VERSION ""

NS_ :

BS_:

BU_: BCM NAB NVO SGW

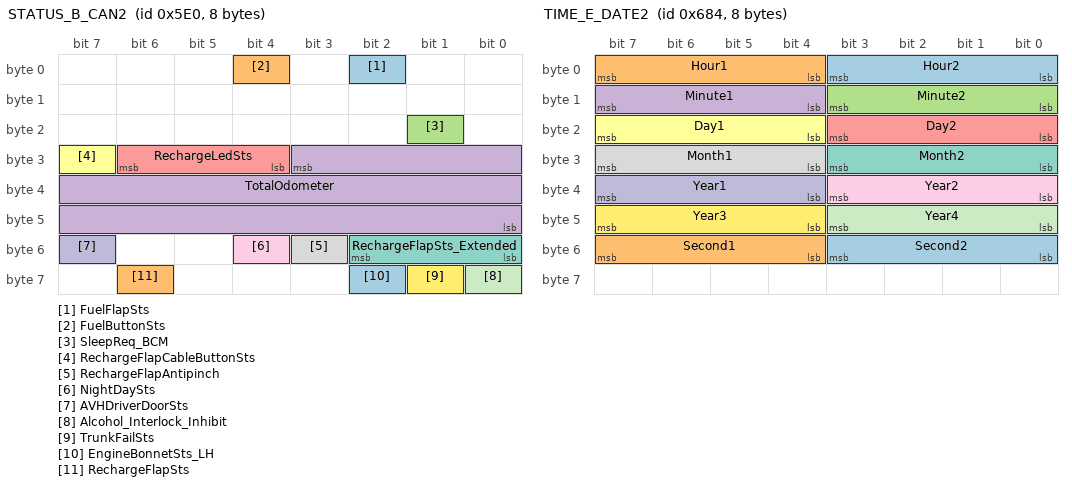
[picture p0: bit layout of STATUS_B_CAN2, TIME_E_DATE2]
BO_ 1504 STATUS_B_CAN2: 8 BCM
  SG_ FuelFlapSts : 2|1@0+ (1,0) [0|1] "" SGW
  SG_ FuelButtonSts : 4|1@0+ (1,0) [0|1] "" SGW
  SG_ SleepReq_BCM : 17|1@0+ (1,0) [0|1] "" SGW
  SG_ TotalOdometer : 27|20@0+ (1,0) [0|999999] "km" SGW
  SG_ RechargeLedSts : 30|3@0+ (1,0) [0|7] "" SGW
  SG_ RechargeFlapCableButtonSts : 31|1@0+ (1,0) [0|1] "" SGW
  SG_ RechargeFlapSts_Extended : 50|3@0+ (1,0) [0|7] "" SGW
  SG_ RechargeFlapAntipinch : 51|1@0+ (1,0) [0|1] "" SGW
  SG_ NightDaySts : 52|1@0+ (1,0) [0|1] "" SGW
  SG_ AVHDriverDoorSts : 55|1@0+ (1,0) [0|1] "" SGW
  SG_ Alcohol_Interlock_Inhibit : 56|1@0+ (1,0) [0|1] "" SGW
  SG_ TrunkFailSts : 57|1@0+ (1,0) [0|1] "" SGW
  SG_ EngineBonnetSts_LH : 58|1@0+ (1,0) [0|1] "" SGW
  SG_ RechargeFlapSts : 62|1@0+ (1,0) [0|1] "" SGW

BO_ 1530 STATUS_C_LCU: 8 SGW
  SG_ GenericFailSts : 0|1@0+ (1,0) [0|1] "" BCM
  SG_ CurrentFailSts : 1|1@0+ (1,0) [0|1] "" BCM
  SG_ EOL : 2|1@0+ (1,0) [0|1] "" BCM
  SG_ D_ES : 4|2@0+ (1,0) [0|3] "" BCM
  SG_ Left_LB_Feedback : 8|1@0+ (1,0) [0|1] "" BCM
  SG_ LCUFailSts : 9|1@0+ (1,0) [0|1] "" BCM
  SG_ Right_PL_FailSts : 10|1@0+ (1,0) [0|1] "" BCM
  SG_ Left_PL_FailSts : 11|1@0+ (1,0) [0|1] "" BCM
  SG_ Right_DRL_Feedback : 12|1@0+ (1,0) [0|1] "" BCM
  SG_ Left_DRL_Feedback : 13|1@0+ (1,0) [0|1] "" BCM
  SG_ Right_PL_Feedback : 14|1@0+ (1,0) [0|1] "" BCM
  SG_ Left_PL_Feedback : 15|1@0+ (1,0) [0|1] "" BCM
  SG_ Left_HB_Feedback : 16|1@0+ (1,0) [0|1] "" BCM
  SG_ LVL_FailSts : 17|1@0+ (1,0) [0|1] "" BCM
  SG_ FBLFailSts : 18|1@0+ (1,0) [0|1] "" BCM
  SG_ Comp_HBFailSts : 19|1@0+ (1,0) [0|1] "" BCM
  SG_ ADB_FailSts : 20|1@0+ (1,0) [0|1] "" BCM
  SG_ Right_LB_FailSts : 21|1@0+ (1,0) [0|1] "" BCM
  SG_ Left_LB_FailSts : 22|1@0+ (1,0) [0|1] "" BCM
  SG_ Right_LB_Feedback : 23|1@0+ (1,0) [0|1] "" BCM
  SG_ Left_DRL_FailSts : 24|1@0+ (1,0) [0|1] "" BCM
  SG_ Right_TI_FailSts : 25|1@0+ (1,0) [0|1] "" BCM
  SG_ Left_TI_FailSts : 26|1@0+ (1,0) [0|1] "" BCM
  SG_ Right_TI_Feedback : 27|1@0+ (1,0) [0|1] "" BCM
  SG_ Left_TI_Feedback : 28|1@0+ (1,0) [0|1] "" BCM
  SG_ Right_HB_FailSts : 29|1@0+ (1,0) [0|1] "" BCM
  SG_ Left_HB_FailSts : 30|1@0+ (1,0) [0|1] "" BCM
  SG_ Right_HB_Feedback : 31|1@0+ (1,0) [0|1] "" BCM
  SG_ TrafficChangeFbk : 37|2@0+ (1,0) [0|3] "" BCM
  SG_ ParkingLight_Feedback : 38|1@0+ (1,0) [0|1] "" BCM
  SG_ Right_DRL_FailSts : 39|1@0+ (1,0) [0|1] "" BCM
  SG_ MsgCounter_LCUSts : 51|4@0+ (1,0) [0|15] "" BCM
  SG_ Checksum_LCUSts : 63|8@0+ (1,0) [0|255] "" BCM

BO_ 1539 TRIP_A_E_B: 8 SGW
  SG_ TotalOdometer : 11|20@0+ (1,0) [0|999999] "km" NAB,NVO

BO_ 1668 TIME_E_DATE2: 8 SGW
  SG_ Hour2 : 3|4@0+ (1,0) [0|9] "" NAB
  SG_ Hour1 : 7|4@0+ (1,0) [0|9] "" NAB
  SG_ Minute2 : 11|4@0+ (1,0) [0|9] "" NAB
  SG_ Minute1 : 15|4@0+ (1,0) [0|9] "" NAB
  SG_ Day2 : 19|4@0+ (1,0) [0|9] "" NAB
  SG_ Day1 : 23|4@0+ (1,0) [0|9] "" NAB
  SG_ Month2 : 27|4@0+ (1,0) [0|9] "" NAB
  SG_ Month1 : 31|4@0+ (1,0) [0|9] "" NAB
  SG_ Year2 : 35|4@0+ (1,0) [0|9] "" NAB
  SG_ Year1 : 39|4@0+ (1,0) [0|9] "" NAB
  SG_ Year4 : 43|4@0+ (1,0) [0|9] "" NAB
  SG_ Year3 : 47|4@0+ (1,0) [0|9] "" NAB
  SG_ Second2 : 51|4@0+ (1,0) [0|9] "" NAB
  SG_ Second1 : 55|4@0+ (1,0) [0|9] "" NAB

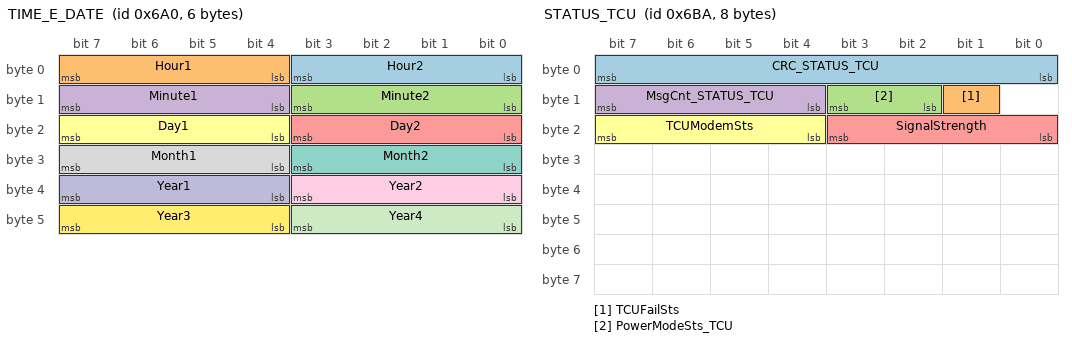
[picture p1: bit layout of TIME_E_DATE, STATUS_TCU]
BO_ 1696 TIME_E_DATE: 6 SGW
  SG_ Hour2 : 3|4@0+ (1,0) [0|9] "" BCM,NVO
  SG_ Hour1 : 7|4@0+ (1,0) [0|9] "" BCM,NVO
  SG_ Minute2 : 11|4@0+ (1,0) [0|9] "" BCM,NVO
  SG_ Minute1 : 15|4@0+ (1,0) [0|9] "" BCM,NVO
  SG_ Day2 : 19|4@0+ (1,0) [0|9] "" BCM,NVO
  SG_ Day1 : 23|4@0+ (1,0) [0|9] "" BCM,NVO
  SG_ Month2 : 27|4@0+ (1,0) [0|9] "" BCM,NVO
  SG_ Month1 : 31|4@0+ (1,0) [0|9] "" BCM,NVO
  SG_ Year2 : 35|4@0+ (1,0) [0|9] "" BCM,NVO
  SG_ Year1 : 39|4@0+ (1,0) [0|9] "" BCM,NVO
  SG_ Year4 : 43|4@0+ (1,0) [0|9] "" BCM,NVO
  SG_ Year3 : 47|4@0+ (1,0) [0|9] "" BCM,NVO

BO_ 1722 STATUS_TCU: 8 SGW
  SG_ CRC_STATUS_TCU : 7|8@0+ (1,0) [0|255] "" BCM
  SG_ TCUFailSts : 9|1@0+ (1,0) [0|1] "" Vector__XXX
  SG_ PowerModeSts_TCU : 11|2@0+ (1,0) [0|3] "" BCM
  SG_ MsgCnt_STATUS_TCU : 15|4@0+ (1,0) [0|14] "" BCM
  SG_ SignalStrength : 19|4@0+ (1,0) [0|15] "" Vector__XXX
  SG_ TCUModemSts : 23|4@0+ (1,0) [0|15] "" Vector__XXX

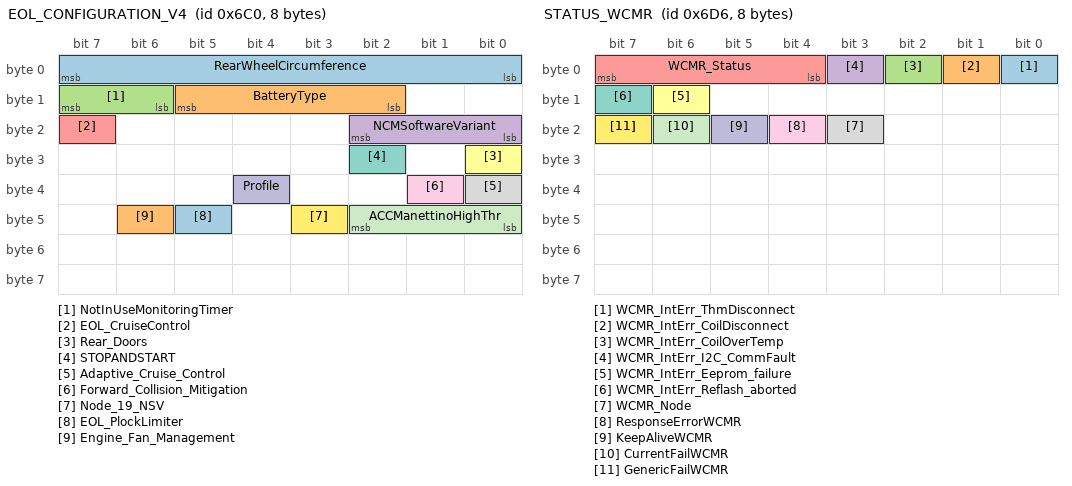
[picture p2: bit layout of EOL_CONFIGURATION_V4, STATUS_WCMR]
BO_ 1728 EOL_CONFIGURATION_V4: 8 BCM
  SG_ RearWheelCircumference : 7|8@0+ (5,1440) [1440|2715] "mm" SGW
  SG_ BatteryType : 13|4@0+ (1,0) [0|15] "" SGW
  SG_ NotInUseMonitoringTimer : 15|2@0+ (10,10) [10|40] "minutes" SGW
  SG_ NCMSoftwareVariant : 18|3@0+ (1,0) [0|7] "" SGW
  SG_ EOL_CruiseControl : 23|1@0+ (1,0) [0|1] "" SGW
  SG_ Rear_Doors : 24|1@0+ (1,0) [0|1] "" SGW
  SG_ STOPANDSTART : 26|1@0+ (1,0) [0|1] "" SGW
  SG_ Adaptive_Cruise_Control : 32|1@0+ (1,0) [0|1] "" SGW
  SG_ Forward_Collision_Mitigation : 33|1@0+ (1,0) [0|1] "" SGW
  SG_ Profile : 36|1@0+ (1,0) [0|1] "" SGW
  SG_ ACCManettinoHighThr : 42|3@0+ (1,0) [0|7] "count" SGW
  SG_ Node_19_NSV : 43|1@0+ (1,0) [0|1] "" SGW
  SG_ EOL_PlockLimiter : 45|1@0+ (1,0) [0|1] "" SGW
  SG_ Engine_Fan_Management : 46|1@0+ (1,0) [0|1] "" SGW

BO_ 1750 STATUS_WCMR: 8 SGW
  SG_ WCMR_IntErr_ThmDisconnect : 0|1@0+ (1,0) [0|1] "" Vector__XXX
  SG_ WCMR_IntErr_CoilDisconnect : 1|1@0+ (1,0) [0|1] "" Vector__XXX
  SG_ WCMR_IntErr_CoilOverTemp : 2|1@0+ (1,0) [0|1] "" Vector__XXX
  SG_ WCMR_IntErr_I2C_CommFault : 3|1@0+ (1,0) [0|1] "" Vector__XXX
  SG_ WCMR_Status : 7|4@0+ (1,0) [0|15] "" BCM
  SG_ WCMR_IntErr_Eeprom_failure : 14|1@0+ (1,0) [0|1] "" Vector__XXX
  SG_ WCMR_IntErr_Reflash_aborted : 15|1@0+ (1,0) [0|1] "" Vector__XXX
  SG_ WCMR_Node : 19|1@0+ (1,0) [0|1] "" Vector__XXX
  SG_ ResponseErrorWCMR : 20|1@0+ (1,0) [0|1] "" Vector__XXX
  SG_ KeepAliveWCMR : 21|1@0+ (1,0) [0|1] "" Vector__XXX
  SG_ CurrentFailWCMR : 22|1@0+ (1,0) [0|1] "" Vector__XXX
  SG_ GenericFailWCMR : 23|1@0+ (1,0) [0|1] "" Vector__XXX

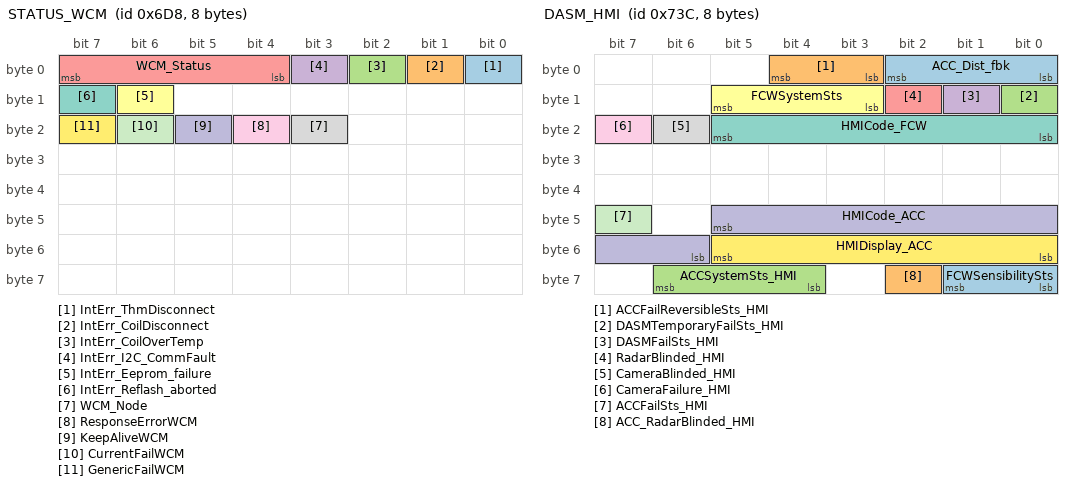
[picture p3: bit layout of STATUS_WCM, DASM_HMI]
BO_ 1752 STATUS_WCM: 8 SGW
  SG_ IntErr_ThmDisconnect : 0|1@0+ (1,0) [0|1] "" Vector__XXX
  SG_ IntErr_CoilDisconnect : 1|1@0+ (1,0) [0|1] "" Vector__XXX
  SG_ IntErr_CoilOverTemp : 2|1@0+ (1,0) [0|1] "" Vector__XXX
  SG_ IntErr_I2C_CommFault : 3|1@0+ (1,0) [0|1] "" Vector__XXX
  SG_ WCM_Status : 7|4@0+ (1,0) [0|15] "" BCM
  SG_ IntErr_Eeprom_failure : 14|1@0+ (1,0) [0|1] "" Vector__XXX
  SG_ IntErr_Reflash_aborted : 15|1@0+ (1,0) [0|1] "" Vector__XXX
  SG_ WCM_Node : 19|1@0+ (1,0) [0|1] "" Vector__XXX
  SG_ ResponseErrorWCM : 20|1@0+ (1,0) [0|1] "" Vector__XXX
  SG_ KeepAliveWCM : 21|1@0+ (1,0) [0|1] "" Vector__XXX
  SG_ CurrentFailWCM : 22|1@0+ (1,0) [0|1] "" Vector__XXX
  SG_ GenericFailWCM : 23|1@0+ (1,0) [0|1] "" Vector__XXX

BO_ 1852 DASM_HMI: 8 SGW
  SG_ ACC_Dist_fbk : 2|3@0+ (1,0) [0|7] "" Vector__XXX
  SG_ ACCFailReversibleSts_HMI : 4|2@0+ (1,0) [0|3] "" Vector__XXX
  SG_ DASMTemporaryFailSts_HMI : 8|1@0+ (1,0) [0|1] "" Vector__XXX
  SG_ DASMFailSts_HMI : 9|1@0+ (1,0) [0|1] "" Vector__XXX
  SG_ RadarBlinded_HMI : 10|1@0+ (1,0) [0|1] "" Vector__XXX
  SG_ FCWSystemSts : 13|3@0+ (1,0) [0|7] "" NAB
  SG_ HMICode_FCW : 21|6@0+ (1,0) [0|63] "" Vector__XXX
  SG_ CameraBlinded_HMI : 22|1@0+ (1,0) [0|1] "" Vector__XXX
  SG_ CameraFailure_HMI : 23|1@0+ (1,0) [0|1] "" Vector__XXX
  SG_ HMICode_ACC : 45|8@0+ (1,0) [0|255] "" Vector__XXX
  SG_ ACCFailSts_HMI : 47|1@0+ (1,0) [0|1] "" Vector__XXX
  SG_ HMIDisplay_ACC : 53|6@0+ (1,0) [0|63] "" Vector__XXX
  SG_ FCWSensibilitySts : 57|2@0+ (1,0) [0|3] "" Vector__XXX
  SG_ ACC_RadarBlinded_HMI : 58|1@0+ (1,0) [0|1] "" Vector__XXX
  SG_ ACCSystemSts_HMI : 62|3@0+ (1,0) [0|7] "" Vector__XXX

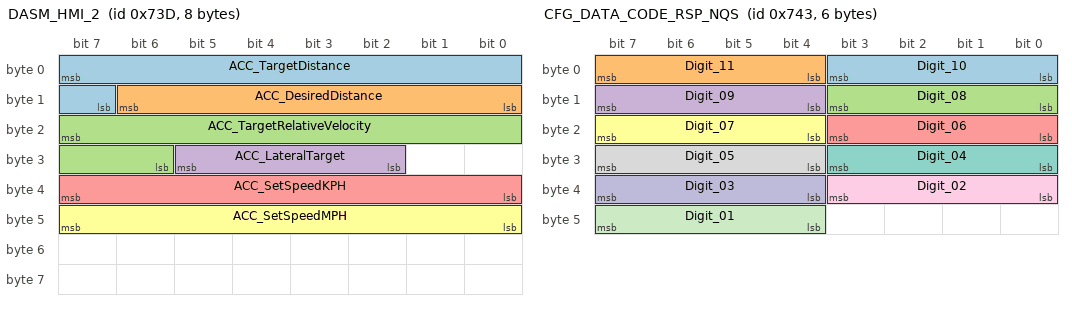
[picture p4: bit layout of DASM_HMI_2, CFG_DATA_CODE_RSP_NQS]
BO_ 1853 DASM_HMI_2: 8 SGW
  SG_ ACC_TargetDistance : 7|9@0+ (1,0) [0|511] "" Vector__XXX
  SG_ ACC_DesiredDistance : 14|7@0+ (1,0) [0|127] "" Vector__XXX
  SG_ ACC_TargetRelativeVelocity : 23|10@0+ (0.25,-128) [-128|127.75] "m/s" Vector__XXX
  SG_ ACC_LateralTarget : 29|4@0+ (1,0) [0|15] "" Vector__XXX
  SG_ ACC_SetSpeedKPH : 39|8@0+ (1,0) [0|255] "Kph" Vector__XXX
  SG_ ACC_SetSpeedMPH : 47|8@0+ (1,0) [0|255] "mph" Vector__XXX

BO_ 1859 CFG_DATA_CODE_RSP_NQS: 6 SGW
  SG_ Digit_10 : 3|4@0+ (1,0) [0|15] "" BCM
  SG_ Digit_11 : 7|4@0+ (1,0) [0|15] "" BCM
  SG_ Digit_08 : 11|4@0+ (1,0) [0|15] "" BCM
  SG_ Digit_09 : 15|4@0+ (1,0) [0|15] "" BCM
  SG_ Digit_06 : 19|4@0+ (1,0) [0|15] "" BCM
  SG_ Digit_07 : 23|4@0+ (1,0) [0|15] "" BCM
  SG_ Digit_04 : 27|4@0+ (1,0) [0|15] "" BCM
  SG_ Digit_05 : 31|4@0+ (1,0) [0|15] "" BCM
  SG_ Digit_02 : 35|4@0+ (1,0) [0|15] "" BCM
  SG_ Digit_03 : 39|4@0+ (1,0) [0|15] "" BCM
  SG_ Digit_01 : 47|4@0+ (1,0) [0|15] "" BCM

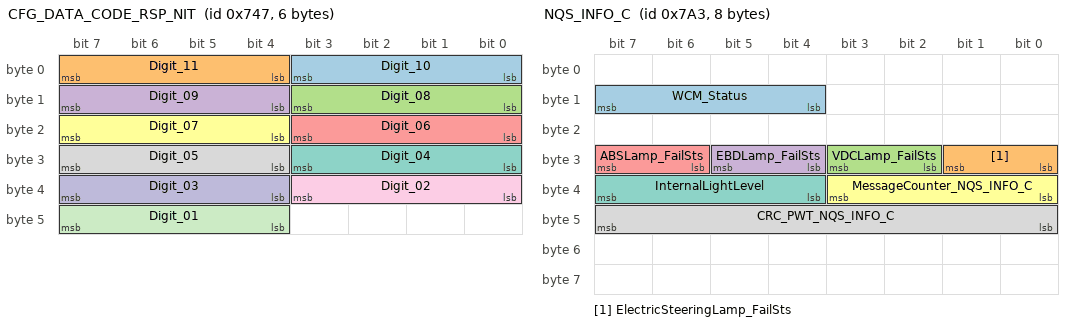
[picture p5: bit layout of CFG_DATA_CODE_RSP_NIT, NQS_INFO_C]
BO_ 1863 CFG_DATA_CODE_RSP_NIT: 6 SGW
  SG_ Digit_10 : 3|4@0+ (1,0) [0|15] "" BCM
  SG_ Digit_11 : 7|4@0+ (1,0) [0|15] "" BCM
  SG_ Digit_08 : 11|4@0+ (1,0) [0|15] "" BCM
  SG_ Digit_09 : 15|4@0+ (1,0) [0|15] "" BCM
  SG_ Digit_06 : 19|4@0+ (1,0) [0|15] "" BCM
  SG_ Digit_07 : 23|4@0+ (1,0) [0|15] "" BCM
  SG_ Digit_04 : 27|4@0+ (1,0) [0|15] "" BCM
  SG_ Digit_05 : 31|4@0+ (1,0) [0|15] "" BCM
  SG_ Digit_02 : 35|4@0+ (1,0) [0|15] "" BCM
  SG_ Digit_03 : 39|4@0+ (1,0) [0|15] "" BCM
  SG_ Digit_01 : 47|4@0+ (1,0) [0|15] "" BCM

BO_ 1955 NQS_INFO_C: 8 SGW
  SG_ WCM_Status : 15|4@0+ (1,0) [0|15] "" BCM
  SG_ ElectricSteeringLamp_FailSts : 25|2@0+ (1,0) [0|3] "" BCM
  SG_ VDCLamp_FailSts : 27|2@0+ (1,0) [0|3] "" BCM
  SG_ EBDLamp_FailSts : 29|2@0+ (1,0) [0|3] "" BCM
  SG_ ABSLamp_FailSts : 31|2@0+ (1,0) [0|3] "" BCM
  SG_ MessageCounter_NQS_INFO_C : 35|4@0+ (1,0) [0|15] "" BCM
  SG_ InternalLightLevel : 39|4@0+ (1,0) [0|15] "" BCM
  SG_ CRC_PWT_NQS_INFO_C : 47|8@0+ (1,0) [0|255] "" BCM

BO_ 2564440305 UDS_SGW_BCM_PhyReq_Data: 8 SGW
  SG_ UDS_SGW_BCM_PhysReq_Data : 7|64@0+ (1,0) [0|1.84467440737096E+19] "" BCM

BO_ 2564452593 UDS_SGW_WLMR_PhyReq_Data: 8 SGW
  SG_ UDS_SGW_WLMR_PhyReq_Data : 7|64@0+ (1,0) [0|1.84467440737096E+19] "" BCM

BO_ 2564452849 UDS_SGW_WLML_PhyReq_Data: 8 SGW
  SG_ UDS_SGW_WLML_PhyReq_Data : 7|64@0+ (1,0) [0|1.84467440737096E+19] "" BCM

BO_ 2564456177 UDS_SGW_WSM_PhyReq_Data: 8 SGW
  SG_ UDS_SGW_WSM_PhyReq_Data : 7|64@0+ (1,0) [0|1.84467440737096E+19] "" BCM

BO_ 2564460785 UDS_SGW_NPE_PhyReq_Data: 8 SGW
  SG_ UDS_SGW_NPE_PhyReq_Data : 7|64@0+ (1,0) [0|1.84467440737096E+19] "" BCM

BO_ 2564461041 UDS_SGW_WLRL_PhyReq_Data: 8 SGW
  SG_ UDS_SGW_WLRL_PhyReq_Data : 7|64@0+ (1,0) [0|1.84467440737096E+19] "" BCM

BO_ 2564461297 UDS_SGW_WLRR_PhyReq_Data: 8 SGW
  SG_ UDS_SGW_WLRR_PhyReq_Data : 7|64@0+ (1,0) [0|1.84467440737096E+19] "" BCM

BO_ 2564465905 UDS_SGW_MCR_PhyReq_Data: 8 SGW
  SG_ UDS_SGW_MCR_PhysReq_Data : 7|64@0+ (1,0) [0|1.84467440737096E+19] "" BCM

BO_ 2564466161 UDS_SGW_MCL_PhyReq_Data: 8 SGW
  SG_ UDS_SGW_MCL_PhysReq_Data : 7|64@0+ (1,0) [0|1.84467440737096E+19] "" BCM

BO_ 2564472561 UDS_SGW_WSMs_PhyReq_Data: 8 SGW
  SG_ UDS_SGW_WSMs_PhyReq_Data : 7|64@0+ (1,0) [0|1.84467440737096E+19] "" BCM

BO_ 2564473073 UDS_SGW_NAB_PhyReq_Data: 8 SGW
  SG_ UDS_SGW_NAB_PhysReq_Data : 7|64@0+ (1,0) [0|1.84467440737096E+19] "" NAB

BO_ 2564477425 UDS_SGW_NVD_PhyReq_Data: 8 SGW
  SG_ UDS_SGW_NVD_PhyReq_Data : 7|64@0+ (1,0) [0|1.84467440737096E+19] "" BCM

BO_ 2564478193 UDS_SGW_ALM_PhyReq_Data: 8 SGW
  SG_ UDS_SGW_ALM_PhysReq_Data : 7|64@0+ (1,0) [0|1.84467440737096E+19] "" BCM

BO_ 2564478449 UDS_SGW_LCC_PhyReq_Data: 8 SGW
  SG_ UDS_SGW_LCC_PhysReq_Data : 7|64@0+ (1,0) [0|1.84467440737096E+19] "" BCM

BO_ 2564478705 UDS_SGW_RLR_PhyReq_Data: 8 SGW
  SG_ UDS_SGW_RLR_PhyReq_Data : 7|64@0+ (1,0) [0|1.84467440737096E+19] "" BCM

BO_ 2564478961 UDS_SGW_RLL_PhyReq_Data: 8 SGW
  SG_ UDS_SGW_RLL_PhyReq_Data : 7|64@0+ (1,0) [0|1.84467440737096E+19] "" BCM

BO_ 2564481265 UDS_SGW_NCF_PhyReq_Data: 8 SGW
  SG_ UDS_SGW_NCF_PhyReq_Data : 7|64@0+ (1,0) [0|1.84467440737096E+19] "" BCM

BO_ 2564481521 UDS_SGW_MJC_PhyReq_Data: 8 SGW
  SG_ UDS_SGW_MJC_PhysReq_Data : 7|64@0+ (1,0) [0|1.84467440737096E+19] "" BCM

BO_ 2564485440 UDS_BCM_SGW_PhyRes_Data: 8 BCM
  SG_ UDS_BCM_SGW_PhyRes_Data : 7|64@0+ (1,0) [0|1.84467440737096E+19] "" SGW

BO_ 2564485488 UDS_WLMR_SGW_PhyRes_Data: 8 BCM
  SG_ UDS_WLMR_SGW_PhyRes_Data : 7|64@0+ (1,0) [0|1.84467440737096E+19] "" SGW

BO_ 2564485489 UDS_WLML_SGW_PhyRes_Data: 8 BCM
  SG_ UDS_WLML_SGW_PhyRes_Data : 7|64@0+ (1,0) [0|1.84467440737096E+19] "" SGW

BO_ 2564485502 UDS_WSM_SGW_PhyRes_Data: 8 BCM
  SG_ UDS_WSM_SGW_PhyRes_Data : 7|64@0+ (1,0) [0|1.84467440737096E+19] "" SGW

BO_ 2564485520 UDS_NPE_SGW_PhyRes_Data: 8 BCM
  SG_ UDS_NPE_SGW_PhyRes_Data : 7|64@0+ (1,0) [0|1.84467440737096E+19] "" SGW

BO_ 2564485521 UDS_WLRL_SGW_PhyRes_Data: 8 BCM
  SG_ UDS_WLRL_SGW_PhyRes_Data : 7|64@0+ (1,0) [0|1.84467440737096E+19] "" SGW

BO_ 2564485522 UDS_WLRR_SGW_PhyRes_Data: 8 BCM
  SG_ UDS_WLRR_SGW_PhyRes_Data : 7|64@0+ (1,0) [0|1.84467440737096E+19] "" SGW

BO_ 2564485540 UDS_MCR_SGW_PhyRes_Data: 8 BCM
  SG_ UDS_MCR_SGW_PhyRes_Data : 7|64@0+ (1,0) [0|1.84467440737096E+19] "" SGW

BO_ 2564485541 UDS_MCL_SGW_PhyRes_Data: 8 BCM
  SG_ UDS_MCL_SGW_PhyRes_Data : 7|64@0+ (1,0) [0|1.84467440737096E+19] "" SGW

BO_ 2564485566 UDS_WSMs_SGW_PhyRes_Data: 8 BCM
  SG_ UDS_WSMs_SGW_PhyRes_Data : 7|64@0+ (1,0) [0|1.84467440737096E+19] "" SGW

BO_ 2564485568 UDS_NAB_SGW_PhyRes_Data: 8 NAB
  SG_ UDS_NAB_SGW_PhyRes_Data : 7|64@0+ (1,0) [0|1.84467440737096E+19] "" SGW

BO_ 2564485585 UDS_NVD_SGW_PhyRes_Data: 8 BCM
  SG_ UDS_NVD_SGW_PhyRes_Data : 7|64@0+ (1,0) [0|1.84467440737096E+19] "" SGW

BO_ 2564485588 UDS_ALM_SGW_PhyRes_Data: 8 BCM
  SG_ UDS_ALM_SGW_PhyRes_Data : 7|64@0+ (1,0) [0|1.84467440737096E+19] "" SGW

BO_ 2564485589 UDS_LCC_SGW_PhyRes_Data: 8 BCM
  SG_ UDS_LCC_SGW_PhyRes_Data : 7|64@0+ (1,0) [0|1.84467440737096E+19] "" SGW

BO_ 2564485590 UDS_RLR_SGW_PhyRes_Data: 8 BCM
  SG_ UDS_RLR_SGW_PhyRes_Data : 7|64@0+ (1,0) [0|1.84467440737096E+19] "" SGW

BO_ 2564485591 UDS_RLL_SGW_PhyRes_Data: 8 BCM
  SG_ UDS_RLL_SGW_PhyRes_Data : 7|64@0+ (1,0) [0|1.84467440737096E+19] "" SGW

BO_ 2564485600 UDS_NCF_SGW_PhyRes_Data: 8 BCM
  SG_ UDS_NCF_SGW_PhyRes_Data : 7|64@0+ (1,0) [0|1.84467440737096E+19] "" SGW

BO_ 2564485601 UDS_MJC_SGW_PhyRes_Data: 8 BCM
  SG_ UDS_MJC_SGW_PhyRes_Data : 7|64@0+ (1,0) [0|1.84467440737096E+19] "" SGW

BO_ 2564554481 UDS_SGW_to_ALL_Func_Data: 8 SGW
  SG_ UDS_OBD_to_ALL_FunctionalRequest : 7|64@0+ (1,0) [0|1.84467440737096E+19] "" BCM,NAB

BO_ 2564554737 EDR_DIAG_DATA_REQ: 8 SGW
  SG_ TPDU_EDRDATAREQ : 7|64@0+ (1,0) [0|1.84467440737096E+19] "" NAB

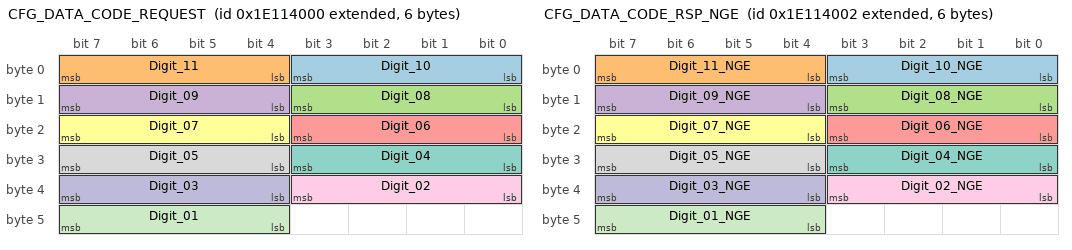
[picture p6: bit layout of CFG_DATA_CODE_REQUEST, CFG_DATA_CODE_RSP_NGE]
BO_ 2651930624 CFG_DATA_CODE_REQUEST: 6 BCM
  SG_ Digit_10 : 3|4@0+ (1,0) [0|15] "" NAB,SGW
  SG_ Digit_11 : 7|4@0+ (1,0) [0|15] "" NAB,SGW
  SG_ Digit_08 : 11|4@0+ (1,0) [0|15] "" NAB,SGW
  SG_ Digit_09 : 15|4@0+ (1,0) [0|15] "" NAB,SGW
  SG_ Digit_06 : 19|4@0+ (1,0) [0|15] "" NAB,SGW
  SG_ Digit_07 : 23|4@0+ (1,0) [0|15] "" NAB,SGW
  SG_ Digit_04 : 27|4@0+ (1,0) [0|15] "" NAB,SGW
  SG_ Digit_05 : 31|4@0+ (1,0) [0|15] "" NAB,SGW
  SG_ Digit_02 : 35|4@0+ (1,0) [0|15] "" NAB,SGW
  SG_ Digit_03 : 39|4@0+ (1,0) [0|15] "" NAB,SGW
  SG_ Digit_01 : 47|4@0+ (1,0) [0|15] "" NAB,SGW

BO_ 2651930626 CFG_DATA_CODE_RSP_NGE: 6 SGW
  SG_ Digit_10_NGE : 3|4@0+ (1,0) [0|15] "" BCM
  SG_ Digit_11_NGE : 7|4@0+ (1,0) [0|15] "" BCM
  SG_ Digit_08_NGE : 11|4@0+ (1,0) [0|15] "" BCM
  SG_ Digit_09_NGE : 15|4@0+ (1,0) [0|15] "" BCM
  SG_ Digit_06_NGE : 19|4@0+ (1,0) [0|15] "" BCM
  SG_ Digit_07_NGE : 23|4@0+ (1,0) [0|15] "" BCM
  SG_ Digit_04_NGE : 27|4@0+ (1,0) [0|15] "" BCM
  SG_ Digit_05_NGE : 31|4@0+ (1,0) [0|15] "" BCM
  SG_ Digit_02_NGE : 35|4@0+ (1,0) [0|15] "" BCM
  SG_ Digit_03_NGE : 39|4@0+ (1,0) [0|15] "" BCM
  SG_ Digit_01_NGE : 47|4@0+ (1,0) [0|15] "" BCM

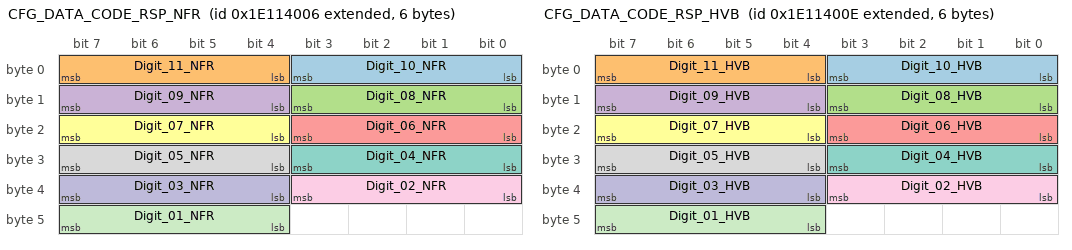
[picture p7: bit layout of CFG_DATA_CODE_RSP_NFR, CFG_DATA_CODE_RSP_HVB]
BO_ 2651930630 CFG_DATA_CODE_RSP_NFR: 6 SGW
  SG_ Digit_10_NFR : 3|4@0+ (1,0) [0|15] "" BCM
  SG_ Digit_11_NFR : 7|4@0+ (1,0) [0|15] "" BCM
  SG_ Digit_08_NFR : 11|4@0+ (1,0) [0|15] "" BCM
  SG_ Digit_09_NFR : 15|4@0+ (1,0) [0|15] "" BCM
  SG_ Digit_06_NFR : 19|4@0+ (1,0) [0|15] "" BCM
  SG_ Digit_07_NFR : 23|4@0+ (1,0) [0|15] "" BCM
  SG_ Digit_04_NFR : 27|4@0+ (1,0) [0|15] "" BCM
  SG_ Digit_05_NFR : 31|4@0+ (1,0) [0|15] "" BCM
  SG_ Digit_02_NFR : 35|4@0+ (1,0) [0|15] "" BCM
  SG_ Digit_03_NFR : 39|4@0+ (1,0) [0|15] "" BCM
  SG_ Digit_01_NFR : 47|4@0+ (1,0) [0|15] "" BCM

BO_ 2651930638 CFG_DATA_CODE_RSP_HVB: 6 SGW
  SG_ Digit_10_HVB : 3|4@0+ (1,0) [0|15] "" BCM
  SG_ Digit_11_HVB : 7|4@0+ (1,0) [0|15] "" BCM
  SG_ Digit_08_HVB : 11|4@0+ (1,0) [0|15] "" BCM
  SG_ Digit_09_HVB : 15|4@0+ (1,0) [0|15] "" BCM
  SG_ Digit_06_HVB : 19|4@0+ (1,0) [0|15] "" BCM
  SG_ Digit_07_HVB : 23|4@0+ (1,0) [0|15] "" BCM
  SG_ Digit_04_HVB : 27|4@0+ (1,0) [0|15] "" BCM
  SG_ Digit_05_HVB : 31|4@0+ (1,0) [0|15] "" BCM
  SG_ Digit_02_HVB : 35|4@0+ (1,0) [0|15] "" BCM
  SG_ Digit_03_HVB : 39|4@0+ (1,0) [0|15] "" BCM
  SG_ Digit_01_HVB : 47|4@0+ (1,0) [0|15] "" BCM

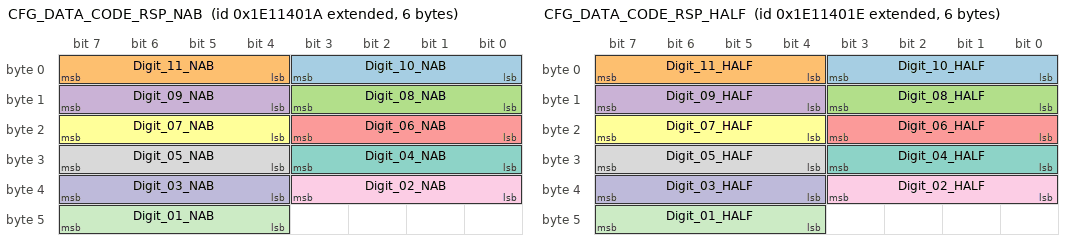
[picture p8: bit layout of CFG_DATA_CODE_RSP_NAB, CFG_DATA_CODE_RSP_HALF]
BO_ 2651930650 CFG_DATA_CODE_RSP_NAB: 6 NAB
  SG_ Digit_10_NAB : 3|4@0+ (1,0) [0|15] "" BCM
  SG_ Digit_11_NAB : 7|4@0+ (1,0) [0|15] "" BCM
  SG_ Digit_08_NAB : 11|4@0+ (1,0) [0|15] "" BCM
  SG_ Digit_09_NAB : 15|4@0+ (1,0) [0|15] "" BCM
  SG_ Digit_06_NAB : 19|4@0+ (1,0) [0|15] "" BCM
  SG_ Digit_07_NAB : 23|4@0+ (1,0) [0|15] "" BCM
  SG_ Digit_04_NAB : 27|4@0+ (1,0) [0|15] "" BCM
  SG_ Digit_05_NAB : 31|4@0+ (1,0) [0|15] "" BCM
  SG_ Digit_02_NAB : 35|4@0+ (1,0) [0|15] "" BCM
  SG_ Digit_03_NAB : 39|4@0+ (1,0) [0|15] "" BCM
  SG_ Digit_01_NAB : 47|4@0+ (1,0) [0|15] "" BCM

BO_ 2651930654 CFG_DATA_CODE_RSP_HALF: 6 SGW
  SG_ Digit_10_HALF : 3|4@0+ (1,0) [0|15] "" BCM
  SG_ Digit_11_HALF : 7|4@0+ (1,0) [0|15] "" BCM
  SG_ Digit_08_HALF : 11|4@0+ (1,0) [0|15] "" BCM
  SG_ Digit_09_HALF : 15|4@0+ (1,0) [0|15] "" BCM
  SG_ Digit_06_HALF : 19|4@0+ (1,0) [0|15] "" BCM
  SG_ Digit_07_HALF : 23|4@0+ (1,0) [0|15] "" BCM
  SG_ Digit_04_HALF : 27|4@0+ (1,0) [0|15] "" BCM
  SG_ Digit_05_HALF : 31|4@0+ (1,0) [0|15] "" BCM
  SG_ Digit_02_HALF : 35|4@0+ (1,0) [0|15] "" BCM
  SG_ Digit_03_HALF : 39|4@0+ (1,0) [0|15] "" BCM
  SG_ Digit_01_HALF : 47|4@0+ (1,0) [0|15] "" BCM

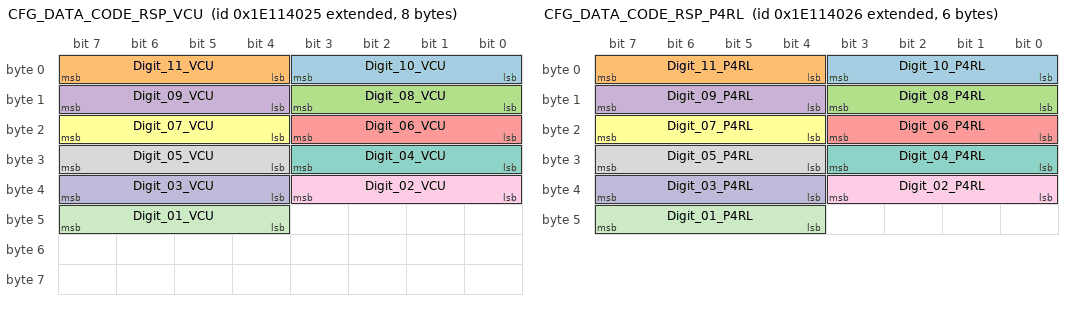
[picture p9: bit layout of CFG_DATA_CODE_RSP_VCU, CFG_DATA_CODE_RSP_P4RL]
BO_ 2651930661 CFG_DATA_CODE_RSP_VCU: 8 SGW
  SG_ Digit_10_VCU : 3|4@0+ (1,0) [0|15] "" BCM
  SG_ Digit_11_VCU : 7|4@0+ (1,0) [0|15] "" BCM
  SG_ Digit_08_VCU : 11|4@0+ (1,0) [0|15] "" BCM
  SG_ Digit_09_VCU : 15|4@0+ (1,0) [0|15] "" BCM
  SG_ Digit_06_VCU : 19|4@0+ (1,0) [0|15] "" BCM
  SG_ Digit_07_VCU : 23|4@0+ (1,0) [0|15] "" BCM
  SG_ Digit_04_VCU : 27|4@0+ (1,0) [0|15] "" BCM
  SG_ Digit_05_VCU : 31|4@0+ (1,0) [0|15] "" BCM
  SG_ Digit_02_VCU : 35|4@0+ (1,0) [0|15] "" BCM
  SG_ Digit_03_VCU : 39|4@0+ (1,0) [0|15] "" BCM
  SG_ Digit_01_VCU : 47|4@0+ (1,0) [0|15] "" BCM

BO_ 2651930662 CFG_DATA_CODE_RSP_P4RL: 6 SGW
  SG_ Digit_10_P4RL : 3|4@0+ (1,0) [0|15] "" BCM
  SG_ Digit_11_P4RL : 7|4@0+ (1,0) [0|15] "" BCM
  SG_ Digit_08_P4RL : 11|4@0+ (1,0) [0|15] "" BCM
  SG_ Digit_09_P4RL : 15|4@0+ (1,0) [0|15] "" BCM
  SG_ Digit_06_P4RL : 19|4@0+ (1,0) [0|15] "" BCM
  SG_ Digit_07_P4RL : 23|4@0+ (1,0) [0|15] "" BCM
  SG_ Digit_04_P4RL : 27|4@0+ (1,0) [0|15] "" BCM
  SG_ Digit_05_P4RL : 31|4@0+ (1,0) [0|15] "" BCM
  SG_ Digit_02_P4RL : 35|4@0+ (1,0) [0|15] "" BCM
  SG_ Digit_03_P4RL : 39|4@0+ (1,0) [0|15] "" BCM
  SG_ Digit_01_P4RL : 47|4@0+ (1,0) [0|15] "" BCM

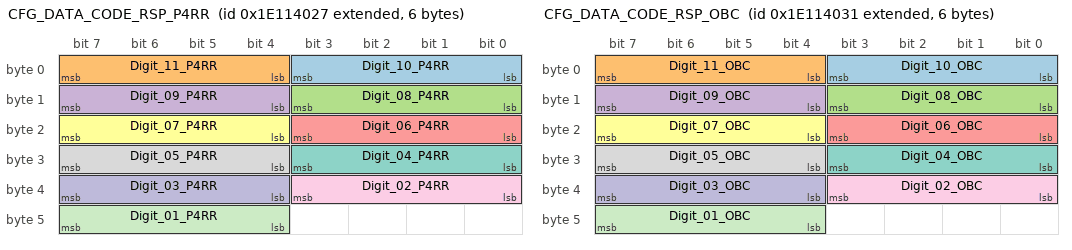
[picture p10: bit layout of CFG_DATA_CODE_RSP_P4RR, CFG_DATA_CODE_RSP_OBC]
BO_ 2651930663 CFG_DATA_CODE_RSP_P4RR: 6 SGW
  SG_ Digit_10_P4RR : 3|4@0+ (1,0) [0|15] "" BCM
  SG_ Digit_11_P4RR : 7|4@0+ (1,0) [0|15] "" BCM
  SG_ Digit_08_P4RR : 11|4@0+ (1,0) [0|15] "" BCM
  SG_ Digit_09_P4RR : 15|4@0+ (1,0) [0|15] "" BCM
  SG_ Digit_06_P4RR : 19|4@0+ (1,0) [0|15] "" BCM
  SG_ Digit_07_P4RR : 23|4@0+ (1,0) [0|15] "" BCM
  SG_ Digit_04_P4RR : 27|4@0+ (1,0) [0|15] "" BCM
  SG_ Digit_05_P4RR : 31|4@0+ (1,0) [0|15] "" BCM
  SG_ Digit_02_P4RR : 35|4@0+ (1,0) [0|15] "" BCM
  SG_ Digit_03_P4RR : 39|4@0+ (1,0) [0|15] "" BCM
  SG_ Digit_01_P4RR : 47|4@0+ (1,0) [0|15] "" BCM

BO_ 2651930673 CFG_DATA_CODE_RSP_OBC: 6 SGW
  SG_ Digit_10_OBC : 3|4@0+ (1,0) [0|15] "" BCM
  SG_ Digit_11_OBC : 7|4@0+ (1,0) [0|15] "" BCM
  SG_ Digit_08_OBC : 11|4@0+ (1,0) [0|15] "" BCM
  SG_ Digit_09_OBC : 15|4@0+ (1,0) [0|15] "" BCM
  SG_ Digit_06_OBC : 19|4@0+ (1,0) [0|15] "" BCM
  SG_ Digit_07_OBC : 23|4@0+ (1,0) [0|15] "" BCM
  SG_ Digit_04_OBC : 27|4@0+ (1,0) [0|15] "" BCM
  SG_ Digit_05_OBC : 31|4@0+ (1,0) [0|15] "" BCM
  SG_ Digit_02_OBC : 35|4@0+ (1,0) [0|15] "" BCM
  SG_ Digit_03_OBC : 39|4@0+ (1,0) [0|15] "" BCM
  SG_ Digit_01_OBC : 47|4@0+ (1,0) [0|15] "" BCM

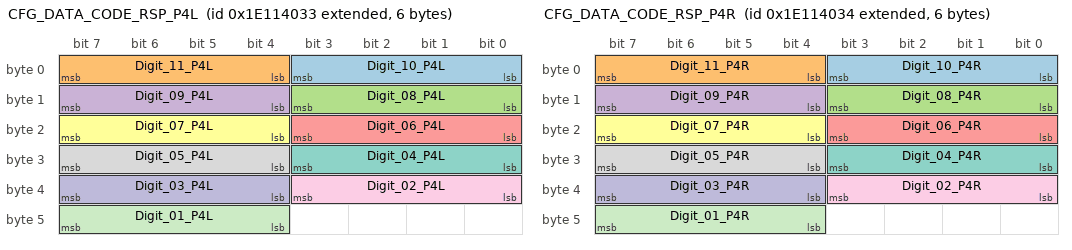
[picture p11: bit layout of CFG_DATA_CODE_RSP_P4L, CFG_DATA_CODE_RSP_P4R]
BO_ 2651930675 CFG_DATA_CODE_RSP_P4L: 6 SGW
  SG_ Digit_10_P4L : 3|4@0+ (1,0) [0|15] "" BCM
  SG_ Digit_11_P4L : 7|4@0+ (1,0) [0|15] "" BCM
  SG_ Digit_08_P4L : 11|4@0+ (1,0) [0|15] "" BCM
  SG_ Digit_09_P4L : 15|4@0+ (1,0) [0|15] "" BCM
  SG_ Digit_06_P4L : 19|4@0+ (1,0) [0|15] "" BCM
  SG_ Digit_07_P4L : 23|4@0+ (1,0) [0|15] "" BCM
  SG_ Digit_04_P4L : 27|4@0+ (1,0) [0|15] "" BCM
  SG_ Digit_05_P4L : 31|4@0+ (1,0) [0|15] "" BCM
  SG_ Digit_02_P4L : 35|4@0+ (1,0) [0|15] "" BCM
  SG_ Digit_03_P4L : 39|4@0+ (1,0) [0|15] "" BCM
  SG_ Digit_01_P4L : 47|4@0+ (1,0) [0|15] "" BCM

BO_ 2651930676 CFG_DATA_CODE_RSP_P4R: 6 SGW
  SG_ Digit_10_P4R : 3|4@0+ (1,0) [0|15] "" BCM
  SG_ Digit_11_P4R : 7|4@0+ (1,0) [0|15] "" BCM
  SG_ Digit_08_P4R : 11|4@0+ (1,0) [0|15] "" BCM
  SG_ Digit_09_P4R : 15|4@0+ (1,0) [0|15] "" BCM
  SG_ Digit_06_P4R : 19|4@0+ (1,0) [0|15] "" BCM
  SG_ Digit_07_P4R : 23|4@0+ (1,0) [0|15] "" BCM
  SG_ Digit_04_P4R : 27|4@0+ (1,0) [0|15] "" BCM
  SG_ Digit_05_P4R : 31|4@0+ (1,0) [0|15] "" BCM
  SG_ Digit_02_P4R : 35|4@0+ (1,0) [0|15] "" BCM
  SG_ Digit_03_P4R : 39|4@0+ (1,0) [0|15] "" BCM
  SG_ Digit_01_P4R : 47|4@0+ (1,0) [0|15] "" BCM

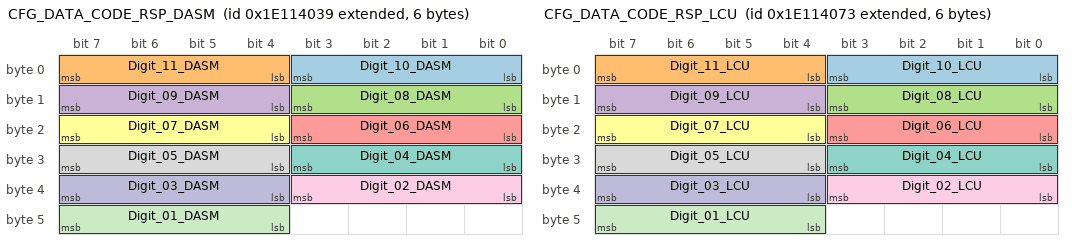
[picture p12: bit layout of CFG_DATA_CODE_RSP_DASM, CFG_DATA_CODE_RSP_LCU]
BO_ 2651930681 CFG_DATA_CODE_RSP_DASM: 6 SGW
  SG_ Digit_10_DASM : 3|4@0+ (1,0) [0|15] "" BCM
  SG_ Digit_11_DASM : 7|4@0+ (1,0) [0|15] "" BCM
  SG_ Digit_08_DASM : 11|4@0+ (1,0) [0|15] "" BCM
  SG_ Digit_09_DASM : 15|4@0+ (1,0) [0|15] "" BCM
  SG_ Digit_06_DASM : 19|4@0+ (1,0) [0|15] "" BCM
  SG_ Digit_07_DASM : 23|4@0+ (1,0) [0|15] "" BCM
  SG_ Digit_04_DASM : 27|4@0+ (1,0) [0|15] "" BCM
  SG_ Digit_05_DASM : 31|4@0+ (1,0) [0|15] "" BCM
  SG_ Digit_02_DASM : 35|4@0+ (1,0) [0|15] "" BCM
  SG_ Digit_03_DASM : 39|4@0+ (1,0) [0|15] "" BCM
  SG_ Digit_01_DASM : 47|4@0+ (1,0) [0|15] "" BCM

BO_ 2651930739 CFG_DATA_CODE_RSP_LCU: 6 SGW
  SG_ Digit_10_LCU : 3|4@0+ (1,0) [0|15] "" BCM
  SG_ Digit_11_LCU : 7|4@0+ (1,0) [0|15] "" BCM
  SG_ Digit_08_LCU : 11|4@0+ (1,0) [0|15] "" BCM
  SG_ Digit_09_LCU : 15|4@0+ (1,0) [0|15] "" BCM
  SG_ Digit_06_LCU : 19|4@0+ (1,0) [0|15] "" BCM
  SG_ Digit_07_LCU : 23|4@0+ (1,0) [0|15] "" BCM
  SG_ Digit_04_LCU : 27|4@0+ (1,0) [0|15] "" BCM
  SG_ Digit_05_LCU : 31|4@0+ (1,0) [0|15] "" BCM
  SG_ Digit_02_LCU : 35|4@0+ (1,0) [0|15] "" BCM
  SG_ Digit_03_LCU : 39|4@0+ (1,0) [0|15] "" BCM
  SG_ Digit_01_LCU : 47|4@0+ (1,0) [0|15] "" BCM

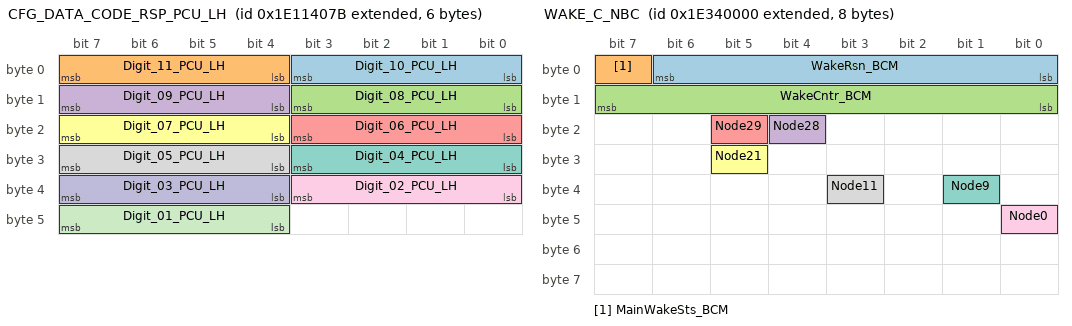
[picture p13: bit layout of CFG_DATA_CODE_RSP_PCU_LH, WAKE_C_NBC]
BO_ 2651930747 CFG_DATA_CODE_RSP_PCU_LH: 6 SGW
  SG_ Digit_10_PCU_LH : 3|4@0+ (1,0) [0|15] "" BCM
  SG_ Digit_11_PCU_LH : 7|4@0+ (1,0) [0|15] "" BCM
  SG_ Digit_08_PCU_LH : 11|4@0+ (1,0) [0|15] "" BCM
  SG_ Digit_09_PCU_LH : 15|4@0+ (1,0) [0|15] "" BCM
  SG_ Digit_06_PCU_LH : 19|4@0+ (1,0) [0|15] "" BCM
  SG_ Digit_07_PCU_LH : 23|4@0+ (1,0) [0|15] "" BCM
  SG_ Digit_04_PCU_LH : 27|4@0+ (1,0) [0|15] "" BCM
  SG_ Digit_05_PCU_LH : 31|4@0+ (1,0) [0|15] "" BCM
  SG_ Digit_02_PCU_LH : 35|4@0+ (1,0) [0|15] "" BCM
  SG_ Digit_03_PCU_LH : 39|4@0+ (1,0) [0|15] "" BCM
  SG_ Digit_01_PCU_LH : 47|4@0+ (1,0) [0|15] "" BCM

BO_ 2654208000 WAKE_C_NBC: 8 BCM
  SG_ WakeRsn_BCM : 6|7@0+ (1,0) [0|127] "" NAB,SGW
  SG_ MainWakeSts_BCM : 7|1@0+ (1,0) [0|1] "" NAB,SGW
  SG_ WakeCntr_BCM : 15|8@0+ (1,0) [0|255] "" NAB,SGW
  SG_ Node28 : 20|1@0+ (1,0) [0|1] "" SGW
  SG_ Node29 : 21|1@0+ (1,0) [0|1] "" SGW
  SG_ Node21 : 29|1@0+ (1,0) [0|1] "" SGW
  SG_ Node9 : 33|1@0+ (1,0) [0|1] "" NAB,SGW
  SG_ Node11 : 35|1@0+ (1,0) [0|1] "" SGW
  SG_ Node0 : 40|1@0+ (1,0) [0|1] "" NAB,SGW

BO_ 2654208003 WAKE_C_NQS: 4 SGW
  SG_ WakeRsn_NQS : 6|7@0+ (1,0) [0|127] "" BCM
  SG_ WakeReq_NQS : 7|1@0+ (1,0) [0|1] "" BCM
  SG_ WakeCntr_NQS : 15|8@0+ (1,0) [0|255] "" BCM
  SG_ WakeUpNodeAddress_NQS : 23|8@0+ (1,0) [0|255] "" BCM

BO_ 2654208005 WAKE_C_TCU: 4 SGW
  SG_ WakeRsn_TCU : 6|7@0+ (1,0) [0|127] "" BCM
  SG_ WakeReq_TCU : 7|1@0+ (1,0) [0|1] "" BCM
  SG_ WakeCntr_TCU : 15|8@0+ (1,0) [0|255] "" BCM
  SG_ WakeUpNodeAddress_TCU : 23|8@0+ (1,0) [0|255] "" BCM

BO_ 2654208007 WAKE_C_IDC: 4 SGW
  SG_ WakeRsn_NIT : 6|7@0+ (1,0) [0|127] "" BCM
  SG_ WakeReq_NIT : 7|1@0+ (1,0) [0|1] "" BCM
  SG_ WakeCntr_NIT : 15|8@0+ (1,0) [0|255] "" BCM
  SG_ WakeUpNodeAddress_NIT : 23|8@0+ (1,0) [0|255] "" BCM

BO_ 2654208026 WAKE_C_NAB: 4 NAB
  SG_ WakeRsn_NAB : 6|7@0+ (1,0) [0|127] "" BCM
  SG_ WakeReq_NAB : 7|1@0+ (1,0) [0|1] "" BCM
  SG_ WakeCntr_NAB : 15|8@0+ (1,0) [0|255] "" BCM
  SG_ WakeUpNodeAddress : 23|8@0+ (1,0) [0|255] "" BCM

BO_ 2654208028 WAKE_C_NTP: 4 SGW
  SG_ WakeRsn_NTP : 6|7@0+ (1,0) [0|127] "" BCM
  SG_ WakeReq_NTP : 7|1@0+ (1,0) [0|1] "" BCM
  SG_ WakeCntr_NTP : 15|8@0+ (1,0) [0|255] "" BCM
  SG_ WakeUpNodeAddress : 23|8@0+ (1,0) [0|255] "" BCM

BO_ 2654208037 WAKE_C_VCU: 4 SGW
  SG_ WakeRsn_VCU : 6|7@0+ (1,0) [0|127] "" BCM
  SG_ WakeReq_VCU : 7|1@0+ (1,0) [0|1] "" BCM
  SG_ WakeCntr_VCU : 15|8@0+ (1,0) [0|255] "" BCM
  SG_ WakeUpNodeAddress_VCU : 23|8@0+ (1,0) [0|255] "" BCM

BO_ 2654208041 WAKE_C_NDR: 4 SGW
  SG_ WakeRsn_NDR : 6|7@0+ (1,0) [0|127] "" BCM
  SG_ WakeReq_NDR : 7|1@0+ (1,0) [0|1] "" BCM
  SG_ WakeCntr_NDR : 15|8@0+ (1,0) [0|255] "" BCM
  SG_ WakeUpNodeAddress_NDR : 23|8@0+ (1,0) [0|255] "" BCM

BO_ 2654208084 WAKE_C_NDRR: 4 SGW
  SG_ WakeRsn_NDRR : 6|7@0+ (1,0) [0|127] "" BCM
  SG_ WakeReq_NDRR : 7|1@0+ (1,0) [0|1] "" BCM
  SG_ WakeCntr_NDRR : 15|8@0+ (1,0) [0|255] "" BCM
  SG_ WakeUpNodeAddress_NDRR : 23|8@0+ (1,0) [0|255] "" BCM

BO_ 2654208089 WAKE_C_SGW: 4 SGW
  SG_ WakeRsn_SGW : 6|7@0+ (1,0) [0|127] "" BCM
  SG_ WakeReq_SGW : 7|1@0+ (1,0) [0|1] "" BCM
  SG_ WakeCntr_SGW : 15|8@0+ (1,0) [0|255] "" BCM
  SG_ WakeUpNodeAddress_SGW : 23|8@0+ (1,0) [0|255] "" BCM

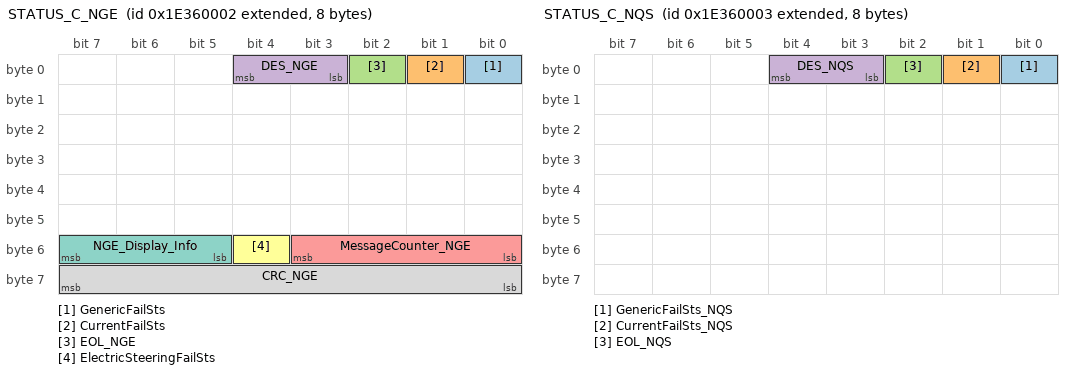
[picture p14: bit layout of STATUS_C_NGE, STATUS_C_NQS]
BO_ 2654339074 STATUS_C_NGE: 8 SGW
  SG_ GenericFailSts : 0|1@0+ (1,0) [0|1] "" BCM
  SG_ CurrentFailSts : 1|1@0+ (1,0) [0|1] "" BCM
  SG_ EOL_NGE : 2|1@0+ (1,0) [0|1] "" BCM
  SG_ DES_NGE : 4|2@0+ (1,0) [0|3] "" BCM
  SG_ MessageCounter_NGE : 51|4@0+ (1,0) [0|15] "" Vector__XXX
  SG_ ElectricSteeringFailSts : 52|1@0+ (1,0) [0|1] "" Vector__XXX
  SG_ NGE_Display_Info : 55|3@0+ (1,0) [0|7] "" Vector__XXX
  SG_ CRC_NGE : 63|8@0+ (1,0) [0|255] "" Vector__XXX

BO_ 2654339075 STATUS_C_NQS: 8 SGW
  SG_ GenericFailSts_NQS : 0|1@0+ (1,0) [0|1] "" BCM
  SG_ CurrentFailSts_NQS : 1|1@0+ (1,0) [0|1] "" BCM
  SG_ EOL_NQS : 2|1@0+ (1,0) [0|1] "" BCM
  SG_ DES_NQS : 4|2@0+ (1,0) [0|3] "" BCM

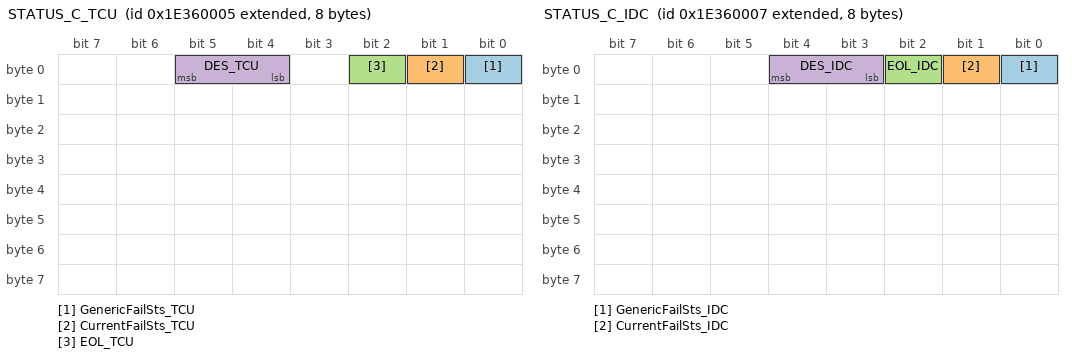
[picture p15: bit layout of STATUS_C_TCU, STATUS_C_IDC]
BO_ 2654339077 STATUS_C_TCU: 8 SGW
  SG_ GenericFailSts_TCU : 0|1@0+ (1,0) [0|1] "" BCM
  SG_ CurrentFailSts_TCU : 1|1@0+ (1,0) [0|1] "" BCM
  SG_ EOL_TCU : 2|1@0+ (1,0) [0|1] "" BCM
  SG_ DES_TCU : 5|2@0+ (1,0) [0|3] "" BCM

BO_ 2654339079 STATUS_C_IDC: 8 SGW
  SG_ GenericFailSts_IDC : 0|1@0+ (1,0) [0|1] "" BCM
  SG_ CurrentFailSts_IDC : 1|1@0+ (1,0) [0|1] "" BCM
  SG_ EOL_IDC : 2|1@0+ (1,0) [0|1] "" BCM
  SG_ DES_IDC : 4|2@0+ (1,0) [0|3] "" BCM

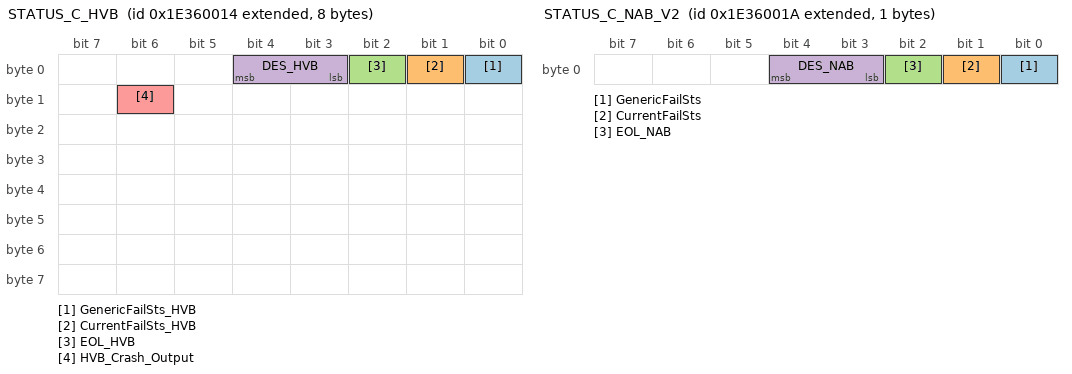
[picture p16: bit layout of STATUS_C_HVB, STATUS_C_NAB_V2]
BO_ 2654339092 STATUS_C_HVB: 8 SGW
  SG_ GenericFailSts_HVB : 0|1@0+ (1,0) [0|1] "" BCM
  SG_ CurrentFailSts_HVB : 1|1@0+ (1,0) [0|1] "" BCM
  SG_ EOL_HVB : 2|1@0+ (1,0) [0|1] "" BCM
  SG_ DES_HVB : 4|2@0+ (1,0) [0|3] "" BCM
  SG_ HVB_Crash_Output : 14|1@0+ (1,0) [0|1] "—" Vector__XXX

BO_ 2654339098 STATUS_C_NAB_V2: 1 NAB
  SG_ GenericFailSts : 0|1@0+ (1,0) [0|1] "" BCM
  SG_ CurrentFailSts : 1|1@0+ (1,0) [0|1] "" BCM
  SG_ EOL_NAB : 2|1@0+ (1,0) [0|1] "" BCM
  SG_ DES_NAB : 4|2@0+ (1,0) [0|3] "" BCM

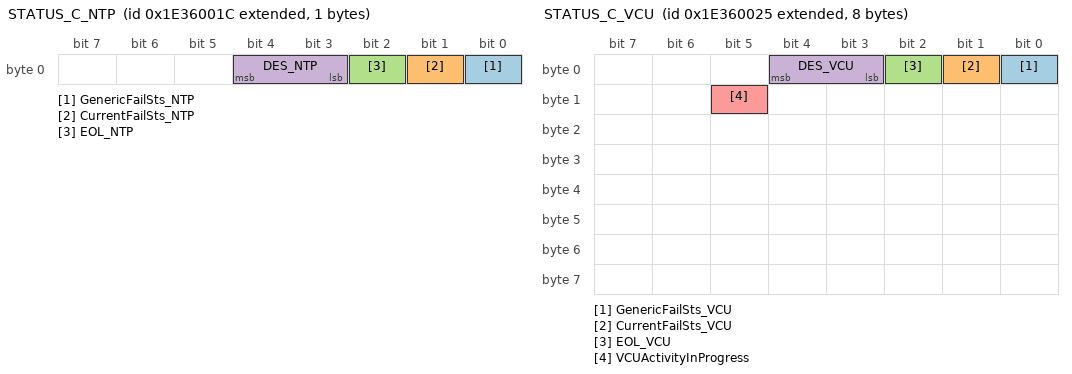
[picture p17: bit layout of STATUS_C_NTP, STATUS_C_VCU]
BO_ 2654339100 STATUS_C_NTP: 1 SGW
  SG_ GenericFailSts_NTP : 0|1@0+ (1,0) [0|1] "" BCM
  SG_ CurrentFailSts_NTP : 1|1@0+ (1,0) [0|1] "" BCM
  SG_ EOL_NTP : 2|1@0+ (1,0) [0|1] "" BCM
  SG_ DES_NTP : 4|2@0+ (1,0) [0|3] "" BCM

BO_ 2654339102 STATUS_C_HALF: 1 SGW
  SG_ GenericFailSts_HALF : 0|1@0+ (1,0) [0|1] "" BCM
  SG_ CurrentFailSts_HALF : 1|1@0+ (1,0) [0|1] "" BCM
  SG_ EOL_HALF : 2|1@0+ (1,0) [0|1] "" BCM
  SG_ DES_HALF : 4|2@0+ (1,0) [0|3] "" BCM

BO_ 2654339109 STATUS_C_VCU: 8 SGW
  SG_ GenericFailSts_VCU : 0|1@0+ (1,0) [0|1] "" BCM
  SG_ CurrentFailSts_VCU : 1|1@0+ (1,0) [0|1] "" BCM
  SG_ EOL_VCU : 2|1@0+ (1,0) [0|1] "" BCM
  SG_ DES_VCU : 4|2@0+ (1,0) [0|3] "" BCM
  SG_ VCUActivityInProgress : 13|1@0+ (1,0) [0|1] "" BCM

BO_ 2654339110 STATUS_C_P4RL: 8 SGW
  SG_ GenericFailSts_P4RL : 0|1@0+ (1,0) [0|1] "" BCM
  SG_ CurrentFailSts_P4RL : 1|1@0+ (1,0) [0|1] "" BCM
  SG_ EOL_P4RL : 2|1@0+ (1,0) [0|1] "" BCM
  SG_ DES_P4RL : 4|2@0+ (1,0) [0|3] "" BCM

BO_ 2654339111 STATUS_C_P4RR: 8 SGW
  SG_ GenericFailSts_P4RR : 0|1@0+ (1,0) [0|1] "" BCM
  SG_ CurrentFailSts_P4RR : 1|1@0+ (1,0) [0|1] "" BCM
  SG_ EOL_P4RR : 2|1@0+ (1,0) [0|1] "" BCM
  SG_ DES_P4RR : 4|2@0+ (1,0) [0|3] "" BCM

BO_ 2654339113 STATUS_C_NDR: 8 SGW
  SG_ GenericFailSts_NDR : 0|1@0+ (1,0) [0|1] "" BCM
  SG_ CurrentFailSts_NDR : 1|1@0+ (1,0) [0|1] "" BCM
  SG_ EOL_NDR : 2|1@0+ (1,0) [0|1] "" BCM
  SG_ DES_NDR : 4|2@0+ (1,0) [0|3] "" BCM

BO_ 2654339121 STATUS_C_OBC: 1 SGW
  SG_ GenericFailSts_OBC : 0|1@0+ (1,0) [0|1] "" BCM
  SG_ CurrentFailSts_OBC : 1|1@0+ (1,0) [0|1] "" BCM
  SG_ EOL_OBC : 2|1@0+ (1,0) [0|1] "" BCM
  SG_ DES_OBC : 4|2@0+ (1,0) [0|3] "" BCM

BO_ 2654339123 STATUS_C_P4L: 8 SGW
  SG_ GenericFailSts_P4L : 0|1@0+ (1,0) [0|1] "" BCM
  SG_ CurrentFailSts_P4L : 1|1@0+ (1,0) [0|1] "" BCM
  SG_ EOL_P4L : 2|1@0+ (1,0) [0|1] "" BCM
  SG_ DES_P4L : 4|2@0+ (1,0) [0|3] "" BCM

BO_ 2654339124 STATUS_C_P4R: 8 SGW
  SG_ GenericFailSts_P4R : 0|1@0+ (1,0) [0|1] "" BCM
  SG_ CurrentFailSts_P4R : 1|1@0+ (1,0) [0|1] "" BCM
  SG_ EOL_P4R : 2|1@0+ (1,0) [0|1] "" BCM
  SG_ DES_P4R : 4|2@0+ (1,0) [0|3] "" BCM

BO_ 2654339129 STATUS_C_DASM: 1 SGW
  SG_ GenericFailSts_DASM : 0|1@0+ (1,0) [0|1] "" BCM
  SG_ CurrentFailSts_DASM : 1|1@0+ (1,0) [0|1] "" BCM
  SG_ EOL_DASM : 2|1@0+ (1,0) [0|1] "" BCM
  SG_ DES_DASM : 4|2@0+ (1,0) [0|3] "" BCM

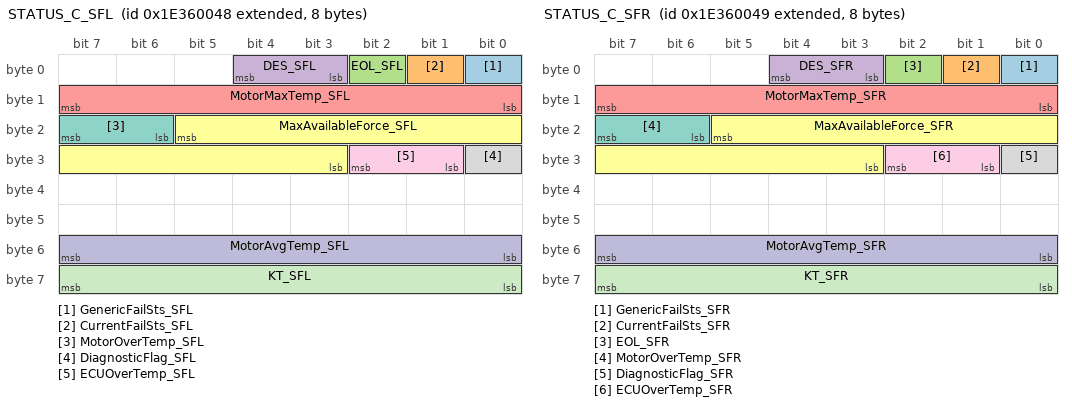
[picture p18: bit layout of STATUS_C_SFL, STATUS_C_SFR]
BO_ 2654339144 STATUS_C_SFL: 8 SGW
  SG_ GenericFailSts_SFL : 0|1@0+ (1,0) [0|1] "" BCM
  SG_ CurrentFailSts_SFL : 1|1@0+ (1,0) [0|1] "" BCM
  SG_ EOL_SFL : 2|1@0+ (1,0) [0|1] "" BCM
  SG_ DES_SFL : 4|2@0+ (1,0) [0|3] "" BCM
  SG_ MotorMaxTemp_SFL : 15|8@0+ (1,-40) [-40|215] "°C" BCM
  SG_ MaxAvailableForce_SFL : 21|11@0+ (5,0) [0|10000] "N" BCM
  SG_ MotorOverTemp_SFL : 23|2@0+ (1,0) [0|3] "" BCM
  SG_ DiagnosticFlag_SFL : 24|1@0+ (1,0) [0|1] "" BCM
  SG_ ECUOverTemp_SFL : 26|2@0+ (1,0) [0|3] "" BCM
  SG_ MotorAvgTemp_SFL : 55|8@0+ (1,-40) [-40|215] "°C" BCM
  SG_ KT_SFL : 63|8@0+ (0.1,80) [80|105.5] "mNm/A" BCM

BO_ 2654339145 STATUS_C_SFR: 8 SGW
  SG_ GenericFailSts_SFR : 0|1@0+ (1,0) [0|1] "" BCM
  SG_ CurrentFailSts_SFR : 1|1@0+ (1,0) [0|1] "" BCM
  SG_ EOL_SFR : 2|1@0+ (1,0) [0|1] "" BCM
  SG_ DES_SFR : 4|2@0+ (1,0) [0|3] "" BCM
  SG_ MotorMaxTemp_SFR : 15|8@0+ (1,-40) [-40|215] "°C" BCM
  SG_ MaxAvailableForce_SFR : 21|11@0+ (5,0) [0|10000] "N" BCM
  SG_ MotorOverTemp_SFR : 23|2@0+ (1,0) [0|3] "" BCM
  SG_ DiagnosticFlag_SFR : 24|1@0+ (1,0) [0|1] "" BCM
  SG_ ECUOverTemp_SFR : 26|2@0+ (1,0) [0|3] "" BCM
  SG_ MotorAvgTemp_SFR : 55|8@0+ (1,-40) [-40|215] "°C" BCM
  SG_ KT_SFR : 63|8@0+ (0.1,80) [80|105.5] "mNm/A" BCM

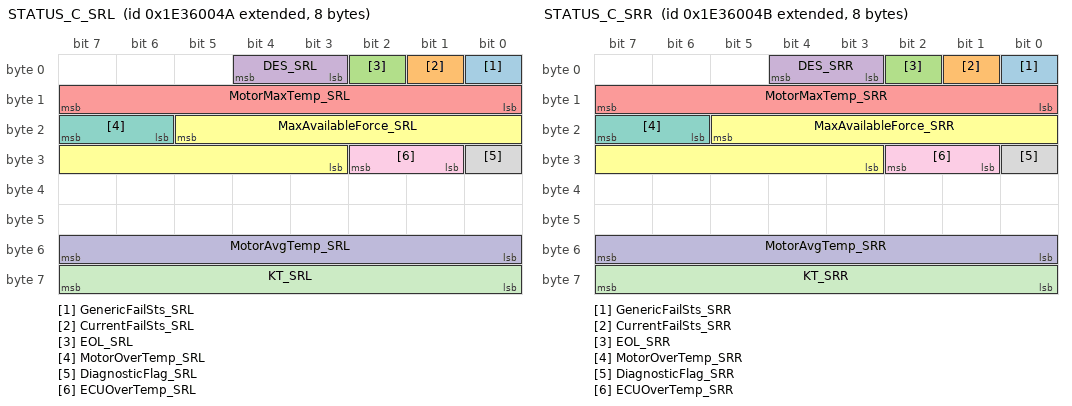
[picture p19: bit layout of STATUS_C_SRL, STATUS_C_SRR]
BO_ 2654339146 STATUS_C_SRL: 8 SGW
  SG_ GenericFailSts_SRL : 0|1@0+ (1,0) [0|1] "" BCM
  SG_ CurrentFailSts_SRL : 1|1@0+ (1,0) [0|1] "" BCM
  SG_ EOL_SRL : 2|1@0+ (1,0) [0|1] "" BCM
  SG_ DES_SRL : 4|2@0+ (1,0) [0|3] "" BCM
  SG_ MotorMaxTemp_SRL : 15|8@0+ (1,-40) [-40|215] "°C" BCM
  SG_ MaxAvailableForce_SRL : 21|11@0+ (5,0) [0|10000] "N" BCM
  SG_ MotorOverTemp_SRL : 23|2@0+ (1,0) [0|3] "" BCM
  SG_ DiagnosticFlag_SRL : 24|1@0+ (1,0) [0|1] "" BCM
  SG_ ECUOverTemp_SRL : 26|2@0+ (1,0) [0|3] "" BCM
  SG_ MotorAvgTemp_SRL : 55|8@0+ (1,-40) [-40|215] "°C" BCM
  SG_ KT_SRL : 63|8@0+ (0.1,80) [80|105.5] "mNm/A" BCM

BO_ 2654339147 STATUS_C_SRR: 8 SGW
  SG_ GenericFailSts_SRR : 0|1@0+ (1,0) [0|1] "" BCM
  SG_ CurrentFailSts_SRR : 1|1@0+ (1,0) [0|1] "" BCM
  SG_ EOL_SRR : 2|1@0+ (1,0) [0|1] "" BCM
  SG_ DES_SRR : 4|2@0+ (1,0) [0|3] "" BCM
  SG_ MotorMaxTemp_SRR : 15|8@0+ (1,-40) [-40|215] "°C" BCM
  SG_ MaxAvailableForce_SRR : 21|11@0+ (5,0) [0|10000] "N" BCM
  SG_ MotorOverTemp_SRR : 23|2@0+ (1,0) [0|3] "" BCM
  SG_ DiagnosticFlag_SRR : 24|1@0+ (1,0) [0|1] "" BCM
  SG_ ECUOverTemp_SRR : 26|2@0+ (1,0) [0|3] "" BCM
  SG_ MotorAvgTemp_SRR : 55|8@0+ (1,-40) [-40|215] "°C" BCM
  SG_ KT_SRR : 63|8@0+ (0.1,80) [80|105.5] "mNm/A" BCM

BO_ 2654339156 STATUS_C_NDRR: 8 SGW
  SG_ GenericFailSts_NDRR : 0|1@0+ (1,0) [0|1] "" BCM
  SG_ CurrentFailSts_NDRR : 1|1@0+ (1,0) [0|1] "" BCM
  SG_ EOL_NDRR : 2|1@0+ (1,0) [0|1] "" BCM
  SG_ DES_NDRR : 4|2@0+ (1,0) [0|3] "" BCM

BO_ 2654339161 STATUS_C_SGW: 8 SGW
  SG_ GenericFailSts_SGW : 0|1@0+ (1,0) [0|1] "" BCM
  SG_ CurrentFailSts_SGW : 1|1@0+ (1,0) [0|1] "" BCM
  SG_ EOL_SGW : 2|1@0+ (1,0) [0|1] "" BCM
  SG_ DES_SGW : 4|2@0+ (1,0) [0|3] "" BCM

BO_ 2654339182 STATUS_C_FAUF: 8 SGW
  SG_ GenericFailSts_FAUF : 0|1@0+ (1,0) [0|1] "" BCM
  SG_ CurrentFailSts_FAUF : 1|1@0+ (1,0) [0|1] "" BCM
  SG_ EOL_FAUF : 2|1@0+ (1,0) [0|1] "" BCM
  SG_ DES_FAUF : 4|2@0+ (1,0) [0|3] "" BCM

BO_ 2654339183 STATUS_C_FAUR: 8 SGW
  SG_ GenericFailSts_FAUR : 0|1@0+ (1,0) [0|1] "" BCM
  SG_ CurrentFailSts_FAUR : 1|1@0+ (1,0) [0|1] "" BCM
  SG_ EOL_FAUR : 2|1@0+ (1,0) [0|1] "" BCM
  SG_ DES_FAUR : 4|2@0+ (1,0) [0|3] "" BCM

BO_ 2654339195 STATUS_C_PCU2: 1 SGW
  SG_ GenericFailSts_PCU_LH : 0|1@0+ (1,0) [0|1] "" BCM
  SG_ CurrentFailSts_PCU_LH : 1|1@0+ (1,0) [0|1] "" BCM
  SG_ EOL_PCU_LH : 2|1@0+ (1,0) [0|1] "" BCM
  SG_ DES_PCU_LH : 4|2@0+ (1,0) [0|3] "" BCM

BO_ 2654339197 STATUS_C_BES: 1 SGW
  SG_ GenericFailSts_BES : 0|1@0+ (1,0) [0|1] "" BCM
  SG_ CurrentFailSts_BES : 1|1@0+ (1,0) [0|1] "" BCM
  SG_ EOL_BES : 2|1@0+ (1,0) [0|1] "" BCM
  SG_ D_ES_BES : 4|2@0+ (1,0) [0|3] "" BCM

BO_ 2658971643 ECU_APPL_NPE: 8 BCM
  SG_ ECU_APPL_NPE : 7|64@0+ (1,0) [0|1.84467440737096E+19] "" Vector__XXX

CM_ BO_ 2654339144 "used to ASC functionality";
CM_ BO_ 2654339145 "used to ASC functionality";
CM_ BO_ 2654339146 "used to ASC functionality";
CM_ BO_ 2654339147 "used to ASC functionality";
CM_ SG_ 1504 AVHDriverDoorSts "Sent by the body Computer that read directly the door ajar switch";
CM_ SG_ 1530 MsgCounter_LCUSts "SAE J1850";
CM_ SG_ 1530 Checksum_LCUSts "SAE J1850";
CM_ SG_ 1668 Hour2 "BCD CODED";
CM_ SG_ 1668 Hour1 "BCD CODED";
CM_ SG_ 1668 Minute2 "BCD CODED";
CM_ SG_ 1668 Minute1 "BCD CODED";
CM_ SG_ 1668 Day2 "BCD CODED";
CM_ SG_ 1668 Day1 "BCD CODED";
CM_ SG_ 1668 Month2 "BCD CODED";
CM_ SG_ 1668 Month1 "BCD CODED";
CM_ SG_ 1668 Year2 "BCD CODED";
CM_ SG_ 1668 Year1 "BCD CODED";
CM_ SG_ 1668 Year4 "BCD CODED";
CM_ SG_ 1668 Year3 "BCD CODED";
CM_ SG_ 1668 Second2 "BCD CODED";
CM_ SG_ 1668 Second1 "BCD CODED";
CM_ SG_ 1696 Hour2 "BCD CODED 
Hour always in 24 format";
CM_ SG_ 1696 Hour1 "BCD CODED 
Hour always in 24 format";
CM_ SG_ 1696 Minute2 "BCD CODED";
CM_ SG_ 1696 Minute1 "BCD CODED";
CM_ SG_ 1696 Day2 "BCD CODED";
CM_ SG_ 1696 Day1 "BCD CODED";
CM_ SG_ 1696 Month2 "BCD CODED";
CM_ SG_ 1696 Month1 "BCD CODED";
CM_ SG_ 1696 Year2 "BCD CODED";
CM_ SG_ 1696 Year1 "BCD CODED";
CM_ SG_ 1696 Year4 "BCD CODED";
CM_ SG_ 1696 Year3 "BCD CODED";
CM_ SG_ 1728 RearWheelCircumference "NFR USED THIS VALUE TO CALCULATE THE VSO SIGNAL, IN CASE OF WHEEL SPEED SENSOR ERROR , NFR WILL USE THE INTERNAL WHEEL CIRCUMFERENCE . ";
CM_ SG_ 1728 BatteryType "PROXI byte 87, bit 0-3";
CM_ SG_ 1728 NCMSoftwareVariant "Only for F149 and F142 the Variant 0 and Variant 4 are not available because invalid selection on NBC.
For F151 and F152 Variant 0 and 4 are allowed.";
CM_ SG_ 1728 Rear_Doors "{For F175: Sig_name = Rear_Doors}";
CM_ SG_ 1728 STOPANDSTART "The signal indicates the Stop&Start presence";
CM_ SG_ 1752 IntErr_ThmDisconnect "Failure of temp sensors";
CM_ SG_ 1752 IntErr_CoilDisconnect "Charging coil has been disconnected from main board; Error=[1]";
CM_ SG_ 1752 IntErr_CoilOverTemp "WCPM has Overheated;  Error=[1]";
CM_ SG_ 1752 IntErr_I2C_CommFault "Communication failure on internal I2C bus;  Error=[1]";
CM_ SG_ 1752 IntErr_Eeprom_failure "Failed to access the Memory";
CM_ SG_ 1752 IntErr_Reflash_aborted "Failure during reflashing (CRC error)";
CM_ SG_ 1852 HMICode_ACC "Value dec 66 - ACC_LONG_PRESS_TO_ENA_NEEDED is valid only from DASM Gen5";
CM_ SG_ 1859 Digit_10 "BCD CODED";
CM_ SG_ 1859 Digit_11 "(MSB) BCD CODED";
CM_ SG_ 1859 Digit_08 "BCD CODED";
CM_ SG_ 1859 Digit_09 "BCD CODED";
CM_ SG_ 1859 Digit_06 "BCD CODED";
CM_ SG_ 1859 Digit_07 "BCD CODED";
CM_ SG_ 1859 Digit_04 "BCD CODED";
CM_ SG_ 1859 Digit_05 "BCD CODED";
CM_ SG_ 1859 Digit_02 "BCD CODED";
CM_ SG_ 1859 Digit_03 "BCD CODED";
CM_ SG_ 1859 Digit_01 "(LSB) BCD CODED";
CM_ SG_ 1863 Digit_10 "BCD CODED";
CM_ SG_ 1863 Digit_11 "(MSB) BCD CODED";
CM_ SG_ 1863 Digit_08 "BCD CODED";
CM_ SG_ 1863 Digit_09 "BCD CODED";
CM_ SG_ 1863 Digit_06 "BCD CODED";
CM_ SG_ 1863 Digit_07 "BCD CODED";
CM_ SG_ 1863 Digit_04 "BCD CODED";
CM_ SG_ 1863 Digit_05 "BCD CODED";
CM_ SG_ 1863 Digit_02 "BCD CODED";
CM_ SG_ 1863 Digit_03 "BCD CODED";
CM_ SG_ 1863 Digit_01 "(LSB) BCD CODED";

BA_DEF_ SG_  "GenSigSendType" ENUM "NotUsed","OnWrite","OnWriteWithRepetition","OnChange","OnChangeWithRepetition","IfActive","IfActiveWithRepetition","NoSigSendType";
BA_DEF_ SG_  "GenSigInactiveValue" INT 0 2147483647;
BA_DEF_ SG_  "GenSigStartValue" INT 0 2147483647;
BA_DEF_ BO_  "DiagState" ENUM "No","Yes";
BA_DEF_ BO_  "GenMsgDelayTime" INT 0 65535;
BA_DEF_ BO_  "GenMsgCycleTimeFast" INT 0 65535;
BA_DEF_ BO_  "GenMsgStartDelayTime" INT 0 65535;
BA_DEF_ BO_  "GenMsgILSupport" ENUM "No","Yes";
BA_DEF_ BO_  "GenMsgTimeoutTime" INT 0 10000;
BA_DEF_ BO_  "GenMsgSendType" ENUM "Cyclic","NotUsed","NotUsed","NotUsed","NotUsed","NotUsed","NotUsed","NotUsed","NoMsgSendType";
BA_DEF_ BO_  "NmMessage" ENUM "No","Yes";
BA_DEF_ BO_  "Type" ENUM "P","C","PE","COC","PE_Cntrl","E","E_Cntrl","OC","S","BAF","DC","EM","MM","-";
BA_DEF_ BO_  "Period" INT 0 65535;
BA_DEF_ SG_  "EventTrans" ENUM "Yes","No";
BA_DEF_ SG_  "Accuracy" STRING;
BA_DEF_ SG_  "SignalAge" INT 0 100000;
BA_DEF_ SG_  "InitialValue" INT -65536 65535;
BA_DEF_ BO_  "DiagResponse" ENUM "No","Yes";
BA_DEF_ BO_  "DiagRequest" ENUM "No","Yes";
BA_DEF_ BO_  "GenMsgCycleTime" INT 0 10000;
BA_DEF_DEF_  "DiagRequest" "No";
BA_DEF_DEF_  "DiagResponse" "No";
BA_DEF_DEF_  "DiagState" "No";
BA_DEF_DEF_  "EventTrans" "No";
BA_DEF_DEF_  "GenMsgCycleTime" 0;
BA_DEF_DEF_  "GenMsgCycleTimeFast" 0;
BA_DEF_DEF_  "GenMsgDelayTime" 0;
BA_DEF_DEF_  "GenMsgILSupport" "No";
BA_DEF_DEF_  "GenMsgSendType" "NoMsgSendType";
BA_DEF_DEF_  "GenMsgStartDelayTime" 0;
BA_DEF_DEF_  "GenMsgTimeoutTime" 0;
BA_DEF_DEF_  "GenSigInactiveValue" 0;
BA_DEF_DEF_  "GenSigSendType" "NoSigSendType";
BA_DEF_DEF_  "GenSigStartValue" 0;
BA_DEF_DEF_  "InitialValue" 0;
BA_DEF_DEF_  "NmMessage" "No";
BA_DEF_DEF_  "Period" 0;
BA_DEF_DEF_  "SignalAge" 0;
BA_DEF_DEF_  "Type" "-";
BA_ "GenMsgCycleTime" BO_ 1504 100;
BA_ "GenMsgDelayTime" BO_ 1504 10;
BA_ "GenMsgILSupport" BO_ 1504 1;
BA_ "GenMsgSendType" BO_ 1504 0;
BA_ "GenMsgStartDelayTime" BO_ 1504 10;
BA_ "GenMsgTimeoutTime" BO_ 1504 2500;
BA_ "Period" BO_ 1504 100;
BA_ "Type" BO_ 1504 1;
BA_ "GenMsgCycleTime" BO_ 1530 100;
BA_ "GenMsgILSupport" BO_ 1530 1;
BA_ "GenMsgSendType" BO_ 1530 0;
BA_ "GenMsgTimeoutTime" BO_ 1530 2500;
BA_ "Period" BO_ 1530 100;
BA_ "Type" BO_ 1530 3;
BA_ "GenMsgCycleTime" BO_ 1539 1000;
BA_ "GenMsgILSupport" BO_ 1539 1;
BA_ "GenMsgSendType" BO_ 1539 0;
BA_ "GenMsgTimeoutTime" BO_ 1539 2500;
BA_ "Period" BO_ 1539 1000;
BA_ "Type" BO_ 1539 3;
BA_ "GenMsgCycleTime" BO_ 1668 250;
BA_ "GenMsgILSupport" BO_ 1668 1;
BA_ "GenMsgSendType" BO_ 1668 0;
BA_ "GenMsgTimeoutTime" BO_ 1668 2500;
BA_ "Period" BO_ 1668 250;
BA_ "Type" BO_ 1668 1;
BA_ "GenMsgCycleTime" BO_ 1696 1000;
BA_ "GenMsgDelayTime" BO_ 1696 10;
BA_ "GenMsgILSupport" BO_ 1696 1;
BA_ "GenMsgSendType" BO_ 1696 0;
BA_ "GenMsgTimeoutTime" BO_ 1696 2500;
BA_ "Period" BO_ 1696 1000;
BA_ "Type" BO_ 1696 3;
BA_ "GenMsgCycleTime" BO_ 1722 250;
BA_ "GenMsgILSupport" BO_ 1722 1;
BA_ "GenMsgSendType" BO_ 1722 0;
BA_ "GenMsgTimeoutTime" BO_ 1722 2500;
BA_ "Period" BO_ 1722 250;
BA_ "Type" BO_ 1722 1;
BA_ "GenMsgCycleTime" BO_ 1728 1000;
BA_ "GenMsgILSupport" BO_ 1728 1;
BA_ "GenMsgSendType" BO_ 1728 0;
BA_ "GenMsgTimeoutTime" BO_ 1728 2500;
BA_ "Period" BO_ 1728 1000;
BA_ "Type" BO_ 1728 1;
BA_ "GenMsgCycleTime" BO_ 1750 500;
BA_ "GenMsgILSupport" BO_ 1750 1;
BA_ "GenMsgSendType" BO_ 1750 0;
BA_ "GenMsgTimeoutTime" BO_ 1750 2500;
BA_ "Period" BO_ 1750 500;
BA_ "Type" BO_ 1750 1;
BA_ "GenMsgCycleTime" BO_ 1752 500;
BA_ "GenMsgILSupport" BO_ 1752 1;
BA_ "GenMsgSendType" BO_ 1752 0;
BA_ "GenMsgTimeoutTime" BO_ 1752 2500;
BA_ "Period" BO_ 1752 500;
BA_ "Type" BO_ 1752 1;
BA_ "GenMsgCycleTime" BO_ 1852 1000;
BA_ "GenMsgCycleTime" BO_ 1852 1000;
BA_ "GenMsgDelayTime" BO_ 1852 10;
BA_ "GenMsgDelayTime" BO_ 1852 10;
BA_ "GenMsgILSupport" BO_ 1852 1;
BA_ "GenMsgTimeoutTime" BO_ 1852 2500;
BA_ "Period" BO_ 1852 1000;
BA_ "Period" BO_ 1852 1000;
BA_ "Type" BO_ 1852 3;
BA_ "GenMsgCycleTime" BO_ 1853 100;
BA_ "GenMsgCycleTime" BO_ 1853 100;
BA_ "GenMsgDelayTime" BO_ 1853 10;
BA_ "GenMsgDelayTime" BO_ 1853 10;
BA_ "GenMsgILSupport" BO_ 1853 1;
BA_ "GenMsgTimeoutTime" BO_ 1853 2500;
BA_ "Period" BO_ 1853 100;
BA_ "Period" BO_ 1853 100;
BA_ "Type" BO_ 1853 1;
BA_ "GenMsgILSupport" BO_ 1859 1;
BA_ "GenMsgTimeoutTime" BO_ 1859 2500;
BA_ "Type" BO_ 1859 8;
BA_ "GenMsgILSupport" BO_ 1863 1;
BA_ "GenMsgTimeoutTime" BO_ 1863 2500;
BA_ "Type" BO_ 1863 8;
BA_ "GenMsgCycleTime" BO_ 1955 250;
BA_ "GenMsgILSupport" BO_ 1955 1;
BA_ "GenMsgSendType" BO_ 1955 0;
BA_ "GenMsgTimeoutTime" BO_ 1955 2500;
BA_ "Period" BO_ 1955 250;
BA_ "Type" BO_ 1955 3;
BA_ "DiagRequest" BO_ 2564440305 1;
BA_ "Type" BO_ 2564440305 8;
BA_ "DiagRequest" BO_ 2564452593 1;
BA_ "Type" BO_ 2564452593 8;
BA_ "DiagRequest" BO_ 2564452849 1;
BA_ "Type" BO_ 2564452849 8;
BA_ "DiagRequest" BO_ 2564456177 1;
BA_ "DiagRequest" BO_ 2564460785 1;
BA_ "Type" BO_ 2564460785 8;
BA_ "DiagRequest" BO_ 2564461041 1;
BA_ "DiagRequest" BO_ 2564461297 1;
BA_ "Type" BO_ 2564461297 8;
BA_ "DiagRequest" BO_ 2564465905 1;
BA_ "Type" BO_ 2564465905 8;
BA_ "DiagRequest" BO_ 2564466161 1;
BA_ "Type" BO_ 2564466161 8;
BA_ "DiagRequest" BO_ 2564472561 1;
BA_ "Type" BO_ 2564472561 8;
BA_ "DiagRequest" BO_ 2564473073 1;
BA_ "Type" BO_ 2564473073 8;
BA_ "DiagRequest" BO_ 2564477425 1;
BA_ "Type" BO_ 2564477425 8;
BA_ "DiagRequest" BO_ 2564478193 1;
BA_ "Type" BO_ 2564478193 8;
BA_ "DiagRequest" BO_ 2564478449 1;
BA_ "DiagRequest" BO_ 2564478705 1;
BA_ "Type" BO_ 2564478705 8;
BA_ "DiagRequest" BO_ 2564478961 1;
BA_ "Type" BO_ 2564478961 8;
BA_ "DiagRequest" BO_ 2564481265 1;
BA_ "DiagRequest" BO_ 2564481521 1;
BA_ "Type" BO_ 2564481521 8;
BA_ "DiagResponse" BO_ 2564485440 1;
BA_ "Type" BO_ 2564485440 8;
BA_ "DiagResponse" BO_ 2564485488 1;
BA_ "Type" BO_ 2564485488 8;
BA_ "DiagResponse" BO_ 2564485489 1;
BA_ "Type" BO_ 2564485489 8;
BA_ "DiagResponse" BO_ 2564485502 1;
BA_ "DiagResponse" BO_ 2564485520 1;
BA_ "Type" BO_ 2564485520 8;
BA_ "DiagResponse" BO_ 2564485521 1;
BA_ "DiagResponse" BO_ 2564485522 1;
BA_ "Type" BO_ 2564485522 8;
BA_ "DiagResponse" BO_ 2564485540 1;
BA_ "Type" BO_ 2564485540 8;
BA_ "DiagResponse" BO_ 2564485541 1;
BA_ "Type" BO_ 2564485541 8;
BA_ "DiagResponse" BO_ 2564485566 1;
BA_ "Type" BO_ 2564485566 8;
BA_ "DiagResponse" BO_ 2564485568 1;
BA_ "Type" BO_ 2564485568 8;
BA_ "DiagResponse" BO_ 2564485585 1;
BA_ "Type" BO_ 2564485585 8;
BA_ "DiagResponse" BO_ 2564485588 1;
BA_ "Type" BO_ 2564485588 8;
BA_ "DiagResponse" BO_ 2564485589 1;
BA_ "DiagResponse" BO_ 2564485590 1;
BA_ "Type" BO_ 2564485590 8;
BA_ "DiagResponse" BO_ 2564485591 1;
BA_ "Type" BO_ 2564485591 8;
BA_ "DiagResponse" BO_ 2564485600 1;
BA_ "DiagResponse" BO_ 2564485601 1;
BA_ "Type" BO_ 2564485601 8;
BA_ "DiagRequest" BO_ 2564554481 1;
BA_ "Type" BO_ 2564554481 8;
BA_ "DiagRequest" BO_ 2564554737 1;
BA_ "Type" BO_ 2564554737 8;
BA_ "GenMsgILSupport" BO_ 2651930624 1;
BA_ "GenMsgTimeoutTime" BO_ 2651930624 2500;
BA_ "Type" BO_ 2651930624 8;
BA_ "GenMsgILSupport" BO_ 2651930626 1;
BA_ "GenMsgTimeoutTime" BO_ 2651930626 1000;
BA_ "Type" BO_ 2651930626 8;
BA_ "GenMsgILSupport" BO_ 2651930630 1;
BA_ "GenMsgTimeoutTime" BO_ 2651930630 1000;
BA_ "Type" BO_ 2651930630 8;
BA_ "GenMsgILSupport" BO_ 2651930638 1;
BA_ "GenMsgTimeoutTime" BO_ 2651930638 1000;
BA_ "Type" BO_ 2651930638 8;
BA_ "GenMsgILSupport" BO_ 2651930650 1;
BA_ "GenMsgTimeoutTime" BO_ 2651930650 1000;
BA_ "Type" BO_ 2651930650 8;
BA_ "GenMsgILSupport" BO_ 2651930654 1;
BA_ "GenMsgTimeoutTime" BO_ 2651930654 1000;
BA_ "Type" BO_ 2651930654 8;
BA_ "GenMsgILSupport" BO_ 2651930661 1;
BA_ "GenMsgTimeoutTime" BO_ 2651930661 1000;
BA_ "Type" BO_ 2651930661 8;
BA_ "GenMsgILSupport" BO_ 2651930662 1;
BA_ "GenMsgTimeoutTime" BO_ 2651930662 1000;
BA_ "Type" BO_ 2651930662 8;
BA_ "GenMsgILSupport" BO_ 2651930663 1;
BA_ "GenMsgTimeoutTime" BO_ 2651930663 1000;
BA_ "Type" BO_ 2651930663 8;
BA_ "GenMsgILSupport" BO_ 2651930673 1;
BA_ "GenMsgTimeoutTime" BO_ 2651930673 1000;
BA_ "Type" BO_ 2651930673 8;
BA_ "GenMsgILSupport" BO_ 2651930675 1;
BA_ "GenMsgTimeoutTime" BO_ 2651930675 1000;
BA_ "Type" BO_ 2651930675 8;
BA_ "GenMsgILSupport" BO_ 2651930676 1;
BA_ "GenMsgTimeoutTime" BO_ 2651930676 1000;
BA_ "Type" BO_ 2651930676 8;
BA_ "GenMsgILSupport" BO_ 2651930681 1;
BA_ "GenMsgTimeoutTime" BO_ 2651930681 1000;
BA_ "Type" BO_ 2651930681 8;
BA_ "GenMsgILSupport" BO_ 2651930739 1;
BA_ "GenMsgTimeoutTime" BO_ 2651930739 1000;
BA_ "Type" BO_ 2651930739 8;
BA_ "GenMsgILSupport" BO_ 2651930747 1;
BA_ "GenMsgTimeoutTime" BO_ 2651930747 1000;
BA_ "Type" BO_ 2651930747 8;
BA_ "GenMsgCycleTime" BO_ 2654208000 200;
BA_ "GenMsgILSupport" BO_ 2654208000 1;
BA_ "GenMsgSendType" BO_ 2654208000 0;
BA_ "GenMsgStartDelayTime" BO_ 2654208000 10;
BA_ "GenMsgTimeoutTime" BO_ 2654208000 2500;
BA_ "NmMessage" BO_ 2654208000 1;
BA_ "Period" BO_ 2654208000 200;
BA_ "Type" BO_ 2654208000 3;
BA_ "GenMsgStartDelayTime" BO_ 2654208003 10;
BA_ "NmMessage" BO_ 2654208003 1;
BA_ "Type" BO_ 2654208003 8;
BA_ "GenMsgILSupport" BO_ 2654208005 1;
BA_ "GenMsgStartDelayTime" BO_ 2654208005 10;
BA_ "NmMessage" BO_ 2654208005 1;
BA_ "Type" BO_ 2654208005 8;
BA_ "GenMsgStartDelayTime" BO_ 2654208007 10;
BA_ "NmMessage" BO_ 2654208007 1;
BA_ "Type" BO_ 2654208007 8;
BA_ "GenMsgILSupport" BO_ 2654208026 1;
BA_ "GenMsgStartDelayTime" BO_ 2654208026 10;
BA_ "NmMessage" BO_ 2654208026 1;
BA_ "Type" BO_ 2654208026 8;
BA_ "GenMsgILSupport" BO_ 2654208028 1;
BA_ "GenMsgStartDelayTime" BO_ 2654208028 10;
BA_ "NmMessage" BO_ 2654208028 1;
BA_ "Type" BO_ 2654208028 8;
BA_ "GenMsgILSupport" BO_ 2654208037 1;
BA_ "GenMsgStartDelayTime" BO_ 2654208037 10;
BA_ "NmMessage" BO_ 2654208037 1;
BA_ "Type" BO_ 2654208037 8;
BA_ "GenMsgILSupport" BO_ 2654208041 1;
BA_ "GenMsgStartDelayTime" BO_ 2654208041 10;
BA_ "NmMessage" BO_ 2654208041 1;
BA_ "Type" BO_ 2654208041 8;
BA_ "GenMsgILSupport" BO_ 2654208084 1;
BA_ "GenMsgStartDelayTime" BO_ 2654208084 10;
BA_ "NmMessage" BO_ 2654208084 1;
BA_ "Type" BO_ 2654208084 8;
BA_ "GenMsgILSupport" BO_ 2654208089 1;
BA_ "GenMsgStartDelayTime" BO_ 2654208089 10;
BA_ "NmMessage" BO_ 2654208089 1;
BA_ "Type" BO_ 2654208089 8;
BA_ "GenMsgCycleTime" BO_ 2654339074 100;
BA_ "GenMsgILSupport" BO_ 2654339074 1;
BA_ "GenMsgSendType" BO_ 2654339074 0;
BA_ "GenMsgTimeoutTime" BO_ 2654339074 2500;
BA_ "Period" BO_ 2654339074 100;
BA_ "Type" BO_ 2654339074 3;
BA_ "GenMsgCycleTime" BO_ 2654339075 100;
BA_ "GenMsgILSupport" BO_ 2654339075 1;
BA_ "GenMsgSendType" BO_ 2654339075 0;
BA_ "GenMsgTimeoutTime" BO_ 2654339075 2500;
BA_ "Period" BO_ 2654339075 100;
BA_ "Type" BO_ 2654339075 1;
BA_ "GenMsgCycleTime" BO_ 2654339077 100;
BA_ "GenMsgILSupport" BO_ 2654339077 1;
BA_ "GenMsgSendType" BO_ 2654339077 0;
BA_ "GenMsgTimeoutTime" BO_ 2654339077 2500;
BA_ "Period" BO_ 2654339077 100;
BA_ "Type" BO_ 2654339077 1;
BA_ "GenMsgCycleTime" BO_ 2654339079 100;
BA_ "GenMsgILSupport" BO_ 2654339079 1;
BA_ "GenMsgSendType" BO_ 2654339079 0;
BA_ "GenMsgTimeoutTime" BO_ 2654339079 2500;
BA_ "Period" BO_ 2654339079 100;
BA_ "Type" BO_ 2654339079 1;
BA_ "GenMsgCycleTime" BO_ 2654339092 1000;
BA_ "GenMsgDelayTime" BO_ 2654339092 10;
BA_ "GenMsgILSupport" BO_ 2654339092 1;
BA_ "GenMsgSendType" BO_ 2654339092 0;
BA_ "GenMsgTimeoutTime" BO_ 2654339092 2500;
BA_ "Period" BO_ 2654339092 1000;
BA_ "Type" BO_ 2654339092 1;
BA_ "GenMsgCycleTime" BO_ 2654339098 1000;
BA_ "GenMsgILSupport" BO_ 2654339098 1;
BA_ "GenMsgSendType" BO_ 2654339098 0;
BA_ "GenMsgTimeoutTime" BO_ 2654339098 2500;
BA_ "Period" BO_ 2654339098 1000;
BA_ "Type" BO_ 2654339098 1;
BA_ "GenMsgCycleTime" BO_ 2654339100 1000;
BA_ "GenMsgDelayTime" BO_ 2654339100 10;
BA_ "GenMsgILSupport" BO_ 2654339100 1;
BA_ "GenMsgSendType" BO_ 2654339100 0;
BA_ "GenMsgTimeoutTime" BO_ 2654339100 2500;
BA_ "Period" BO_ 2654339100 1000;
BA_ "Type" BO_ 2654339100 1;
BA_ "GenMsgCycleTime" BO_ 2654339102 1000;
BA_ "GenMsgDelayTime" BO_ 2654339102 10;
BA_ "GenMsgILSupport" BO_ 2654339102 1;
BA_ "GenMsgSendType" BO_ 2654339102 0;
BA_ "GenMsgTimeoutTime" BO_ 2654339102 2500;
BA_ "Period" BO_ 2654339102 1000;
BA_ "Type" BO_ 2654339102 1;
BA_ "GenMsgCycleTime" BO_ 2654339109 100;
BA_ "GenMsgILSupport" BO_ 2654339109 1;
BA_ "GenMsgSendType" BO_ 2654339109 0;
BA_ "GenMsgTimeoutTime" BO_ 2654339109 2500;
BA_ "Period" BO_ 2654339109 100;
BA_ "Type" BO_ 2654339109 1;
BA_ "GenMsgCycleTime" BO_ 2654339110 1000;
BA_ "GenMsgILSupport" BO_ 2654339110 1;
BA_ "GenMsgSendType" BO_ 2654339110 0;
BA_ "GenMsgTimeoutTime" BO_ 2654339110 2500;
BA_ "Period" BO_ 2654339110 1000;
BA_ "Type" BO_ 2654339110 1;
BA_ "GenMsgCycleTime" BO_ 2654339111 1000;
BA_ "GenMsgILSupport" BO_ 2654339111 1;
BA_ "GenMsgSendType" BO_ 2654339111 0;
BA_ "GenMsgTimeoutTime" BO_ 2654339111 2500;
BA_ "Period" BO_ 2654339111 1000;
BA_ "Type" BO_ 2654339111 1;
BA_ "GenMsgCycleTime" BO_ 2654339113 100;
BA_ "GenMsgILSupport" BO_ 2654339113 1;
BA_ "GenMsgSendType" BO_ 2654339113 0;
BA_ "GenMsgTimeoutTime" BO_ 2654339113 2500;
BA_ "Period" BO_ 2654339113 100;
BA_ "Type" BO_ 2654339113 1;
BA_ "GenMsgCycleTime" BO_ 2654339121 1000;
BA_ "GenMsgDelayTime" BO_ 2654339121 10;
BA_ "GenMsgILSupport" BO_ 2654339121 1;
BA_ "GenMsgSendType" BO_ 2654339121 0;
BA_ "GenMsgTimeoutTime" BO_ 2654339121 2500;
BA_ "Period" BO_ 2654339121 1000;
BA_ "Type" BO_ 2654339121 1;
BA_ "GenMsgCycleTime" BO_ 2654339123 1000;
BA_ "GenMsgDelayTime" BO_ 2654339123 10;
BA_ "GenMsgILSupport" BO_ 2654339123 1;
BA_ "GenMsgSendType" BO_ 2654339123 0;
BA_ "GenMsgTimeoutTime" BO_ 2654339123 2500;
BA_ "Period" BO_ 2654339123 1000;
BA_ "Type" BO_ 2654339123 1;
BA_ "GenMsgCycleTime" BO_ 2654339124 1000;
BA_ "GenMsgDelayTime" BO_ 2654339124 10;
BA_ "GenMsgILSupport" BO_ 2654339124 1;
BA_ "GenMsgSendType" BO_ 2654339124 0;
BA_ "GenMsgTimeoutTime" BO_ 2654339124 2500;
BA_ "Period" BO_ 2654339124 1000;
BA_ "Type" BO_ 2654339124 1;
BA_ "GenMsgCycleTime" BO_ 2654339129 1000;
BA_ "GenMsgDelayTime" BO_ 2654339129 10;
BA_ "GenMsgILSupport" BO_ 2654339129 1;
BA_ "GenMsgSendType" BO_ 2654339129 0;
BA_ "GenMsgTimeoutTime" BO_ 2654339129 2500;
BA_ "Period" BO_ 2654339129 1000;
BA_ "Type" BO_ 2654339129 1;
BA_ "GenMsgCycleTime" BO_ 2654339144 100;
BA_ "GenMsgILSupport" BO_ 2654339144 1;
BA_ "GenMsgSendType" BO_ 2654339144 0;
BA_ "GenMsgTimeoutTime" BO_ 2654339144 2500;
BA_ "Period" BO_ 2654339144 100;
BA_ "Type" BO_ 2654339144 1;
BA_ "GenMsgCycleTime" BO_ 2654339145 100;
BA_ "GenMsgILSupport" BO_ 2654339145 1;
BA_ "GenMsgSendType" BO_ 2654339145 0;
BA_ "GenMsgTimeoutTime" BO_ 2654339145 2500;
BA_ "Period" BO_ 2654339145 100;
BA_ "Type" BO_ 2654339145 1;
BA_ "GenMsgCycleTime" BO_ 2654339146 100;
BA_ "GenMsgILSupport" BO_ 2654339146 1;
BA_ "GenMsgSendType" BO_ 2654339146 0;
BA_ "GenMsgTimeoutTime" BO_ 2654339146 2500;
BA_ "Period" BO_ 2654339146 100;
BA_ "Type" BO_ 2654339146 1;
BA_ "GenMsgCycleTime" BO_ 2654339147 100;
BA_ "GenMsgILSupport" BO_ 2654339147 1;
BA_ "GenMsgSendType" BO_ 2654339147 0;
BA_ "GenMsgTimeoutTime" BO_ 2654339147 2500;
BA_ "Period" BO_ 2654339147 100;
BA_ "Type" BO_ 2654339147 1;
BA_ "GenMsgCycleTime" BO_ 2654339156 100;
BA_ "GenMsgILSupport" BO_ 2654339156 1;
BA_ "GenMsgSendType" BO_ 2654339156 0;
BA_ "GenMsgTimeoutTime" BO_ 2654339156 2500;
BA_ "Period" BO_ 2654339156 100;
BA_ "Type" BO_ 2654339156 1;
BA_ "GenMsgCycleTime" BO_ 2654339161 100;
BA_ "GenMsgILSupport" BO_ 2654339161 1;
BA_ "GenMsgSendType" BO_ 2654339161 0;
BA_ "Period" BO_ 2654339161 100;
BA_ "Type" BO_ 2654339161 1;
BA_ "GenMsgCycleTime" BO_ 2654339182 1000;
BA_ "GenMsgILSupport" BO_ 2654339182 1;
BA_ "GenMsgSendType" BO_ 2654339182 0;
BA_ "GenMsgTimeoutTime" BO_ 2654339182 2500;
BA_ "Period" BO_ 2654339182 1000;
BA_ "Type" BO_ 2654339182 1;
BA_ "GenMsgCycleTime" BO_ 2654339183 1000;
BA_ "GenMsgILSupport" BO_ 2654339183 1;
BA_ "GenMsgSendType" BO_ 2654339183 0;
BA_ "GenMsgTimeoutTime" BO_ 2654339183 2500;
BA_ "Period" BO_ 2654339183 1000;
BA_ "Type" BO_ 2654339183 1;
BA_ "GenMsgCycleTime" BO_ 2654339195 1000;
BA_ "GenMsgDelayTime" BO_ 2654339195 10;
BA_ "GenMsgILSupport" BO_ 2654339195 1;
BA_ "GenMsgSendType" BO_ 2654339195 0;
BA_ "GenMsgTimeoutTime" BO_ 2654339195 2500;
BA_ "Period" BO_ 2654339195 1000;
BA_ "Type" BO_ 2654339195 1;
BA_ "GenMsgCycleTime" BO_ 2654339197 1000;
BA_ "GenMsgILSupport" BO_ 2654339197 1;
BA_ "GenMsgSendType" BO_ 2654339197 0;
BA_ "GenMsgTimeoutTime" BO_ 2654339197 2500;
BA_ "Period" BO_ 2654339197 1000;
BA_ "Type" BO_ 2654339197 1;
BA_ "GenMsgILSupport" BO_ 2658971643 1;
BA_ "Type" BO_ 2658971643 5;
BA_ "EventTrans" SG_ 1504 FuelFlapSts 0;
BA_ "GenSigSendType" SG_ 1504 FuelFlapSts 3;
BA_ "Accuracy" SG_ 1504 TotalOdometer "N/A";
BA_ "SignalAge" SG_ 1504 TotalOdometer 1000;
BA_ "GenSigStartValue" SG_ 1504 NightDaySts 1;
BA_ "InitialValue" SG_ 1504 NightDaySts 1;
BA_ "GenSigStartValue" SG_ 1504 AVHDriverDoorSts 1;
BA_ "InitialValue" SG_ 1504 AVHDriverDoorSts 1;
BA_ "GenSigStartValue" SG_ 1504 Alcohol_Interlock_Inhibit 1;
BA_ "InitialValue" SG_ 1504 Alcohol_Interlock_Inhibit 1;
BA_ "EventTrans" SG_ 1530 Left_LB_Feedback 0;
BA_ "GenSigSendType" SG_ 1530 Left_LB_Feedback 3;
BA_ "EventTrans" SG_ 1530 LCUFailSts 0;
BA_ "GenSigSendType" SG_ 1530 LCUFailSts 3;
BA_ "EventTrans" SG_ 1530 Right_PL_FailSts 0;
BA_ "GenSigSendType" SG_ 1530 Right_PL_FailSts 3;
BA_ "EventTrans" SG_ 1530 Left_PL_FailSts 0;
BA_ "GenSigSendType" SG_ 1530 Left_PL_FailSts 3;
BA_ "EventTrans" SG_ 1530 Right_DRL_Feedback 0;
BA_ "GenSigSendType" SG_ 1530 Right_DRL_Feedback 3;
BA_ "EventTrans" SG_ 1530 Left_DRL_Feedback 0;
BA_ "GenSigSendType" SG_ 1530 Left_DRL_Feedback 3;
BA_ "EventTrans" SG_ 1530 Right_PL_Feedback 0;
BA_ "GenSigSendType" SG_ 1530 Right_PL_Feedback 3;
BA_ "EventTrans" SG_ 1530 Left_PL_Feedback 0;
BA_ "GenSigSendType" SG_ 1530 Left_PL_Feedback 3;
BA_ "EventTrans" SG_ 1530 Left_HB_Feedback 0;
BA_ "GenSigSendType" SG_ 1530 Left_HB_Feedback 3;
BA_ "EventTrans" SG_ 1530 LVL_FailSts 0;
BA_ "GenSigSendType" SG_ 1530 LVL_FailSts 3;
BA_ "EventTrans" SG_ 1530 FBLFailSts 0;
BA_ "GenSigSendType" SG_ 1530 FBLFailSts 3;
BA_ "EventTrans" SG_ 1530 Comp_HBFailSts 0;
BA_ "GenSigSendType" SG_ 1530 Comp_HBFailSts 3;
BA_ "EventTrans" SG_ 1530 ADB_FailSts 0;
BA_ "GenSigSendType" SG_ 1530 ADB_FailSts 3;
BA_ "EventTrans" SG_ 1530 Right_LB_FailSts 0;
BA_ "GenSigSendType" SG_ 1530 Right_LB_FailSts 3;
BA_ "EventTrans" SG_ 1530 Left_LB_FailSts 0;
BA_ "GenSigSendType" SG_ 1530 Left_LB_FailSts 3;
BA_ "EventTrans" SG_ 1530 Right_LB_Feedback 0;
BA_ "GenSigSendType" SG_ 1530 Right_LB_Feedback 3;
BA_ "EventTrans" SG_ 1530 Left_DRL_FailSts 0;
BA_ "GenSigSendType" SG_ 1530 Left_DRL_FailSts 3;
BA_ "EventTrans" SG_ 1530 Right_TI_FailSts 0;
BA_ "GenSigSendType" SG_ 1530 Right_TI_FailSts 3;
BA_ "EventTrans" SG_ 1530 Left_TI_FailSts 0;
BA_ "GenSigSendType" SG_ 1530 Left_TI_FailSts 3;
BA_ "EventTrans" SG_ 1530 Right_TI_Feedback 0;
BA_ "GenSigSendType" SG_ 1530 Right_TI_Feedback 3;
BA_ "EventTrans" SG_ 1530 Left_TI_Feedback 0;
BA_ "GenSigSendType" SG_ 1530 Left_TI_Feedback 3;
BA_ "EventTrans" SG_ 1530 Right_HB_FailSts 0;
BA_ "GenSigSendType" SG_ 1530 Right_HB_FailSts 3;
BA_ "EventTrans" SG_ 1530 Left_HB_FailSts 0;
BA_ "GenSigSendType" SG_ 1530 Left_HB_FailSts 3;
BA_ "EventTrans" SG_ 1530 Right_HB_Feedback 0;
BA_ "GenSigSendType" SG_ 1530 Right_HB_Feedback 3;
BA_ "EventTrans" SG_ 1530 TrafficChangeFbk 0;
BA_ "GenSigSendType" SG_ 1530 TrafficChangeFbk 3;
BA_ "EventTrans" SG_ 1530 ParkingLight_Feedback 0;
BA_ "GenSigSendType" SG_ 1530 ParkingLight_Feedback 3;
BA_ "EventTrans" SG_ 1530 Right_DRL_FailSts 0;
BA_ "GenSigSendType" SG_ 1530 Right_DRL_FailSts 3;
BA_ "Accuracy" SG_ 1539 TotalOdometer "N/A";
BA_ "SignalAge" SG_ 1539 TotalOdometer 1000;
BA_ "EventTrans" SG_ 1696 Hour2 0;
BA_ "GenSigSendType" SG_ 1696 Hour2 3;
BA_ "EventTrans" SG_ 1696 Hour1 0;
BA_ "GenSigSendType" SG_ 1696 Hour1 3;
BA_ "EventTrans" SG_ 1696 Minute2 0;
BA_ "GenSigSendType" SG_ 1696 Minute2 3;
BA_ "EventTrans" SG_ 1696 Minute1 0;
BA_ "GenSigSendType" SG_ 1696 Minute1 3;
BA_ "EventTrans" SG_ 1696 Day2 0;
BA_ "GenSigSendType" SG_ 1696 Day2 3;
BA_ "EventTrans" SG_ 1696 Day1 0;
BA_ "GenSigSendType" SG_ 1696 Day1 3;
BA_ "EventTrans" SG_ 1696 Month2 0;
BA_ "GenSigSendType" SG_ 1696 Month2 3;
BA_ "EventTrans" SG_ 1696 Month1 0;
BA_ "GenSigSendType" SG_ 1696 Month1 3;
BA_ "EventTrans" SG_ 1696 Year2 0;
BA_ "GenSigSendType" SG_ 1696 Year2 3;
BA_ "EventTrans" SG_ 1696 Year1 0;
BA_ "GenSigSendType" SG_ 1696 Year1 3;
BA_ "EventTrans" SG_ 1696 Year4 0;
BA_ "GenSigSendType" SG_ 1696 Year4 3;
BA_ "EventTrans" SG_ 1696 Year3 0;
BA_ "GenSigSendType" SG_ 1696 Year3 3;
BA_ "Accuracy" SG_ 1728 RearWheelCircumference "N/A";
BA_ "InitialValue" SG_ 1728 RearWheelCircumference 1440;
BA_ "InitialValue" SG_ 1728 NotInUseMonitoringTimer 10;
BA_ "EventTrans" SG_ 1752 WCM_Status 0;
BA_ "GenSigSendType" SG_ 1752 WCM_Status 3;
BA_ "EventTrans" SG_ 1852 ACC_Dist_fbk 0;
BA_ "GenSigSendType" SG_ 1852 ACC_Dist_fbk 3;
BA_ "GenSigStartValue" SG_ 1852 ACC_Dist_fbk 5;
BA_ "InitialValue" SG_ 1852 ACC_Dist_fbk 5;
BA_ "EventTrans" SG_ 1852 HMICode_FCW 0;
BA_ "GenSigSendType" SG_ 1852 HMICode_FCW 3;
BA_ "EventTrans" SG_ 1852 HMICode_ACC 0;
BA_ "GenSigSendType" SG_ 1852 HMICode_ACC 3;
BA_ "EventTrans" SG_ 1852 HMIDisplay_ACC 0;
BA_ "GenSigSendType" SG_ 1852 HMIDisplay_ACC 3;
BA_ "GenSigStartValue" SG_ 1852 FCWSensibilitySts 3;
BA_ "InitialValue" SG_ 1852 FCWSensibilitySts 3;
BA_ "GenSigStartValue" SG_ 1853 ACC_TargetDistance 511;
BA_ "InitialValue" SG_ 1853 ACC_TargetDistance 511;
BA_ "GenSigStartValue" SG_ 1853 ACC_DesiredDistance 127;
BA_ "InitialValue" SG_ 1853 ACC_DesiredDistance 127;
BA_ "GenSigStartValue" SG_ 1853 ACC_TargetRelativeVelocity 512;
BA_ "EventTrans" SG_ 1853 ACC_SetSpeedKPH 0;
BA_ "GenSigSendType" SG_ 1853 ACC_SetSpeedKPH 3;
BA_ "EventTrans" SG_ 1853 ACC_SetSpeedMPH 0;
BA_ "GenSigSendType" SG_ 1853 ACC_SetSpeedMPH 3;
BA_ "EventTrans" SG_ 1859 Digit_10 0;
BA_ "GenSigSendType" SG_ 1859 Digit_10 1;
BA_ "EventTrans" SG_ 1859 Digit_11 0;
BA_ "GenSigSendType" SG_ 1859 Digit_11 1;
BA_ "EventTrans" SG_ 1859 Digit_08 0;
BA_ "GenSigSendType" SG_ 1859 Digit_08 1;
BA_ "EventTrans" SG_ 1859 Digit_09 0;
BA_ "GenSigSendType" SG_ 1859 Digit_09 1;
BA_ "EventTrans" SG_ 1859 Digit_06 0;
BA_ "GenSigSendType" SG_ 1859 Digit_06 1;
BA_ "EventTrans" SG_ 1859 Digit_07 0;
BA_ "GenSigSendType" SG_ 1859 Digit_07 1;
BA_ "EventTrans" SG_ 1859 Digit_04 0;
BA_ "GenSigSendType" SG_ 1859 Digit_04 1;
BA_ "EventTrans" SG_ 1859 Digit_05 0;
BA_ "GenSigSendType" SG_ 1859 Digit_05 1;
BA_ "EventTrans" SG_ 1859 Digit_02 0;
BA_ "GenSigSendType" SG_ 1859 Digit_02 1;
BA_ "EventTrans" SG_ 1859 Digit_03 0;
BA_ "GenSigSendType" SG_ 1859 Digit_03 1;
BA_ "EventTrans" SG_ 1859 Digit_01 0;
BA_ "GenSigSendType" SG_ 1859 Digit_01 1;
BA_ "EventTrans" SG_ 1863 Digit_10 0;
BA_ "GenSigSendType" SG_ 1863 Digit_10 1;
BA_ "EventTrans" SG_ 1863 Digit_11 0;
BA_ "GenSigSendType" SG_ 1863 Digit_11 1;
BA_ "EventTrans" SG_ 1863 Digit_08 0;
BA_ "GenSigSendType" SG_ 1863 Digit_08 1;
BA_ "EventTrans" SG_ 1863 Digit_09 0;
BA_ "GenSigSendType" SG_ 1863 Digit_09 1;
BA_ "EventTrans" SG_ 1863 Digit_06 0;
BA_ "GenSigSendType" SG_ 1863 Digit_06 1;
BA_ "EventTrans" SG_ 1863 Digit_07 0;
BA_ "GenSigSendType" SG_ 1863 Digit_07 1;
BA_ "EventTrans" SG_ 1863 Digit_04 0;
BA_ "GenSigSendType" SG_ 1863 Digit_04 1;
BA_ "EventTrans" SG_ 1863 Digit_05 0;
BA_ "GenSigSendType" SG_ 1863 Digit_05 1;
BA_ "EventTrans" SG_ 1863 Digit_02 0;
BA_ "GenSigSendType" SG_ 1863 Digit_02 1;
BA_ "EventTrans" SG_ 1863 Digit_03 0;
BA_ "GenSigSendType" SG_ 1863 Digit_03 1;
BA_ "EventTrans" SG_ 1863 Digit_01 0;
BA_ "GenSigSendType" SG_ 1863 Digit_01 1;
BA_ "EventTrans" SG_ 1955 WCM_Status 0;
BA_ "GenSigSendType" SG_ 1955 WCM_Status 3;
BA_ "EventTrans" SG_ 1955 ElectricSteeringLamp_FailSts 0;
BA_ "GenSigSendType" SG_ 1955 ElectricSteeringLamp_FailSts 3;
BA_ "EventTrans" SG_ 1955 VDCLamp_FailSts 0;
BA_ "GenSigSendType" SG_ 1955 VDCLamp_FailSts 3;
BA_ "EventTrans" SG_ 1955 EBDLamp_FailSts 0;
BA_ "GenSigSendType" SG_ 1955 EBDLamp_FailSts 3;
BA_ "EventTrans" SG_ 1955 ABSLamp_FailSts 0;
BA_ "GenSigSendType" SG_ 1955 ABSLamp_FailSts 3;
BA_ "EventTrans" SG_ 1955 InternalLightLevel 0;
BA_ "GenSigSendType" SG_ 1955 InternalLightLevel 3;
BA_ "GenSigSendType" SG_ 2564440305 UDS_SGW_BCM_PhysReq_Data 1;
BA_ "GenSigSendType" SG_ 2564460785 UDS_SGW_NPE_PhyReq_Data 1;
BA_ "GenSigSendType" SG_ 2564473073 UDS_SGW_NAB_PhysReq_Data 1;
BA_ "GenSigSendType" SG_ 2564485440 UDS_BCM_SGW_PhyRes_Data 1;
BA_ "GenSigSendType" SG_ 2564485520 UDS_NPE_SGW_PhyRes_Data 1;
BA_ "GenSigSendType" SG_ 2564485568 UDS_NAB_SGW_PhyRes_Data 1;
BA_ "GenSigSendType" SG_ 2564554481 UDS_OBD_to_ALL_FunctionalRequest 1;
BA_ "EventTrans" SG_ 2564554737 TPDU_EDRDATAREQ 0;
BA_ "GenSigSendType" SG_ 2564554737 TPDU_EDRDATAREQ 1;
BA_ "EventTrans" SG_ 2651930624 Digit_10 0;
BA_ "GenSigSendType" SG_ 2651930624 Digit_10 1;
BA_ "EventTrans" SG_ 2651930624 Digit_11 0;
BA_ "GenSigSendType" SG_ 2651930624 Digit_11 1;
BA_ "EventTrans" SG_ 2651930624 Digit_08 0;
BA_ "GenSigSendType" SG_ 2651930624 Digit_08 1;
BA_ "EventTrans" SG_ 2651930624 Digit_09 0;
BA_ "GenSigSendType" SG_ 2651930624 Digit_09 1;
BA_ "EventTrans" SG_ 2651930624 Digit_06 0;
BA_ "GenSigSendType" SG_ 2651930624 Digit_06 1;
BA_ "EventTrans" SG_ 2651930624 Digit_07 0;
BA_ "GenSigSendType" SG_ 2651930624 Digit_07 1;
BA_ "EventTrans" SG_ 2651930624 Digit_04 0;
BA_ "GenSigSendType" SG_ 2651930624 Digit_04 1;
BA_ "EventTrans" SG_ 2651930624 Digit_05 0;
BA_ "GenSigSendType" SG_ 2651930624 Digit_05 1;
BA_ "EventTrans" SG_ 2651930624 Digit_02 0;
BA_ "GenSigSendType" SG_ 2651930624 Digit_02 1;
BA_ "EventTrans" SG_ 2651930624 Digit_03 0;
BA_ "GenSigSendType" SG_ 2651930624 Digit_03 1;
BA_ "EventTrans" SG_ 2651930624 Digit_01 0;
BA_ "GenSigSendType" SG_ 2651930624 Digit_01 1;
BA_ "EventTrans" SG_ 2651930626 Digit_10_NGE 0;
BA_ "GenSigSendType" SG_ 2651930626 Digit_10_NGE 1;
BA_ "EventTrans" SG_ 2651930626 Digit_11_NGE 0;
BA_ "GenSigSendType" SG_ 2651930626 Digit_11_NGE 1;
BA_ "EventTrans" SG_ 2651930626 Digit_08_NGE 0;
BA_ "GenSigSendType" SG_ 2651930626 Digit_08_NGE 1;
BA_ "EventTrans" SG_ 2651930626 Digit_09_NGE 0;
BA_ "GenSigSendType" SG_ 2651930626 Digit_09_NGE 1;
BA_ "EventTrans" SG_ 2651930626 Digit_06_NGE 0;
BA_ "GenSigSendType" SG_ 2651930626 Digit_06_NGE 1;
BA_ "EventTrans" SG_ 2651930626 Digit_07_NGE 0;
BA_ "GenSigSendType" SG_ 2651930626 Digit_07_NGE 1;
BA_ "EventTrans" SG_ 2651930626 Digit_04_NGE 0;
BA_ "GenSigSendType" SG_ 2651930626 Digit_04_NGE 1;
BA_ "EventTrans" SG_ 2651930626 Digit_05_NGE 0;
BA_ "GenSigSendType" SG_ 2651930626 Digit_05_NGE 1;
BA_ "EventTrans" SG_ 2651930626 Digit_02_NGE 0;
BA_ "GenSigSendType" SG_ 2651930626 Digit_02_NGE 1;
BA_ "EventTrans" SG_ 2651930626 Digit_03_NGE 0;
BA_ "GenSigSendType" SG_ 2651930626 Digit_03_NGE 1;
BA_ "EventTrans" SG_ 2651930626 Digit_01_NGE 0;
BA_ "GenSigSendType" SG_ 2651930626 Digit_01_NGE 1;
BA_ "EventTrans" SG_ 2651930630 Digit_10_NFR 0;
BA_ "GenSigSendType" SG_ 2651930630 Digit_10_NFR 1;
BA_ "EventTrans" SG_ 2651930630 Digit_11_NFR 0;
BA_ "GenSigSendType" SG_ 2651930630 Digit_11_NFR 1;
BA_ "EventTrans" SG_ 2651930630 Digit_08_NFR 0;
BA_ "GenSigSendType" SG_ 2651930630 Digit_08_NFR 1;
BA_ "EventTrans" SG_ 2651930630 Digit_09_NFR 0;
BA_ "GenSigSendType" SG_ 2651930630 Digit_09_NFR 1;
BA_ "EventTrans" SG_ 2651930630 Digit_06_NFR 0;
BA_ "GenSigSendType" SG_ 2651930630 Digit_06_NFR 1;
BA_ "EventTrans" SG_ 2651930630 Digit_07_NFR 0;
BA_ "GenSigSendType" SG_ 2651930630 Digit_07_NFR 1;
BA_ "EventTrans" SG_ 2651930630 Digit_04_NFR 0;
BA_ "GenSigSendType" SG_ 2651930630 Digit_04_NFR 1;
BA_ "EventTrans" SG_ 2651930630 Digit_05_NFR 0;
BA_ "GenSigSendType" SG_ 2651930630 Digit_05_NFR 1;
BA_ "EventTrans" SG_ 2651930630 Digit_02_NFR 0;
BA_ "GenSigSendType" SG_ 2651930630 Digit_02_NFR 1;
BA_ "EventTrans" SG_ 2651930630 Digit_03_NFR 0;
BA_ "GenSigSendType" SG_ 2651930630 Digit_03_NFR 1;
BA_ "EventTrans" SG_ 2651930630 Digit_01_NFR 0;
BA_ "GenSigSendType" SG_ 2651930630 Digit_01_NFR 1;
BA_ "EventTrans" SG_ 2651930638 Digit_10_HVB 0;
BA_ "GenSigSendType" SG_ 2651930638 Digit_10_HVB 1;
BA_ "EventTrans" SG_ 2651930638 Digit_11_HVB 0;
BA_ "GenSigSendType" SG_ 2651930638 Digit_11_HVB 1;
BA_ "EventTrans" SG_ 2651930638 Digit_08_HVB 0;
BA_ "GenSigSendType" SG_ 2651930638 Digit_08_HVB 1;
BA_ "EventTrans" SG_ 2651930638 Digit_09_HVB 0;
BA_ "GenSigSendType" SG_ 2651930638 Digit_09_HVB 1;
BA_ "EventTrans" SG_ 2651930638 Digit_06_HVB 0;
BA_ "GenSigSendType" SG_ 2651930638 Digit_06_HVB 1;
BA_ "EventTrans" SG_ 2651930638 Digit_07_HVB 0;
BA_ "GenSigSendType" SG_ 2651930638 Digit_07_HVB 1;
BA_ "EventTrans" SG_ 2651930638 Digit_04_HVB 0;
BA_ "GenSigSendType" SG_ 2651930638 Digit_04_HVB 1;
BA_ "EventTrans" SG_ 2651930638 Digit_05_HVB 0;
BA_ "GenSigSendType" SG_ 2651930638 Digit_05_HVB 1;
BA_ "EventTrans" SG_ 2651930638 Digit_02_HVB 0;
BA_ "GenSigSendType" SG_ 2651930638 Digit_02_HVB 1;
BA_ "EventTrans" SG_ 2651930638 Digit_03_HVB 0;
BA_ "GenSigSendType" SG_ 2651930638 Digit_03_HVB 1;
BA_ "EventTrans" SG_ 2651930638 Digit_01_HVB 0;
BA_ "GenSigSendType" SG_ 2651930638 Digit_01_HVB 1;
BA_ "EventTrans" SG_ 2651930650 Digit_10_NAB 0;
BA_ "GenSigSendType" SG_ 2651930650 Digit_10_NAB 1;
BA_ "EventTrans" SG_ 2651930650 Digit_11_NAB 0;
BA_ "GenSigSendType" SG_ 2651930650 Digit_11_NAB 1;
BA_ "EventTrans" SG_ 2651930650 Digit_08_NAB 0;
BA_ "GenSigSendType" SG_ 2651930650 Digit_08_NAB 1;
BA_ "EventTrans" SG_ 2651930650 Digit_09_NAB 0;
BA_ "GenSigSendType" SG_ 2651930650 Digit_09_NAB 1;
BA_ "EventTrans" SG_ 2651930650 Digit_06_NAB 0;
BA_ "GenSigSendType" SG_ 2651930650 Digit_06_NAB 1;
BA_ "EventTrans" SG_ 2651930650 Digit_07_NAB 0;
BA_ "GenSigSendType" SG_ 2651930650 Digit_07_NAB 1;
BA_ "EventTrans" SG_ 2651930650 Digit_04_NAB 0;
BA_ "GenSigSendType" SG_ 2651930650 Digit_04_NAB 1;
BA_ "EventTrans" SG_ 2651930650 Digit_05_NAB 0;
BA_ "GenSigSendType" SG_ 2651930650 Digit_05_NAB 1;
BA_ "EventTrans" SG_ 2651930650 Digit_02_NAB 0;
BA_ "GenSigSendType" SG_ 2651930650 Digit_02_NAB 1;
BA_ "EventTrans" SG_ 2651930650 Digit_03_NAB 0;
BA_ "GenSigSendType" SG_ 2651930650 Digit_03_NAB 1;
BA_ "EventTrans" SG_ 2651930650 Digit_01_NAB 0;
BA_ "GenSigSendType" SG_ 2651930650 Digit_01_NAB 1;
BA_ "EventTrans" SG_ 2651930654 Digit_10_HALF 0;
BA_ "GenSigSendType" SG_ 2651930654 Digit_10_HALF 1;
BA_ "EventTrans" SG_ 2651930654 Digit_11_HALF 0;
BA_ "GenSigSendType" SG_ 2651930654 Digit_11_HALF 1;
BA_ "EventTrans" SG_ 2651930654 Digit_08_HALF 0;
BA_ "GenSigSendType" SG_ 2651930654 Digit_08_HALF 1;
BA_ "EventTrans" SG_ 2651930654 Digit_09_HALF 0;
BA_ "GenSigSendType" SG_ 2651930654 Digit_09_HALF 1;
BA_ "EventTrans" SG_ 2651930654 Digit_06_HALF 0;
BA_ "GenSigSendType" SG_ 2651930654 Digit_06_HALF 1;
BA_ "EventTrans" SG_ 2651930654 Digit_07_HALF 0;
BA_ "GenSigSendType" SG_ 2651930654 Digit_07_HALF 1;
BA_ "EventTrans" SG_ 2651930654 Digit_04_HALF 0;
BA_ "GenSigSendType" SG_ 2651930654 Digit_04_HALF 1;
BA_ "EventTrans" SG_ 2651930654 Digit_05_HALF 0;
BA_ "GenSigSendType" SG_ 2651930654 Digit_05_HALF 1;
BA_ "EventTrans" SG_ 2651930654 Digit_02_HALF 0;
BA_ "GenSigSendType" SG_ 2651930654 Digit_02_HALF 1;
BA_ "EventTrans" SG_ 2651930654 Digit_03_HALF 0;
BA_ "GenSigSendType" SG_ 2651930654 Digit_03_HALF 1;
BA_ "EventTrans" SG_ 2651930654 Digit_01_HALF 0;
BA_ "GenSigSendType" SG_ 2651930654 Digit_01_HALF 1;
BA_ "EventTrans" SG_ 2651930673 Digit_10_OBC 0;
BA_ "GenSigSendType" SG_ 2651930673 Digit_10_OBC 1;
BA_ "EventTrans" SG_ 2651930673 Digit_11_OBC 0;
BA_ "GenSigSendType" SG_ 2651930673 Digit_11_OBC 1;
BA_ "EventTrans" SG_ 2651930673 Digit_08_OBC 0;
BA_ "GenSigSendType" SG_ 2651930673 Digit_08_OBC 1;
BA_ "EventTrans" SG_ 2651930673 Digit_09_OBC 0;
BA_ "GenSigSendType" SG_ 2651930673 Digit_09_OBC 1;
BA_ "EventTrans" SG_ 2651930673 Digit_06_OBC 0;
BA_ "GenSigSendType" SG_ 2651930673 Digit_06_OBC 1;
BA_ "EventTrans" SG_ 2651930673 Digit_07_OBC 0;
BA_ "GenSigSendType" SG_ 2651930673 Digit_07_OBC 1;
BA_ "EventTrans" SG_ 2651930673 Digit_04_OBC 0;
BA_ "GenSigSendType" SG_ 2651930673 Digit_04_OBC 1;
BA_ "EventTrans" SG_ 2651930673 Digit_05_OBC 0;
BA_ "GenSigSendType" SG_ 2651930673 Digit_05_OBC 1;
BA_ "EventTrans" SG_ 2651930673 Digit_02_OBC 0;
BA_ "GenSigSendType" SG_ 2651930673 Digit_02_OBC 1;
BA_ "EventTrans" SG_ 2651930673 Digit_03_OBC 0;
BA_ "GenSigSendType" SG_ 2651930673 Digit_03_OBC 1;
BA_ "EventTrans" SG_ 2651930673 Digit_01_OBC 0;
BA_ "GenSigSendType" SG_ 2651930673 Digit_01_OBC 1;
BA_ "EventTrans" SG_ 2651930675 Digit_10_P4L 0;
BA_ "GenSigSendType" SG_ 2651930675 Digit_10_P4L 1;
BA_ "EventTrans" SG_ 2651930675 Digit_11_P4L 0;
BA_ "GenSigSendType" SG_ 2651930675 Digit_11_P4L 1;
BA_ "EventTrans" SG_ 2651930675 Digit_08_P4L 0;
BA_ "GenSigSendType" SG_ 2651930675 Digit_08_P4L 1;
BA_ "EventTrans" SG_ 2651930675 Digit_09_P4L 0;
BA_ "GenSigSendType" SG_ 2651930675 Digit_09_P4L 1;
BA_ "EventTrans" SG_ 2651930675 Digit_06_P4L 0;
BA_ "GenSigSendType" SG_ 2651930675 Digit_06_P4L 1;
BA_ "EventTrans" SG_ 2651930675 Digit_07_P4L 0;
BA_ "GenSigSendType" SG_ 2651930675 Digit_07_P4L 1;
BA_ "EventTrans" SG_ 2651930675 Digit_04_P4L 0;
BA_ "GenSigSendType" SG_ 2651930675 Digit_04_P4L 1;
BA_ "EventTrans" SG_ 2651930675 Digit_05_P4L 0;
BA_ "GenSigSendType" SG_ 2651930675 Digit_05_P4L 1;
BA_ "EventTrans" SG_ 2651930675 Digit_02_P4L 0;
BA_ "GenSigSendType" SG_ 2651930675 Digit_02_P4L 1;
BA_ "EventTrans" SG_ 2651930675 Digit_03_P4L 0;
BA_ "GenSigSendType" SG_ 2651930675 Digit_03_P4L 1;
BA_ "EventTrans" SG_ 2651930675 Digit_01_P4L 0;
BA_ "GenSigSendType" SG_ 2651930675 Digit_01_P4L 1;
BA_ "EventTrans" SG_ 2651930676 Digit_10_P4R 0;
BA_ "GenSigSendType" SG_ 2651930676 Digit_10_P4R 1;
BA_ "EventTrans" SG_ 2651930676 Digit_11_P4R 0;
BA_ "GenSigSendType" SG_ 2651930676 Digit_11_P4R 1;
BA_ "EventTrans" SG_ 2651930676 Digit_08_P4R 0;
BA_ "GenSigSendType" SG_ 2651930676 Digit_08_P4R 1;
BA_ "EventTrans" SG_ 2651930676 Digit_09_P4R 0;
BA_ "GenSigSendType" SG_ 2651930676 Digit_09_P4R 1;
BA_ "EventTrans" SG_ 2651930676 Digit_06_P4R 0;
BA_ "GenSigSendType" SG_ 2651930676 Digit_06_P4R 1;
BA_ "EventTrans" SG_ 2651930676 Digit_07_P4R 0;
BA_ "GenSigSendType" SG_ 2651930676 Digit_07_P4R 1;
BA_ "EventTrans" SG_ 2651930676 Digit_04_P4R 0;
BA_ "GenSigSendType" SG_ 2651930676 Digit_04_P4R 1;
BA_ "EventTrans" SG_ 2651930676 Digit_05_P4R 0;
BA_ "GenSigSendType" SG_ 2651930676 Digit_05_P4R 1;
BA_ "EventTrans" SG_ 2651930676 Digit_02_P4R 0;
BA_ "GenSigSendType" SG_ 2651930676 Digit_02_P4R 1;
BA_ "EventTrans" SG_ 2651930676 Digit_03_P4R 0;
BA_ "GenSigSendType" SG_ 2651930676 Digit_03_P4R 1;
BA_ "EventTrans" SG_ 2651930676 Digit_01_P4R 0;
BA_ "GenSigSendType" SG_ 2651930676 Digit_01_P4R 1;
BA_ "EventTrans" SG_ 2651930681 Digit_10_DASM 0;
BA_ "GenSigSendType" SG_ 2651930681 Digit_10_DASM 1;
BA_ "EventTrans" SG_ 2651930681 Digit_11_DASM 0;
BA_ "GenSigSendType" SG_ 2651930681 Digit_11_DASM 1;
BA_ "EventTrans" SG_ 2651930681 Digit_08_DASM 0;
BA_ "GenSigSendType" SG_ 2651930681 Digit_08_DASM 1;
BA_ "EventTrans" SG_ 2651930681 Digit_09_DASM 0;
BA_ "GenSigSendType" SG_ 2651930681 Digit_09_DASM 1;
BA_ "EventTrans" SG_ 2651930681 Digit_06_DASM 0;
BA_ "GenSigSendType" SG_ 2651930681 Digit_06_DASM 1;
BA_ "EventTrans" SG_ 2651930681 Digit_07_DASM 0;
BA_ "GenSigSendType" SG_ 2651930681 Digit_07_DASM 1;
BA_ "EventTrans" SG_ 2651930681 Digit_04_DASM 0;
BA_ "GenSigSendType" SG_ 2651930681 Digit_04_DASM 1;
BA_ "EventTrans" SG_ 2651930681 Digit_05_DASM 0;
BA_ "GenSigSendType" SG_ 2651930681 Digit_05_DASM 1;
BA_ "EventTrans" SG_ 2651930681 Digit_02_DASM 0;
BA_ "GenSigSendType" SG_ 2651930681 Digit_02_DASM 1;
BA_ "EventTrans" SG_ 2651930681 Digit_03_DASM 0;
BA_ "GenSigSendType" SG_ 2651930681 Digit_03_DASM 1;
BA_ "EventTrans" SG_ 2651930681 Digit_01_DASM 0;
BA_ "GenSigSendType" SG_ 2651930681 Digit_01_DASM 1;
BA_ "EventTrans" SG_ 2651930739 Digit_10_LCU 0;
BA_ "GenSigSendType" SG_ 2651930739 Digit_10_LCU 1;
BA_ "EventTrans" SG_ 2651930739 Digit_11_LCU 0;
BA_ "GenSigSendType" SG_ 2651930739 Digit_11_LCU 1;
BA_ "EventTrans" SG_ 2651930739 Digit_08_LCU 0;
BA_ "GenSigSendType" SG_ 2651930739 Digit_08_LCU 1;
BA_ "EventTrans" SG_ 2651930739 Digit_09_LCU 0;
BA_ "GenSigSendType" SG_ 2651930739 Digit_09_LCU 1;
BA_ "EventTrans" SG_ 2651930739 Digit_06_LCU 0;
BA_ "GenSigSendType" SG_ 2651930739 Digit_06_LCU 1;
BA_ "EventTrans" SG_ 2651930739 Digit_07_LCU 0;
BA_ "GenSigSendType" SG_ 2651930739 Digit_07_LCU 1;
BA_ "EventTrans" SG_ 2651930739 Digit_04_LCU 0;
BA_ "GenSigSendType" SG_ 2651930739 Digit_04_LCU 1;
BA_ "EventTrans" SG_ 2651930739 Digit_05_LCU 0;
BA_ "GenSigSendType" SG_ 2651930739 Digit_05_LCU 1;
BA_ "EventTrans" SG_ 2651930739 Digit_02_LCU 0;
BA_ "GenSigSendType" SG_ 2651930739 Digit_02_LCU 1;
BA_ "EventTrans" SG_ 2651930739 Digit_03_LCU 0;
BA_ "GenSigSendType" SG_ 2651930739 Digit_03_LCU 1;
BA_ "EventTrans" SG_ 2651930739 Digit_01_LCU 0;
BA_ "GenSigSendType" SG_ 2651930739 Digit_01_LCU 1;
BA_ "EventTrans" SG_ 2651930747 Digit_10_PCU_LH 0;
BA_ "GenSigSendType" SG_ 2651930747 Digit_10_PCU_LH 1;
BA_ "EventTrans" SG_ 2651930747 Digit_11_PCU_LH 0;
BA_ "GenSigSendType" SG_ 2651930747 Digit_11_PCU_LH 1;
BA_ "EventTrans" SG_ 2651930747 Digit_08_PCU_LH 0;
BA_ "GenSigSendType" SG_ 2651930747 Digit_08_PCU_LH 1;
BA_ "EventTrans" SG_ 2651930747 Digit_09_PCU_LH 0;
BA_ "GenSigSendType" SG_ 2651930747 Digit_09_PCU_LH 1;
BA_ "EventTrans" SG_ 2651930747 Digit_06_PCU_LH 0;
BA_ "GenSigSendType" SG_ 2651930747 Digit_06_PCU_LH 1;
BA_ "EventTrans" SG_ 2651930747 Digit_07_PCU_LH 0;
BA_ "GenSigSendType" SG_ 2651930747 Digit_07_PCU_LH 1;
BA_ "EventTrans" SG_ 2651930747 Digit_04_PCU_LH 0;
BA_ "GenSigSendType" SG_ 2651930747 Digit_04_PCU_LH 1;
BA_ "EventTrans" SG_ 2651930747 Digit_05_PCU_LH 0;
BA_ "GenSigSendType" SG_ 2651930747 Digit_05_PCU_LH 1;
BA_ "EventTrans" SG_ 2651930747 Digit_02_PCU_LH 0;
BA_ "GenSigSendType" SG_ 2651930747 Digit_02_PCU_LH 1;
BA_ "EventTrans" SG_ 2651930747 Digit_03_PCU_LH 0;
BA_ "GenSigSendType" SG_ 2651930747 Digit_03_PCU_LH 1;
BA_ "EventTrans" SG_ 2651930747 Digit_01_PCU_LH 0;
BA_ "GenSigSendType" SG_ 2651930747 Digit_01_PCU_LH 1;
BA_ "EventTrans" SG_ 2654208000 WakeRsn_BCM 0;
BA_ "GenSigSendType" SG_ 2654208000 WakeRsn_BCM 3;
BA_ "EventTrans" SG_ 2654208000 MainWakeSts_BCM 0;
BA_ "GenSigSendType" SG_ 2654208000 MainWakeSts_BCM 3;
BA_ "EventTrans" SG_ 2654208000 WakeCntr_BCM 0;
BA_ "GenSigSendType" SG_ 2654208000 WakeCntr_BCM 3;
BA_ "EventTrans" SG_ 2654208007 WakeRsn_NIT 0;
BA_ "GenSigSendType" SG_ 2654208007 WakeRsn_NIT 1;
BA_ "EventTrans" SG_ 2654208007 WakeReq_NIT 0;
BA_ "GenSigSendType" SG_ 2654208007 WakeReq_NIT 1;
BA_ "EventTrans" SG_ 2654208007 WakeCntr_NIT 0;
BA_ "GenSigSendType" SG_ 2654208007 WakeCntr_NIT 1;
BA_ "EventTrans" SG_ 2654208026 WakeRsn_NAB 0;
BA_ "GenSigSendType" SG_ 2654208026 WakeRsn_NAB 1;
BA_ "EventTrans" SG_ 2654208026 WakeReq_NAB 0;
BA_ "GenSigSendType" SG_ 2654208026 WakeReq_NAB 1;
BA_ "EventTrans" SG_ 2654208026 WakeCntr_NAB 0;
BA_ "GenSigSendType" SG_ 2654208026 WakeCntr_NAB 1;
BA_ "EventTrans" SG_ 2654208026 WakeUpNodeAddress 0;
BA_ "GenSigSendType" SG_ 2654208026 WakeUpNodeAddress 1;
BA_ "EventTrans" SG_ 2654208028 WakeRsn_NTP 0;
BA_ "GenSigSendType" SG_ 2654208028 WakeRsn_NTP 1;
BA_ "EventTrans" SG_ 2654208028 WakeReq_NTP 0;
BA_ "GenSigSendType" SG_ 2654208028 WakeReq_NTP 1;
BA_ "EventTrans" SG_ 2654208028 WakeCntr_NTP 0;
BA_ "GenSigSendType" SG_ 2654208028 WakeCntr_NTP 1;
BA_ "EventTrans" SG_ 2654208028 WakeUpNodeAddress 0;
BA_ "GenSigSendType" SG_ 2654208028 WakeUpNodeAddress 1;
BA_ "Accuracy" SG_ 2654339092 HVB_Crash_Output "—";
BA_ "GenSigStartValue" SG_ 2654339144 MotorMaxTemp_SFL 40;
BA_ "GenSigStartValue" SG_ 2654339144 MotorAvgTemp_SFL 40;
BA_ "InitialValue" SG_ 2654339144 KT_SFL 80;
BA_ "GenSigStartValue" SG_ 2654339145 MotorMaxTemp_SFR 40;
BA_ "GenSigStartValue" SG_ 2654339145 MotorAvgTemp_SFR 40;
BA_ "InitialValue" SG_ 2654339145 KT_SFR 80;
BA_ "GenSigStartValue" SG_ 2654339146 MotorMaxTemp_SRL 40;
BA_ "GenSigStartValue" SG_ 2654339146 MotorAvgTemp_SRL 40;
BA_ "InitialValue" SG_ 2654339146 KT_SRL 80;
BA_ "GenSigStartValue" SG_ 2654339147 MotorMaxTemp_SRR 40;
BA_ "GenSigStartValue" SG_ 2654339147 MotorAvgTemp_SRR 40;
BA_ "InitialValue" SG_ 2654339147 KT_SRR 80;
BA_ "EventTrans" SG_ 2658971643 ECU_APPL_NPE 0;
BA_ "GenSigSendType" SG_ 2658971643 ECU_APPL_NPE 3;
VAL_ 1504 FuelFlapSts 0 "Closed" 1 "Opened";
VAL_ 1504 FuelButtonSts 0 "Not_Pressed" 1 "Pressed";
VAL_ 1504 SleepReq_BCM 0 "Not_Active" 1 "Active";
VAL_ 1504 RechargeLedSts 0 "Off" 1 "White" 2 "Flashes_White" 3 "Green" 4 "Flashes_Green" 5 "Blue" 6 "Flashes_Blue" 7 "Red";
VAL_ 1504 RechargeFlapCableButtonSts 0 "Not_Pressed" 1 "Pressed";
VAL_ 1504 RechargeFlapSts_Extended 0 "Closed" 1 "Open" 2 "Automatic_Closing" 3 "Automatic_Opening" 4 "Middle_Position" 5 "Fail_Present" 6 "Not_Used" 7 "Not_Used";
VAL_ 1504 RechargeFlapAntipinch 0 "Not_Detected" 1 "Detected";
VAL_ 1504 NightDaySts 0 "Night" 1 "Day";
VAL_ 1504 AVHDriverDoorSts 0 "Closed" 1 "Open";
VAL_ 1504 Alcohol_Interlock_Inhibit 0 "Not_active" 1 "Active";
VAL_ 1504 TrunkFailSts 0 "Fail_Not_Present" 1 "Fail_Present";
VAL_ 1504 EngineBonnetSts_LH 0 "Closed" 1 "Open";
VAL_ 1504 RechargeFlapSts 0 "Closed" 1 "Open";
VAL_ 1530 GenericFailSts 0 "No_functional_fail_is_present" 1 "At_least_one_funct_fail_pres";
VAL_ 1530 CurrentFailSts 0 "No_functional_fail_is_present" 1 "DTCStatus_present";
VAL_ 1530 EOL 0 "No_EOL_prog_At_FIAT" 1 "EOL_prog_At_FIAT";
VAL_ 1530 D_ES 0 "Error_Active_State" 1 "Error_Passive_Warning_State" 2 "Bus_Off_State" 3 "Not_used";
VAL_ 1530 Left_LB_Feedback 0 "OFF" 1 "ON";
VAL_ 1530 LCUFailSts 0 "Fail_Not_present" 1 "Fail_present";
VAL_ 1530 Right_PL_FailSts 0 "Fail_Not_present" 1 "Fail_present";
VAL_ 1530 Left_PL_FailSts 0 "Fail_Not_present" 1 "Fail_present";
VAL_ 1530 Right_DRL_Feedback 0 "OFF" 1 "ON";
VAL_ 1530 Left_DRL_Feedback 0 "OFF" 1 "ON";
VAL_ 1530 Right_PL_Feedback 0 "OFF" 1 "ON";
VAL_ 1530 Left_PL_Feedback 0 "OFF" 1 "ON";
VAL_ 1530 Left_HB_Feedback 0 "OFF" 1 "ON";
VAL_ 1530 LVL_FailSts 0 "Fail_Not_present" 1 "Fail_present";
VAL_ 1530 FBLFailSts 0 "Fail_Not_present" 1 "Fail_present";
VAL_ 1530 Comp_HBFailSts 0 "Fail_Not_present" 1 "Fail_present";
VAL_ 1530 ADB_FailSts 0 "Fail_Not_present" 1 "Fail_present";
VAL_ 1530 Right_LB_FailSts 0 "Fail_Not_present" 1 "Fail_present";
VAL_ 1530 Left_LB_FailSts 0 "Fail_Not_present" 1 "Fail_present";
VAL_ 1530 Right_LB_Feedback 0 "OFF" 1 "ON";
VAL_ 1530 Left_DRL_FailSts 0 "Fail_Not_present" 1 "Fail_present";
VAL_ 1530 Right_TI_FailSts 0 "Fail_Not_present" 1 "Fail_present";
VAL_ 1530 Left_TI_FailSts 0 "Fail_Not_present" 1 "Fail_present";
VAL_ 1530 Right_TI_Feedback 0 "OFF" 1 "ON";
VAL_ 1530 Left_TI_Feedback 0 "OFF" 1 "ON";
VAL_ 1530 Right_HB_FailSts 0 "Fail_Not_present" 1 "Fail_present";
VAL_ 1530 Left_HB_FailSts 0 "Fail_Not_present" 1 "Fail_present";
VAL_ 1530 Right_HB_Feedback 0 "OFF" 1 "ON";
VAL_ 1530 TrafficChangeFbk 0 "Active_LeftSTD" 1 "Active_RightSTD" 2 "Active_LeftNoSTD" 3 "Active_RightNoSTD";
VAL_ 1530 ParkingLight_Feedback 0 "Not_Enable" 1 "Enable";
VAL_ 1530 Right_DRL_FailSts 0 "Fail_Not_present" 1 "Fail_present";
VAL_ 1722 TCUFailSts 0 "Fail_Not_Present" 1 "Fail_Present";
VAL_ 1722 PowerModeSts_TCU 0 "Standard_Power" 1 "Logistic_Mode_ON" 2 "Not_used" 3 "Not_used";
VAL_ 1722 SignalStrength 0 "Not_Connected" 1 "Bad" 2 "Average" 3 "Good" 4 "Best";
VAL_ 1722 TCUModemSts 0 "Off" 1 "Searching" 2 "_2G" 3 "_3G" 4 "_4G" 5 "_5G";
VAL_ 1728 RearWheelCircumference 112 "Not_Programmed";
VAL_ 1728 BatteryType 0 "IBS_not_present" 1 "Reserved" 2 "Reserved" 3 "Reserved" 4 "Reserved" 5 "Reserved" 6 "Reserved" 7 "Reserved" 8 "Reserved" 9 "A123_60Ah" 10 "Odissey_70_Ah" 11 "Odissey_95_Ah" 12 "FIAMM_80_Ah" 13 "FIAMM_95_Ah" 14 "FIAMM_70_Ah" 15 "ERROR";
VAL_ 1728 NCMSoftwareVariant 0 "Not_Programmed" 1 "europe" 2 "japan" 3 "taiwan" 4 "russia" 5 "usa" 6 "korea" 7 "China";
VAL_ 1728 EOL_CruiseControl 0 "Absent" 1 "Present";
VAL_ 1728 Rear_Doors 0 "Absent" 1 "Present";
VAL_ 1728 STOPANDSTART 0 "Absent" 1 "Present";
VAL_ 1728 Adaptive_Cruise_Control 0 "Not_present_in_this_config" 1 "Is_present_in_this_configuration";
VAL_ 1728 Forward_Collision_Mitigation 0 "Not_present_in_this_config" 1 "Is_present_in_this_configuration";
VAL_ 1728 Profile 0 "absent" 1 "present";
VAL_ 1728 Node_19_NSV 0 "Not_present_in_this_config" 1 "Is_present_in_this_configuration";
VAL_ 1728 EOL_PlockLimiter 0 "Disable" 1 "Enable";
VAL_ 1728 Engine_Fan_Management 0 "NCM" 1 "NBC";
VAL_ 1750 WCMR_IntErr_ThmDisconnect 0 "No Error" 1 "Error";
VAL_ 1750 WCMR_IntErr_CoilDisconnect 0 "No Error" 1 "Error";
VAL_ 1750 WCMR_IntErr_CoilOverTemp 0 "No_Error" 1 "Error";
VAL_ 1750 WCMR_IntErr_I2C_CommFault 0 "No Error" 1 "Error";
VAL_ 1750 WCMR_Status 0 "READY TO CHARGE" 1 "BASIC POWER PROFILE CHARGE" 2 "EXTENDED POWER PROFILE CHARGE" 3 "SAMSUNG FAST CHARGE" 4 "APPLE FAST CHARGE" 5 "CHARGE COMPLETE" 6 "SCAN FOR RX" 7 "BATTERY STAND BY" 8 "FOB STAND BY" 9 "FOREIGN OBJ DETECT ON CHARGE" 10 "FOREIGN OBJ DETECT Not CHARGING" 11 "Not used" 12 "Not used" 13 "Not used" 14 "Not used" 15 "SYSTEM ERROR";
VAL_ 1750 WCMR_IntErr_Eeprom_failure 0 "No_Error" 1 "Error";
VAL_ 1750 WCMR_IntErr_Reflash_aborted 0 "No Error" 1 "Error";
VAL_ 1750 ResponseErrorWCMR 0 "No Error" 1 "Error";
VAL_ 1750 KeepAliveWCMR 0 "no Request By slave" 1 "Request By slave";
VAL_ 1750 CurrentFailWCMR 0 "No Error" 1 "Error";
VAL_ 1750 GenericFailWCMR 0 "No Error" 1 "Error";
VAL_ 1752 IntErr_ThmDisconnect 0 "No_Error" 1 "Error";
VAL_ 1752 IntErr_CoilDisconnect 0 "No_Error" 1 "Error";
VAL_ 1752 IntErr_CoilOverTemp 0 "No_Error" 1 "Error";
VAL_ 1752 IntErr_I2C_CommFault 0 "NoError" 1 "Error";
VAL_ 1752 WCM_Status 0 "READY TO CHARGE" 1 "BASIC POWER PROFILE CHARGE" 2 "EXTENDED POWER PROFILE CHARGE" 3 "SAMSUNG FAST CHARGE" 4 "APPLE FAST CHARGE" 5 "CHARGE COMPLETE" 6 "SCAN FOR RX" 7 "BATTERY STAND BY" 8 "FOB STAND BY" 9 "FOREIGN OBJ DETECT ON CHARGE" 10 "FOREIGN OBJ DETECT Not CHARGING" 11 "Not used" 12 "Not used" 13 "Not used" 14 "Not used" 15 "SYSTEM ERROR";
VAL_ 1752 IntErr_Eeprom_failure 0 "No_Error" 1 "Error";
VAL_ 1752 IntErr_Reflash_aborted 0 "No_Error" 1 "Error";
VAL_ 1752 WCM_Node 0 "Absent" 1 "Present";
VAL_ 1752 ResponseErrorWCM 0 "No_Error" 1 "Error";
VAL_ 1752 KeepAliveWCM 0 "no_Request_By_slave" 1 "Request_By_slave";
VAL_ 1752 CurrentFailWCM 0 "No_Error" 1 "Error";
VAL_ 1752 GenericFailWCM 0 "No_Error" 1 "Error";
VAL_ 1852 ACC_Dist_fbk 0 "No_Setting" 1 "D1" 2 "D2" 3 "D3" 4 "D4" 5 "INIT" 6 "not_used" 7 "not_used";
VAL_ 1852 ACCFailReversibleSts_HMI 0 "No_ACC_Fail" 1 "ACC_Reversible_Fail" 2 "ACC_Irreversible_Fail" 3 "Not_used";
VAL_ 1852 DASMTemporaryFailSts_HMI 0 "Fail_not_present" 1 "Fail_present";
VAL_ 1852 DASMFailSts_HMI 0 "Fail_not_present" 1 "Fail_present";
VAL_ 1852 RadarBlinded_HMI 0 "Fail_not_present" 1 "Fail_present";
VAL_ 1852 FCWSystemSts 0 "Init" 1 "Off" 2 "On_Only_Warning" 3 "On_Only_Braking" 4 "On_Full" 5 "Not_used" 6 "Not_used" 7 "Not_used";
VAL_ 1852 HMICode_FCW 0 "Idle" 1 "Pre_Intervention_warning" 2 "Intervention_warning" 3 "Not_Available_warning_type1" 4 "Not_Available_warning_4WD_Low" 5 "Post_Intervention_warning" 6 "Not_used" 7 "Not_used" 8 "Not_used" 9 "Not_used" 10 "Not_used" 11 "Not_used" 12 "Not_used" 13 "Not_used" 14 "Not_used" 15 "Not_used" 16 "Not_used" 17 "Not_used" 18 "Not_used" 19 "Not_used" 20 "Not_used" 21 "Not_used" 22 "Not_used" 23 "Not_used" 24 "Not_used" 25 "Not_used" 26 "Not_used" 27 "Not_used" 28 "Not_used" 29 "Not_used" 30 "Not_used" 31 "Not_used" 32 "Not_used" 33 "Not_used" 34 "Not_used" 35 "Not_used" 36 "Not_used" 37 "Not_used" 38 "Not_used" 39 "Not_used" 40 "Not_used" 41 "Not_used" 42 "Not_used" 43 "Not_used" 44 "Not_used" 45 "Not_used" 46 "Not_used" 47 "Not_used" 48 "Not_used" 49 "Not_used" 50 "Not_used" 51 "Not_used" 52 "Not_used" 53 "Not_used" 54 "Not_used" 55 "Not_used" 56 "Not_used" 57 "Not_used" 58 "Not_used" 59 "Not_used" 60 "Not_used" 61 "Not_used" 62 "Not_used" 63 "Not_used";
VAL_ 1852 CameraBlinded_HMI 0 "Fail_not_present" 1 "Fail_Present";
VAL_ 1852 CameraFailure_HMI 0 "Fail_not_present" 1 "Fail_present";
VAL_ 1852 HMICode_ACC 0 "No_CODE" 1 "ACC_USER_DISABLED" 2 "ACC_USER_ENABLED_D1" 3 "ACC_USER_ENABLED_D2" 4 "ACC_USER_ENABLED_D3" 5 "ACC_USER_ENABLED_D4" 6 "ACC_SET_D1_TARGET" 7 "ACC_SET_D2_TARGET" 8 "ACC_SET_D3_TARGET" 9 "ACC_SET_D4_TARGET" 10 "ACC_SET_D1_NO_TARGET" 11 "ACC_SET_D2_NO_TARGET" 12 "ACC_SET_D3_NO_TARGET" 13 "ACC_SET_D4_NO_TARGET" 14 "ACC_CANCEL" 15 "ACC_CANCEL_D1" 16 "ACC_CANCEL_D2" 17 "ACC_CANCEL_D3" 18 "ACC_CANCEL_D4" 19 "ACC_CANCEL_SHIFT_D" 20 "ACC_CANCEL_BACKWARD" 21 "ACC_CANCEL_ESC_EVENT" 22 "ACC_CANCEL_HIGH_RPM" 23 "ACC_CANCEL_CHIME" 24 "ACC_CANCEL_EPB_ACTIVE" 25 "ACC_CANCEL_BELT" 26 "ACC_CANCEL_LIFTER_ON" 27 "ACC_UNAVAILABLE" 28 "ACC_UNAVAILABLE_BRAKE_APPLIED" 29 "ACC_UNAVAILABLE_BELT" 30 "ACC_UNAVAILABLE_OBST_DETECTED" 31 "ACC_UNAVAILABLE_ABOVE_MAX_SPEED" 32 "ACC_UNAVAILABLE_EPB_ACTIVE" 33 "ACC_UNAVAILABLE_ESC_EVENT" 34 "ACC_UNAVAILABLE_DRIVE_MODE" 35 "ACC_UNAVAILABLE_BACKWARD" 36 "ACC_UNAVAILABLE_SHIFT_D" 37 "ACC_UNAVAILABLE_LIFTER_ON" 38 "ACC_STOP_GO_AUTO_DRIVE_OFF" 39 "ACC_STOP_GO_RESUME_NEEDED" 40 "ACC_PROX_WARNING" 41 "ACC_OVERRIDE" 42 "ACC_UNAVAILABLE_BRAKES_COOLING" 43 "ACC_CANC_BRAKE_COOLING" 44 "ACC_OVERTAKE_INIBITHION" 45 "ACC_CANC_ROAD_TOO_STEEP" 46 "ACC_UNAVAILABLE_ROAD_TOO_STEEP" 47 "ACC_UNAVAILABLE_DOOR_OPEN" 48 "ACC_CANC_DOOR_OPEN" 49 "ACC_FRONT_RADAR_SENSOR_PLANTMODE" 50 "ACC_UNAVAILABLE_LOW_RPM" 51 "ACC_UNAVAILABLE_HIGH_RPM" 52 "ACC_CAMERA_FAIL" 53 "ACC_CAMERA_BLINDED" 54 "ACC_MAX_SPEED_EDRIVE_BELOW" 55 "ACC_MAX_SPEED_EDRIVE_ABOVE" 56 "ACC_DRIVEOFF_WNG_OPTICAL" 57 "ACC_DRIVEOFF_WNG_OPTICAL_ACL_1" 58 "ACC_DRIVEOFF_WNG_OPTICAL_ACL_2" 59 "ACC_HDC_Active" 60 "ACC_MAX_SPEED_ECO_BELOW" 61 "ACC_MAX_SPEED_ECO_ABOVE" 62 "ACC_MAX_SPEED_STD_BELOW" 63 "ACC_MAX_SPEED_STD_ABOVE" 64 "ACC_MAX_SPEED_PERF_BELOW" 65 "ACC_MAX_SPEED_PERF_ABOVE" 66 "ACC_LONG_PRESS_TO_ENA_NEEDED" 67 "Not_used" 68 "Not_used" 69 "Not_used" 70 "Not_used" 71 "Not_used" 72 "Not_used" 73 "Not_used" 74 "Not_used" 75 "Not_used" 76 "Not_used" 77 "Not_used" 78 "Not_used" 79 "Not_used" 80 "Not_used" 81 "Not_used" 82 "Not_used" 83 "Not_used" 84 "Not_used" 85 "Not_used" 86 "Not_used" 87 "Not_used" 88 "Not_used" 89 "Not_used" 90 "Not_used" 91 "Not_used" 92 "Not_used" 93 "Not_used" 94 "Not_used" 95 "Not_used" 96 "Not_used" 97 "Not_used" 98 "Not_used" 99 "Not_used" 100 "Not_used" 101 "Not_used" 102 "Not_used" 103 "Not_used" 104 "Not_used" 105 "Not_used" 106 "Not_used" 107 "Not_used" 108 "Not_used" 109 "Not_used" 110 "Not_used" 111 "Not_used" 112 "Not_used" 113 "Not_used" 114 "Not_used" 115 "Not_used" 116 "Not_used" 117 "Not_used" 118 "Not_used" 119 "Not_used" 120 "Not_used" 121 "Not_used" 122 "Not_used" 123 "Not_used" 124 "Not_used" 125 "Not_used" 126 "Not_used" 127 "Not_used" 128 "Not_used" 129 "Not_used" 130 "Not_used" 131 "Not_used" 132 "Not_used" 133 "Not_used" 134 "Not_used" 135 "Not_used" 136 "Not_used" 137 "Not_used" 138 "Not_used" 139 "Not_used" 140 "Not_used" 141 "Not_used" 142 "Not_used" 143 "Not_used" 144 "Not_used" 145 "Not_used" 146 "Not_used" 147 "Not_used" 148 "Not_used" 149 "Not_used" 150 "Not_used" 151 "Not_used" 152 "Not_used" 153 "Not_used" 154 "Not_used" 155 "Not_used" 156 "Not_used" 157 "Not_used" 158 "Not_used" 159 "Not_used" 160 "Not_used" 161 "Not_used" 162 "Not_used" 163 "Not_used" 164 "Not_used" 165 "Not_used" 166 "Not_used" 167 "Not_used" 168 "Not_used" 169 "Not_used" 170 "Not_used" 171 "Not_used" 172 "Not_used" 173 "Not_used" 174 "Not_used" 175 "Not_used" 176 "Not_used" 177 "Not_used" 178 "Not_used" 179 "Not_used" 180 "Not_used" 181 "Not_used" 182 "Not_used" 183 "Not_used" 184 "Not_used" 185 "Not_used" 186 "Not_used" 187 "Not_used" 188 "Not_used" 189 "Not_used" 190 "Not_used" 191 "Not_used" 192 "Not_used" 193 "Not_used" 194 "Not_used" 195 "Not_used" 196 "Not_used" 197 "Not_used" 198 "Not_used" 199 "Not_used" 200 "Not_used" 201 "Not_used" 202 "Not_used" 203 "Not_used" 204 "Not_used" 205 "Not_used" 206 "Not_used" 207 "Not_used" 208 "Not_used" 209 "Not_used" 210 "Not_used" 211 "Not_used" 212 "Not_used" 213 "Not_used" 214 "Not_used" 215 "Not_used" 216 "Not_used" 217 "Not_used" 218 "Not_used" 219 "Not_used" 220 "Not_used" 221 "Not_used" 222 "Not_used" 223 "Not_used" 224 "Not_used" 225 "Not_used" 226 "Not_used" 227 "Not_used" 228 "Not_used" 229 "Not_used" 230 "Not_used" 231 "Not_used" 232 "Not_used" 233 "Not_used" 234 "Not_used" 235 "Not_used" 236 "Not_used" 237 "Not_used" 238 "Not_used" 239 "Not_used" 240 "Not_used" 241 "Not_used" 242 "Not_used" 243 "Not_used" 244 "Not_used" 245 "Not_used" 246 "Not_used" 247 "Not_used" 248 "Not_used" 249 "Not_used" 250 "Not_used" 251 "Not_used" 252 "Not_used" 253 "Not_used" 254 "Not_used" 255 "Not_used";
VAL_ 1852 ACCFailSts_HMI 0 "Fail_not_present" 1 "Fail_Present";
VAL_ 1852 HMIDisplay_ACC 0 "No_Code" 1 "ACC_USER_DISABLED" 2 "ACC_USER_ENABLED_D1" 3 "ACC_USER_ENABLED_D2" 4 "ACC_USER_ENABLED_D3" 5 "ACC_USER_ENABLED_D4" 6 "ACC_SET_D1_TARGET" 7 "ACC_SET_D2_TARGET" 8 "ACC_SET_D3_TARGET" 9 "ACC_SET_D4_TARGET" 10 "ACC_SET_D1_NO_TARGET" 11 "ACC_SET_D2_NO_TARGET" 12 "ACC_SET_D3_NO_TARGET" 13 "ACC_SET_D4_NO_TARGET" 14 "ACC_CANCEL_D1" 15 "ACC_CANCEL_D2" 16 "ACC_CANCEL_D3" 17 "ACC_CANCEL_D4" 18 "ACC_CANCEL" 19 "ACC_ENABLED" 20 "ACC_SET" 21 "ACC_RESUME" 22 "ACC_OVERRIDE" 23 "ACC_OVERRIDE_D1" 24 "ACC_OVERRIDE_D2" 25 "ACC_OVERRIDE_D3" 26 "ACC_OVERRIDE_D4" 27 "NCC_CANCEL" 28 "NCC_USER_ENABLED" 29 "NCC_SET" 30 "NCC_RESUME" 31 "NCC_USER_DISABLED" 32 "NCC_OVERRIDE" 33 "ACC_UNAVAILABLE_HDC" 34 "Not_used" 35 "Not_used" 36 "Not_used" 37 "Not_used" 38 "Not_used" 39 "Not_used" 40 "Not_used" 41 "Not_used" 42 "Not_used" 43 "Not_used" 44 "Not_used" 45 "Not_used" 46 "Not_used" 47 "Not_used" 48 "Not_used" 49 "Not_used" 50 "Not_used" 51 "Not_used" 52 "Not_used" 53 "Not_used" 54 "Not_used" 55 "Not_used" 56 "Not_used" 57 "Not_used" 58 "Not_used" 59 "Not_used" 60 "Not_used" 61 "Not_used" 62 "Not_used" 63 "Not_used";
VAL_ 1852 FCWSensibilitySts 0 "Near" 1 "Med" 2 "Far" 3 "INIT";
VAL_ 1852 ACC_RadarBlinded_HMI 0 "Fail_not_present" 1 "Fail_present";
VAL_ 1852 ACCSystemSts_HMI 0 "OFF" 1 "Enabled" 2 "Engaged" 3 "Engaged_BrakeOnly" 4 "Override" 5 "Cancel" 6 "Not_used" 7 "Not_used";
VAL_ 1853 ACC_TargetDistance 0 "_0" 1 "_1" 2 "_2" 3 "_3" 4 "_4" 5 "_5" 6 "_6" 7 "_7" 8 "_8" 9 "_9" 10 "_10" 11 "_11" 12 "_12" 13 "_13" 14 "_14" 15 "_15" 16 "_16" 17 "_17" 18 "_18" 19 "_19" 20 "_20" 21 "_21" 22 "_22" 23 "_23" 24 "_24" 25 "_25" 26 "_26" 27 "_27" 28 "_28" 29 "_29" 30 "_30" 31 "_31" 32 "_32" 33 "_33" 34 "_34" 35 "_35" 36 "_36" 37 "_37" 38 "_38" 39 "_39" 40 "_40" 41 "_41" 42 "_42" 43 "_43" 44 "_44" 45 "_45" 46 "_46" 47 "_47" 48 "_48" 49 "_49" 50 "_50" 51 "_51" 52 "_52" 53 "_53" 54 "_54" 55 "_55" 56 "_56" 57 "_57" 58 "_58" 59 "_59" 60 "_60" 61 "_61" 62 "_62" 63 "_63" 64 "_64" 65 "_65" 66 "_66" 67 "_67" 68 "_68" 69 "_69" 70 "_70" 71 "_71" 72 "_72" 73 "_73" 74 "_74" 75 "_75" 76 "_76" 77 "_77" 78 "_78" 79 "_79" 80 "_80" 81 "_81" 82 "_82" 83 "_83" 84 "_84" 85 "_85" 86 "_86" 87 "_87" 88 "_88" 89 "_89" 90 "_90" 91 "_91" 92 "_92" 93 "_93" 94 "_94" 95 "_95" 96 "_96" 97 "_97" 98 "_98" 99 "_99" 100 "_100" 101 "_101" 102 "_102" 103 "_103" 104 "_104" 105 "_105" 106 "_106" 107 "_107" 108 "_108" 109 "_109" 110 "_110" 111 "_111" 112 "_112" 113 "_113" 114 "_114" 115 "_115" 116 "_116" 117 "_117" 118 "_118" 119 "_119" 120 "_120" 121 "_121" 122 "_122" 123 "_123" 124 "_124" 125 "_125" 126 "_126" 127 "_127" 128 "_128" 129 "_129" 130 "_130" 131 "_131" 132 "_132" 133 "_133" 134 "_134" 135 "_135" 136 "_136" 137 "_137" 138 "_138" 139 "_139" 140 "_140" 141 "_141" 142 "_142" 143 "_143" 144 "_144" 145 "_145" 146 "_146" 147 "_147" 148 "_148" 149 "_149" 150 "_150" 151 "_151" 152 "_152" 153 "_153" 154 "_154" 155 "_155" 156 "_156" 157 "_157" 158 "_158" 159 "_159" 160 "_160" 161 "_161" 162 "_162" 163 "_163" 164 "_164" 165 "_165" 166 "_166" 167 "_167" 168 "_168" 169 "_169" 170 "_170" 171 "_171" 172 "_172" 173 "_173" 174 "_174" 175 "_175" 176 "_176" 177 "_177" 178 "_178" 179 "_179" 180 "_180" 181 "_181" 182 "_182" 183 "_183" 184 "_184" 185 "_185" 186 "_186" 187 "_187" 188 "_188" 189 "_189" 190 "_190" 191 "_191" 192 "_192" 193 "_193" 194 "_194" 195 "_195" 196 "_196" 197 "_197" 198 "_198" 199 "_199" 200 "_200" 201 "_201" 202 "_202" 203 "_203" 204 "_204" 205 "_205" 206 "_206" 207 "_207" 208 "_208" 209 "_209" 210 "_210" 211 "_211" 212 "_212" 213 "_213" 214 "_214" 215 "_215" 216 "_216" 217 "_217" 218 "_218" 219 "_219" 220 "_220" 221 "_221" 222 "_222" 223 "_223" 224 "_224" 225 "_225" 226 "_226" 227 "_227" 228 "_228" 229 "_229" 230 "_230" 231 "_231" 232 "_232" 233 "_233" 234 "_234" 235 "_235" 236 "_236" 237 "_237" 238 "_238" 239 "_239" 240 "_240" 241 "_241" 242 "_242" 243 "_243" 244 "_244" 245 "_245" 246 "_246" 247 "_247" 248 "_248" 249 "_249" 250 "_250" 251 "_251" 252 "_252" 253 "_253" 254 "_254" 255 "_255" 256 "_256" 257 "_257" 258 "_258" 259 "_259" 260 "_260" 261 "_261" 262 "_262" 263 "_263" 264 "_264" 265 "_265" 266 "_266" 267 "_267" 268 "_268" 269 "_269" 270 "_270" 271 "_271" 272 "_272" 273 "_273" 274 "_274" 275 "_275" 276 "_276" 277 "_277" 278 "_278" 279 "_279" 280 "_280" 281 "_281" 282 "_282" 283 "_283" 284 "_284" 285 "_285" 286 "_286" 287 "_287" 288 "_288" 289 "_289" 290 "_290" 291 "_291" 292 "_292" 293 "_293" 294 "_294" 295 "_295" 296 "_296" 297 "_297" 298 "_298" 299 "_299" 300 "_300" 301 "not_used" 302 "not_used" 303 "not_used" 304 "not_used" 305 "not_used" 306 "not_used" 307 "not_used" 308 "not_used" 309 "not_used" 310 "not_used" 311 "not_used" 312 "not_used" 313 "not_used" 314 "not_used" 315 "not_used" 316 "not_used" 317 "not_used" 318 "not_used" 319 "not_used" 320 "not_used" 321 "not_used" 322 "not_used" 323 "not_used" 324 "not_used" 325 "not_used" 326 "not_used" 327 "not_used" 328 "not_used" 329 "not_used" 330 "not_used" 331 "not_used" 332 "not_used" 333 "not_used" 334 "not_used" 335 "not_used" 336 "not_used" 337 "not_used" 338 "not_used" 339 "not_used" 340 "not_used" 341 "not_used" 342 "not_used" 343 "not_used" 344 "not_used" 345 "not_used" 346 "not_used" 347 "not_used" 348 "not_used" 349 "not_used" 350 "not_used" 351 "not_used" 352 "not_used" 353 "not_used" 354 "not_used" 355 "not_used" 356 "not_used" 357 "not_used" 358 "not_used" 359 "not_used" 360 "not_used" 361 "not_used" 362 "not_used" 363 "not_used" 364 "not_used" 365 "not_used" 366 "not_used" 367 "not_used" 368 "not_used" 369 "not_used" 370 "not_used" 371 "not_used" 372 "not_used" 373 "not_used" 374 "not_used" 375 "not_used" 376 "not_used" 377 "not_used" 378 "not_used" 379 "not_used" 380 "not_used" 381 "not_used" 382 "not_used" 383 "not_used" 384 "not_used" 385 "not_used" 386 "not_used" 387 "not_used" 388 "not_used" 389 "not_used" 390 "not_used" 391 "not_used" 392 "not_used" 393 "not_used" 394 "not_used" 395 "not_used" 396 "not_used" 397 "not_used" 398 "not_used" 399 "not_used" 400 "not_used" 401 "not_used" 402 "not_used" 403 "not_used" 404 "not_used" 405 "not_used" 406 "not_used" 407 "not_used" 408 "not_used" 409 "not_used" 410 "not_used" 411 "not_used" 412 "not_used" 413 "not_used" 414 "not_used" 415 "not_used" 416 "not_used" 417 "not_used" 418 "not_used" 419 "not_used" 420 "not_used" 421 "not_used" 422 "not_used" 423 "not_used" 424 "not_used" 425 "not_used" 426 "not_used" 427 "not_used" 428 "not_used" 429 "not_used" 430 "not_used" 431 "not_used" 432 "not_used" 433 "not_used" 434 "not_used" 435 "not_used" 436 "not_used" 437 "not_used" 438 "not_used" 439 "not_used" 440 "not_used" 441 "not_used" 442 "not_used" 443 "not_used" 444 "not_used" 445 "not_used" 446 "not_used" 447 "not_used" 448 "not_used" 449 "not_used" 450 "not_used" 451 "not_used" 452 "not_used" 453 "not_used" 454 "not_used" 455 "not_used" 456 "not_used" 457 "not_used" 458 "not_used" 459 "not_used" 460 "not_used" 461 "not_used" 462 "not_used" 463 "not_used" 464 "not_used" 465 "not_used" 466 "not_used" 467 "not_used" 468 "not_used" 469 "not_used" 470 "not_used" 471 "not_used" 472 "not_used" 473 "not_used" 474 "not_used" 475 "not_used" 476 "not_used" 477 "not_used" 478 "not_used" 479 "not_used" 480 "not_used" 481 "not_used" 482 "not_used" 483 "not_used" 484 "not_used" 485 "not_used" 486 "not_used" 487 "not_used" 488 "not_used" 489 "not_used" 490 "not_used" 491 "not_used" 492 "not_used" 493 "not_used" 494 "not_used" 495 "not_used" 496 "not_used" 497 "not_used" 498 "not_used" 499 "not_used" 500 "not_used" 501 "not_used" 502 "not_used" 503 "not_used" 504 "not_used" 505 "not_used" 506 "not_used" 507 "not_used" 508 "not_used" 509 "not_used" 510 "Not_Valid" 511 "Target_not_found";
VAL_ 1853 ACC_DesiredDistance 0 "_0" 1 "_1" 2 "_2" 3 "_3" 4 "_4" 5 "_5" 6 "_6" 7 "_7" 8 "_8" 9 "_9" 10 "_10" 11 "_11" 12 "_12" 13 "_13" 14 "_14" 15 "_15" 16 "_16" 17 "_17" 18 "_18" 19 "_19" 20 "_20" 21 "_21" 22 "_22" 23 "_23" 24 "_24" 25 "_25" 26 "_26" 27 "_27" 28 "_28" 29 "_29" 30 "_30" 31 "_31" 32 "_32" 33 "_33" 34 "_34" 35 "_35" 36 "_36" 37 "_37" 38 "_38" 39 "_39" 40 "_40" 41 "_41" 42 "_42" 43 "_43" 44 "_44" 45 "_45" 46 "_46" 47 "_47" 48 "_48" 49 "_49" 50 "_50" 51 "_51" 52 "_52" 53 "_53" 54 "_54" 55 "_55" 56 "_56" 57 "_57" 58 "_58" 59 "_59" 60 "_60" 61 "_61" 62 "_62" 63 "_63" 64 "_64" 65 "_65" 66 "_66" 67 "_67" 68 "_68" 69 "_69" 70 "_70" 71 "_71" 72 "_72" 73 "_73" 74 "_74" 75 "_75" 76 "_76" 77 "_77" 78 "_78" 79 "_79" 80 "_80" 81 "_81" 82 "_82" 83 "_83" 84 "_84" 85 "_85" 86 "_86" 87 "_87" 88 "_88" 89 "_89" 90 "_90" 91 "_91" 92 "_92" 93 "_93" 94 "_94" 95 "_95" 96 "_96" 97 "_97" 98 "_98" 99 "_99" 100 "_100" 101 "_101" 102 "_102" 103 "_103" 104 "_104" 105 "_105" 106 "_106" 107 "_107" 108 "_108" 109 "_109" 110 "_110" 111 "_111" 112 "_112" 113 "_113" 114 "_114" 115 "_115" 116 "_116" 117 "_117" 118 "_118" 119 "_119" 120 "_120" 121 "_121" 122 "_122" 123 "_123" 124 "_124" 125 "Not_used" 126 "Not_used" 127 "No_desired_Distance";
VAL_ 1853 ACC_TargetRelativeVelocity 1022 "Not_Valid" 1023 "Target_not_found";
VAL_ 1853 ACC_LateralTarget 0 "None" 1 "Cut_In_From_Left" 2 "Cut_In_From_Right" 3 "Cut_Out_To_Left" 4 "Cut_Out_To_Right" 5 "Approaching" 6 "Leaving" 7 "Cut_In_From_Left_add" 8 "Cut_In_From_Right_add" 9 "Cut_Out_To_Left_add" 10 "Cut_Out_To_Right_add" 11 "Not_used" 12 "Not_used" 13 "Not_used" 14 "Not_used" 15 "SNA";
VAL_ 1853 ACC_SetSpeedKPH 255 "SNA";
VAL_ 1853 ACC_SetSpeedMPH 255 "SNA";
VAL_ 1955 WCM_Status 0 "READY_TO_CHARGE" 1 "BASIC_POWER_PROFILE_CHARGE" 2 "EXTENDED_POWER_PROFILE_CHARGE" 3 "SAMSUNG_FAST_CHARGE" 4 "APPLE_FAST_CHARGE" 5 "CHARGE_COMPLETE" 6 "SCAN_FOR_RX" 7 "BATTERY_STAND_BY" 8 "FOB_STAND_BY" 9 "FOREIGN_OBJ_DETECT_ON_CHARGE" 10 "FOREIGN_OBJ_DETECT_Not_CHARGING" 11 "Not_used" 12 "Not_used" 13 "Not_used" 14 "Not_used" 15 "SYSTEM_ERROR";
VAL_ 1955 ElectricSteeringLamp_FailSts 0 "OFF_Fail_not_present" 1 "OFF_Fail_present" 2 "ON_Fail_not_present" 3 "Not_used";
VAL_ 1955 VDCLamp_FailSts 0 "OFF_Fail_not_present" 1 "OFF_Fail_present" 2 "ON_Fail_not_present" 3 "Not_used";
VAL_ 1955 EBDLamp_FailSts 0 "OFF_Fail_not_present" 1 "OFF_Fail_present" 2 "ON_Fail_not_present" 3 "Not_used";
VAL_ 1955 ABSLamp_FailSts 0 "OFF_Fail_not_present" 1 "OFF_Fail_present" 2 "ON_Fail_not_present" 3 "Not_used";
VAL_ 1955 InternalLightLevel 0 "Level_1" 1 "Level_2" 2 "Level_3" 3 "Level_4" 4 "Level_5" 5 "Level_6" 6 "Level_7" 7 "Level_8" 8 "Level_9" 9 "Level_10" 10 "Level_11" 11 "Level_12" 12 "Level_13" 13 "Level_14" 14 "Level_15" 15 "Level_16";
VAL_ 2654208000 WakeRsn_BCM 0 "'Diag'" 1 "'Network'" 2 "Trunk_Opening_Closing" 3 "Trunk_Movement_Request" 4 "Front_Bonnet_Closing" 5 "'WakeRsn5'" 6 "'WakeRsn6'" 7 "'WakeRsn7'" 8 "'WakeRsn8'" 9 "'WakeRsn9'" 10 "'WakeRsn10'" 11 "'WakeRsn11'" 12 "'WakeRsn12'" 13 "'WakeRsn13'" 14 "'WakeRsn14'" 15 "'WakeRsn15'" 16 "'WakeRsn16'" 17 "'WakeRsn17'" 18 "'WakeRsn18'" 19 "'WakeRsn19'" 20 "'WakeRsn20'" 21 "'WakeRsn21'" 22 "'WakeRsn22'" 23 "'WakeRsn23'" 24 "'WakeRsn24'" 25 "'WakeRsn25'" 26 "'WakeRsn26'" 27 "'WakeRsn27'" 28 "'WakeRsn28'" 29 "'WakeRsn29'" 30 "'WakeRsn30'" 31 "'WakeRsn31'" 32 "'WakeRsn32'" 33 "'WakeRsn33'" 34 "'WakeRsn34'" 35 "'WakeRsn35'" 36 "'WakeRsn36'" 37 "'WakeRsn37'" 38 "'WakeRsn38'" 39 "'WakeRsn39'" 40 "'WakeRsn40'" 41 "'WakeRsn41'" 42 "'WakeRsn42'" 43 "'WakeRsn43'" 44 "'WakeRsn44'" 45 "'WakeRsn45'" 46 "'WakeRsn46'" 47 "'WakeRsn47'" 48 "'WakeRsn48'" 49 "'WakeRsn49'" 50 "'WakeRsn50'" 51 "'WakeRsn51'" 52 "'WakeRsn52'" 53 "'WakeRsn53'" 54 "'WakeRsn54'" 55 "'WakeRsn55'" 56 "'WakeRsn56'" 57 "'WakeRsn57'" 58 "'WakeRsn58'" 59 "'WakeRsn59'" 60 "'WakeRsn60'" 61 "'WakeRsn61'" 62 "'WakeRsn62'" 63 "'WakeRsn63'" 64 "'WakeRsn64'" 65 "'WakeRsn65'" 66 "'WakeRsn66'" 67 "'WakeRsn67'" 68 "'WakeRsn68'" 69 "'WakeRsn69'" 70 "'WakeRsn70'" 71 "'WakeRsn71'" 72 "'WakeRsn72'" 73 "'WakeRsn73'" 74 "'WakeRsn74'" 75 "'WakeRsn75'" 76 "'WakeRsn76'" 77 "'WakeRsn77'" 78 "'WakeRsn78'" 79 "'WakeRsn79'" 80 "'WakeRsn80'" 81 "'WakeRsn81'" 82 "'WakeRsn82'" 83 "'WakeRsn83'" 84 "'WakeRsn84'" 85 "'WakeRsn85'" 86 "'WakeRsn86'" 87 "'WakeRsn87'" 88 "'WakeRsn88'" 89 "'WakeRsn89'" 90 "'WakeRsn90'" 91 "'WakeRsn91'" 92 "'WakeRsn92'" 93 "'WakeRsn93'" 94 "'WakeRsn94'" 95 "'WakeRsn95'" 96 "'WakeRsn96'" 97 "'WakeRsn97'" 98 "'WakeRsn98'" 99 "'WakeRsn99'" 100 "'WakeRsn100'" 101 "'WakeRsn101'" 102 "'WakeRsn102'" 103 "'WakeRsn103'" 104 "'WakeRsn104'" 105 "'WakeRsn105'" 106 "'WakeRsn106'" 107 "'WakeRsn107'" 108 "'WakeRsn108'" 109 "'WakeRsn109'" 110 "'WakeRsn110'" 111 "'WakeRsn111'" 112 "'WakeRsn112'" 113 "'WakeRsn113'" 114 "'WakeRsn114'" 115 "'WakeRsn115'" 116 "'WakeRsn116'" 117 "'WakeRsn117'" 118 "'WakeRsn118'" 119 "'WakeRsn119'" 120 "'WakeRsn120'" 121 "'WakeRsn121'" 122 "'WakeRsn122'" 123 "'WakeRsn123'" 124 "'WakeRsn124'" 125 "'WakeRsn125'" 126 "'WakeRsn126'" 127 "'WakeRsn127'";
VAL_ 2654208000 MainWakeSts_BCM 0 "'Not_Active'" 1 "'Active'";
VAL_ 2654208000 Node28 0 "'Not_active'" 1 "'Active'";
VAL_ 2654208000 Node29 0 "'Not_active'" 1 "'Active'";
VAL_ 2654208000 Node21 0 "'Not_active'" 1 "'Active'";
VAL_ 2654208000 Node9 0 "'Not_active'" 1 "'Active'";
VAL_ 2654208000 Node11 0 "'Not_active'" 1 "'Active'";
VAL_ 2654208000 Node0 0 "'Not_active'" 1 "'Active'";
VAL_ 2654208003 WakeRsn_NQS 0 "'Diag'" 1 "'Network'" 2 "'WakeRsn2'" 3 "'WakeRsn3'" 4 "'WakeRsn4'" 5 "'WakeRsn5'" 6 "'WakeRsn6'" 7 "'WakeRsn7'" 8 "'WakeRsn8'" 9 "'WakeRsn9'" 10 "'WakeRsn10'" 11 "'WakeRsn11'" 12 "'WakeRsn12'" 13 "'WakeRsn13'" 14 "'WakeRsn14'" 15 "'WakeRsn15'" 16 "'WakeRsn16'" 17 "'WakeRsn17'" 18 "'WakeRsn18'" 19 "'WakeRsn19'" 20 "'WakeRsn20'" 21 "'WakeRsn21'" 22 "'WakeRsn22'" 23 "'WakeRsn23'" 24 "'WakeRsn24'" 25 "'WakeRsn25'" 26 "'WakeRsn26'" 27 "'WakeRsn27'" 28 "'WakeRsn28'" 29 "'WakeRsn29'" 30 "'WakeRsn30'" 31 "'WakeRsn31'" 32 "'WakeRsn32'" 33 "'WakeRsn33'" 34 "'WakeRsn34'" 35 "'WakeRsn35'" 36 "'WakeRsn36'" 37 "'WakeRsn37'" 38 "'WakeRsn38'" 39 "'WakeRsn39'" 40 "'WakeRsn40'" 41 "'WakeRsn41'" 42 "'WakeRsn42'" 43 "'WakeRsn43'" 44 "'WakeRsn44'" 45 "'WakeRsn45'" 46 "'WakeRsn46'" 47 "'WakeRsn47'" 48 "'WakeRsn48'" 49 "'WakeRsn49'" 50 "'WakeRsn50'" 51 "'WakeRsn51'" 52 "'WakeRsn52'" 53 "'WakeRsn53'" 54 "'WakeRsn54'" 55 "'WakeRsn55'" 56 "'WakeRsn56'" 57 "'WakeRsn57'" 58 "'WakeRsn58'" 59 "'WakeRsn59'" 60 "'WakeRsn60'" 61 "'WakeRsn61'" 62 "'WakeRsn62'" 63 "'WakeRsn63'" 64 "'WakeRsn64'" 65 "'WakeRsn65'" 66 "'WakeRsn66'" 67 "'WakeRsn67'" 68 "'WakeRsn68'" 69 "'WakeRsn69'" 70 "'WakeRsn70'" 71 "'WakeRsn71'" 72 "'WakeRsn72'" 73 "'WakeRsn73'" 74 "'WakeRsn74'" 75 "'WakeRsn75'" 76 "'WakeRsn76'" 77 "'WakeRsn77'" 78 "'WakeRsn78'" 79 "'WakeRsn79'" 80 "'WakeRsn80'" 81 "'WakeRsn81'" 82 "'WakeRsn82'" 83 "'WakeRsn83'" 84 "'WakeRsn84'" 85 "'WakeRsn85'" 86 "'WakeRsn86'" 87 "'WakeRsn87'" 88 "'WakeRsn88'" 89 "'WakeRsn89'" 90 "'WakeRsn90'" 91 "'WakeRsn91'" 92 "'WakeRsn92'" 93 "'WakeRsn93'" 94 "'WakeRsn94'" 95 "'WakeRsn95'" 96 "'WakeRsn96'" 97 "'WakeRsn97'" 98 "'WakeRsn98'" 99 "'WakeRsn99'" 100 "'WakeRsn100'" 101 "'WakeRsn101'" 102 "'WakeRsn102'" 103 "'WakeRsn103'" 104 "'WakeRsn104'" 105 "'WakeRsn105'" 106 "'WakeRsn106'" 107 "'WakeRsn107'" 108 "'WakeRsn108'" 109 "'WakeRsn109'" 110 "'WakeRsn110'" 111 "'WakeRsn111'" 112 "'WakeRsn112'" 113 "'WakeRsn113'" 114 "'WakeRsn114'" 115 "'WakeRsn115'" 116 "'WakeRsn116'" 117 "'WakeRsn117'" 118 "'WakeRsn118'" 119 "'WakeRsn119'" 120 "'WakeRsn120'" 121 "'WakeRsn121'" 122 "'WakeRsn122'" 123 "'WakeRsn123'" 124 "'WakeRsn124'" 125 "'WakeRsn125'" 126 "'WakeRsn126'" 127 "'WakeRsn127'";
VAL_ 2654208003 WakeReq_NQS 0 "'NotActive'" 1 "'Active'";
VAL_ 2654208005 WakeRsn_TCU 0 "'Diag'" 1 "'Network'" 2 "Remote_Command" 3 "'WakeRsn3'" 4 "'WakeRsn4'" 5 "'WakeRsn5'" 6 "'WakeRsn6'" 7 "'WakeRsn7'" 8 "'WakeRsn8'" 9 "'WakeRsn9'" 10 "'WakeRsn10'" 11 "'WakeRsn11'" 12 "'WakeRsn12'" 13 "'WakeRsn13'" 14 "'WakeRsn14'" 15 "'WakeRsn15'" 16 "'WakeRsn16'" 17 "'WakeRsn17'" 18 "'WakeRsn18'" 19 "'WakeRsn19'" 20 "'WakeRsn20'" 21 "'WakeRsn21'" 22 "'WakeRsn22'" 23 "'WakeRsn23'" 24 "'WakeRsn24'" 25 "'WakeRsn25'" 26 "'WakeRsn26'" 27 "'WakeRsn27'" 28 "'WakeRsn28'" 29 "'WakeRsn29'" 30 "'WakeRsn30'" 31 "'WakeRsn31'" 32 "'WakeRsn32'" 33 "'WakeRsn33'" 34 "'WakeRsn34'" 35 "'WakeRsn35'" 36 "'WakeRsn36'" 37 "'WakeRsn37'" 38 "'WakeRsn38'" 39 "'WakeRsn39'" 40 "'WakeRsn40'" 41 "'WakeRsn41'" 42 "'WakeRsn42'" 43 "'WakeRsn43'" 44 "'WakeRsn44'" 45 "'WakeRsn45'" 46 "'WakeRsn46'" 47 "'WakeRsn47'" 48 "'WakeRsn48'" 49 "'WakeRsn49'" 50 "'WakeRsn50'" 51 "'WakeRsn51'" 52 "'WakeRsn52'" 53 "'WakeRsn53'" 54 "'WakeRsn54'" 55 "'WakeRsn55'" 56 "'WakeRsn56'" 57 "'WakeRsn57'" 58 "'WakeRsn58'" 59 "'WakeRsn59'" 60 "'WakeRsn60'" 61 "'WakeRsn61'" 62 "'WakeRsn62'" 63 "'WakeRsn63'" 64 "'WakeRsn64'" 65 "'WakeRsn65'" 66 "'WakeRsn66'" 67 "'WakeRsn67'" 68 "'WakeRsn68'" 69 "'WakeRsn69'" 70 "'WakeRsn70'" 71 "'WakeRsn71'" 72 "'WakeRsn72'" 73 "'WakeRsn73'" 74 "'WakeRsn74'" 75 "'WakeRsn75'" 76 "'WakeRsn76'" 77 "'WakeRsn77'" 78 "'WakeRsn78'" 79 "'WakeRsn79'" 80 "'WakeRsn80'" 81 "'WakeRsn81'" 82 "'WakeRsn82'" 83 "'WakeRsn83'" 84 "'WakeRsn84'" 85 "'WakeRsn85'" 86 "'WakeRsn86'" 87 "'WakeRsn87'" 88 "'WakeRsn88'" 89 "'WakeRsn89'" 90 "'WakeRsn90'" 91 "'WakeRsn91'" 92 "'WakeRsn92'" 93 "'WakeRsn93'" 94 "'WakeRsn94'" 95 "'WakeRsn95'" 96 "'WakeRsn96'" 97 "'WakeRsn97'" 98 "'WakeRsn98'" 99 "'WakeRsn99'" 100 "'WakeRsn100'" 101 "'WakeRsn101'" 102 "'WakeRsn102'" 103 "'WakeRsn103'" 104 "'WakeRsn104'" 105 "'WakeRsn105'" 106 "'WakeRsn106'" 107 "'WakeRsn107'" 108 "'WakeRsn108'" 109 "'WakeRsn109'" 110 "'WakeRsn110'" 111 "'WakeRsn111'" 112 "'WakeRsn112'" 113 "'WakeRsn113'" 114 "'WakeRsn114'" 115 "'WakeRsn115'" 116 "'WakeRsn116'" 117 "'WakeRsn117'" 118 "'WakeRsn118'" 119 "'WakeRsn119'" 120 "'WakeRsn120'" 121 "'WakeRsn121'" 122 "'WakeRsn122'" 123 "'WakeRsn123'" 124 "'WakeRsn124'" 125 "'WakeRsn125'" 126 "'WakeRsn126'" 127 "'WakeRsn127'";
VAL_ 2654208005 WakeReq_TCU 0 "NotActive" 1 "Active";
VAL_ 2654208007 WakeRsn_NIT 0 "'Diag'" 1 "'Network'" 2 "'WakeRsn2'" 3 "'WakeRsn3'" 4 "'WakeRsn4'" 5 "'WakeRsn5'" 6 "'WakeRsn6'" 7 "'WakeRsn7'" 8 "'WakeRsn8'" 9 "'WakeRsn9'" 10 "'WakeRsn10'" 11 "'WakeRsn11'" 12 "'WakeRsn12'" 13 "'WakeRsn13'" 14 "'WakeRsn14'" 15 "'WakeRsn15'" 16 "'WakeRsn16'" 17 "'WakeRsn17'" 18 "'WakeRsn18'" 19 "'WakeRsn19'" 20 "'WakeRsn20'" 21 "'WakeRsn21'" 22 "'WakeRsn22'" 23 "'WakeRsn23'" 24 "'WakeRsn24'" 25 "'WakeRsn25'" 26 "'WakeRsn26'" 27 "'WakeRsn27'" 28 "'WakeRsn28'" 29 "'WakeRsn29'" 30 "'WakeRsn30'" 31 "'WakeRsn31'" 32 "'WakeRsn32'" 33 "'WakeRsn33'" 34 "'WakeRsn34'" 35 "'WakeRsn35'" 36 "'WakeRsn36'" 37 "'WakeRsn37'" 38 "'WakeRsn38'" 39 "'WakeRsn39'" 40 "'WakeRsn40'" 41 "'WakeRsn41'" 42 "'WakeRsn42'" 43 "'WakeRsn43'" 44 "'WakeRsn44'" 45 "'WakeRsn45'" 46 "'WakeRsn46'" 47 "'WakeRsn47'" 48 "'WakeRsn48'" 49 "'WakeRsn49'" 50 "'WakeRsn50'" 51 "'WakeRsn51'" 52 "'WakeRsn52'" 53 "'WakeRsn53'" 54 "'WakeRsn54'" 55 "'WakeRsn55'" 56 "'WakeRsn56'" 57 "'WakeRsn57'" 58 "'WakeRsn58'" 59 "'WakeRsn59'" 60 "'WakeRsn60'" 61 "'WakeRsn61'" 62 "'WakeRsn62'" 63 "'WakeRsn63'" 64 "'WakeRsn64'" 65 "'WakeRsn65'" 66 "'WakeRsn66'" 67 "'WakeRsn67'" 68 "'WakeRsn68'" 69 "'WakeRsn69'" 70 "'WakeRsn70'" 71 "'WakeRsn71'" 72 "'WakeRsn72'" 73 "'WakeRsn73'" 74 "'WakeRsn74'" 75 "'WakeRsn75'" 76 "'WakeRsn76'" 77 "'WakeRsn77'" 78 "'WakeRsn78'" 79 "'WakeRsn79'" 80 "'WakeRsn80'" 81 "'WakeRsn81'" 82 "'WakeRsn82'" 83 "'WakeRsn83'" 84 "'WakeRsn84'" 85 "'WakeRsn85'" 86 "'WakeRsn86'" 87 "'WakeRsn87'" 88 "'WakeRsn88'" 89 "'WakeRsn89'" 90 "'WakeRsn90'" 91 "'WakeRsn91'" 92 "'WakeRsn92'" 93 "'WakeRsn93'" 94 "'WakeRsn94'" 95 "'WakeRsn95'" 96 "'WakeRsn96'" 97 "'WakeRsn97'" 98 "'WakeRsn98'" 99 "'WakeRsn99'" 100 "'WakeRsn100'" 101 "'WakeRsn101'" 102 "'WakeRsn102'" 103 "'WakeRsn103'" 104 "'WakeRsn104'" 105 "'WakeRsn105'" 106 "'WakeRsn106'" 107 "'WakeRsn107'" 108 "'WakeRsn108'" 109 "'WakeRsn109'" 110 "'WakeRsn110'" 111 "'WakeRsn111'" 112 "'WakeRsn112'" 113 "'WakeRsn113'" 114 "'WakeRsn114'" 115 "'WakeRsn115'" 116 "'WakeRsn116'" 117 "'WakeRsn117'" 118 "'WakeRsn118'" 119 "'WakeRsn119'" 120 "'WakeRsn120'" 121 "'WakeRsn121'" 122 "'WakeRsn122'" 123 "'WakeRsn123'" 124 "'WakeRsn124'" 125 "'WakeRsn125'" 126 "'WakeRsn126'" 127 "'WakeRsn127'";
VAL_ 2654208007 WakeReq_NIT 0 "'NotActive'" 1 "'Active'";
VAL_ 2654208026 WakeRsn_NAB 0 "'Diag'" 1 "'Network'" 2 "'High_DC_Voltage'" 3 "Crash_Output" 4 "'WakeRsn4'" 5 "'WakeRsn5'" 6 "'WakeRsn6'" 7 "'WakeRsn7'" 8 "'WakeRsn8'" 9 "'WakeRsn9'" 10 "'WakeRsn10'" 11 "'WakeRsn11'" 12 "'WakeRsn12'" 13 "'WakeRsn13'" 14 "'WakeRsn14'" 15 "'WakeRsn15'" 16 "'WakeRsn16'" 17 "'WakeRsn17'" 18 "'WakeRsn18'" 19 "'WakeRsn19'" 20 "'WakeRsn20'" 21 "'WakeRsn21'" 22 "'WakeRsn22'" 23 "'WakeRsn23'" 24 "'WakeRsn24'" 25 "'WakeRsn25'" 26 "'WakeRsn26'" 27 "'WakeRsn27'" 28 "'WakeRsn28'" 29 "'WakeRsn29'" 30 "'WakeRsn30'" 31 "'WakeRsn31'" 32 "'WakeRsn32'" 33 "'WakeRsn33'" 34 "'WakeRsn34'" 35 "'WakeRsn35'" 36 "'WakeRsn36'" 37 "'WakeRsn37'" 38 "'WakeRsn38'" 39 "'WakeRsn39'" 40 "'WakeRsn40'" 41 "'WakeRsn41'" 42 "'WakeRsn42'" 43 "'WakeRsn43'" 44 "'WakeRsn44'" 45 "'WakeRsn45'" 46 "'WakeRsn46'" 47 "'WakeRsn47'" 48 "'WakeRsn48'" 49 "'WakeRsn49'" 50 "'WakeRsn50'" 51 "'WakeRsn51'" 52 "'WakeRsn52'" 53 "'WakeRsn53'" 54 "'WakeRsn54'" 55 "'WakeRsn55'" 56 "'WakeRsn56'" 57 "'WakeRsn57'" 58 "'WakeRsn58'" 59 "'WakeRsn59'" 60 "'WakeRsn60'" 61 "'WakeRsn61'" 62 "'WakeRsn62'" 63 "'WakeRsn63'" 64 "'WakeRsn64'" 65 "'WakeRsn65'" 66 "'WakeRsn66'" 67 "'WakeRsn67'" 68 "'WakeRsn68'" 69 "'WakeRsn69'" 70 "'WakeRsn70'" 71 "'WakeRsn71'" 72 "'WakeRsn72'" 73 "'WakeRsn73'" 74 "'WakeRsn74'" 75 "'WakeRsn75'" 76 "'WakeRsn76'" 77 "'WakeRsn77'" 78 "'WakeRsn78'" 79 "'WakeRsn79'" 80 "'WakeRsn80'" 81 "'WakeRsn81'" 82 "'WakeRsn82'" 83 "'WakeRsn83'" 84 "'WakeRsn84'" 85 "'WakeRsn85'" 86 "'WakeRsn86'" 87 "'WakeRsn87'" 88 "'WakeRsn88'" 89 "'WakeRsn89'" 90 "'WakeRsn90'" 91 "'WakeRsn91'" 92 "'WakeRsn92'" 93 "'WakeRsn93'" 94 "'WakeRsn94'" 95 "'WakeRsn95'" 96 "'WakeRsn96'" 97 "'WakeRsn97'" 98 "'WakeRsn98'" 99 "'WakeRsn99'" 100 "'WakeRsn100'" 101 "'WakeRsn101'" 102 "'WakeRsn102'" 103 "'WakeRsn103'" 104 "'WakeRsn104'" 105 "'WakeRsn105'" 106 "'WakeRsn106'" 107 "'WakeRsn107'" 108 "'WakeRsn108'" 109 "'WakeRsn109'" 110 "'WakeRsn110'" 111 "'WakeRsn111'" 112 "'WakeRsn112'" 113 "'WakeRsn113'" 114 "'WakeRsn114'" 115 "'WakeRsn115'" 116 "'WakeRsn116'" 117 "'WakeRsn117'" 118 "'WakeRsn118'" 119 "'WakeRsn119'" 120 "'WakeRsn120'" 121 "'WakeRsn121'" 122 "'WakeRsn122'" 123 "'WakeRsn123'" 124 "'WakeRsn124'" 125 "'WakeRsn125'" 126 "'WakeRsn126'" 127 "'WakeRsn127'";
VAL_ 2654208026 WakeReq_NAB 0 "'NotActive'" 1 "'Active'";
VAL_ 2654208028 WakeRsn_NTP 0 "'Diag'" 1 "'Network'" 2 "'High_DC_Voltage'" 3 "'WakeRsn3'" 4 "'WakeRsn4'" 5 "'WakeRsn5'" 6 "'WakeRsn6'" 7 "'WakeRsn7'" 8 "'WakeRsn8'" 9 "'WakeRsn9'" 10 "'WakeRsn10'" 11 "'WakeRsn11'" 12 "'WakeRsn12'" 13 "'WakeRsn13'" 14 "'WakeRsn14'" 15 "'WakeRsn15'" 16 "'WakeRsn16'" 17 "'WakeRsn17'" 18 "'WakeRsn18'" 19 "'WakeRsn19'" 20 "'WakeRsn20'" 21 "'WakeRsn21'" 22 "'WakeRsn22'" 23 "'WakeRsn23'" 24 "'WakeRsn24'" 25 "'WakeRsn25'" 26 "'WakeRsn26'" 27 "'WakeRsn27'" 28 "'WakeRsn28'" 29 "'WakeRsn29'" 30 "'WakeRsn30'" 31 "'WakeRsn31'" 32 "'WakeRsn32'" 33 "'WakeRsn33'" 34 "'WakeRsn34'" 35 "'WakeRsn35'" 36 "'WakeRsn36'" 37 "'WakeRsn37'" 38 "'WakeRsn38'" 39 "'WakeRsn39'" 40 "'WakeRsn40'" 41 "'WakeRsn41'" 42 "'WakeRsn42'" 43 "'WakeRsn43'" 44 "'WakeRsn44'" 45 "'WakeRsn45'" 46 "'WakeRsn46'" 47 "'WakeRsn47'" 48 "'WakeRsn48'" 49 "'WakeRsn49'" 50 "'WakeRsn50'" 51 "'WakeRsn51'" 52 "'WakeRsn52'" 53 "'WakeRsn53'" 54 "'WakeRsn54'" 55 "'WakeRsn55'" 56 "'WakeRsn56'" 57 "'WakeRsn57'" 58 "'WakeRsn58'" 59 "'WakeRsn59'" 60 "'WakeRsn60'" 61 "'WakeRsn61'" 62 "'WakeRsn62'" 63 "'WakeRsn63'" 64 "'WakeRsn64'" 65 "'WakeRsn65'" 66 "'WakeRsn66'" 67 "'WakeRsn67'" 68 "'WakeRsn68'" 69 "'WakeRsn69'" 70 "'WakeRsn70'" 71 "'WakeRsn71'" 72 "'WakeRsn72'" 73 "'WakeRsn73'" 74 "'WakeRsn74'" 75 "'WakeRsn75'" 76 "'WakeRsn76'" 77 "'WakeRsn77'" 78 "'WakeRsn78'" 79 "'WakeRsn79'" 80 "'WakeRsn80'" 81 "'WakeRsn81'" 82 "'WakeRsn82'" 83 "'WakeRsn83'" 84 "'WakeRsn84'" 85 "'WakeRsn85'" 86 "'WakeRsn86'" 87 "'WakeRsn87'" 88 "'WakeRsn88'" 89 "'WakeRsn89'" 90 "'WakeRsn90'" 91 "'WakeRsn91'" 92 "'WakeRsn92'" 93 "'WakeRsn93'" 94 "'WakeRsn94'" 95 "'WakeRsn95'" 96 "'WakeRsn96'" 97 "'WakeRsn97'" 98 "'WakeRsn98'" 99 "'WakeRsn99'" 100 "'WakeRsn100'" 101 "'WakeRsn101'" 102 "'WakeRsn102'" 103 "'WakeRsn103'" 104 "'WakeRsn104'" 105 "'WakeRsn105'" 106 "'WakeRsn106'" 107 "'WakeRsn107'" 108 "'WakeRsn108'" 109 "'WakeRsn109'" 110 "'WakeRsn110'" 111 "'WakeRsn111'" 112 "'WakeRsn112'" 113 "'WakeRsn113'" 114 "'WakeRsn114'" 115 "'WakeRsn115'" 116 "'WakeRsn116'" 117 "'WakeRsn117'" 118 "'WakeRsn118'" 119 "'WakeRsn119'" 120 "'WakeRsn120'" 121 "'WakeRsn121'" 122 "'WakeRsn122'" 123 "'WakeRsn123'" 124 "'WakeRsn124'" 125 "'WakeRsn125'" 126 "'WakeRsn126'" 127 "'WakeRsn127'";
VAL_ 2654208028 WakeReq_NTP 0 "'NotActive'" 1 "'Active'";
VAL_ 2654208037 WakeRsn_VCU 0 "'Diag'" 1 "'Network'" 2 "Lifter_Functionality" 3 "Speed" 4 "Timer" 5 "HW_RTC" 6 "LED_Charging_Timeout" 7 "LVB_Charging" 8 "HVB_Recharge " 9 "'WakeRsn9'" 10 "Wake_Up_From_Slave" 11 "Thermal" 12 "HMI_ON" 13 "KL15_ON" 14 "'WakeRsn14'" 15 "'WakeRsn15'" 16 "'WakeRsn16'" 17 "'WakeRsn17'" 18 "'WakeRsn18'" 19 "'WakeRsn19'" 20 "'WakeRsn20'" 21 "'WakeRsn21'" 22 "'WakeRsn22'" 23 "'WakeRsn23'" 24 "'WakeRsn24'" 25 "'WakeRsn25'" 26 "'WakeRsn26'" 27 "'WakeRsn27'" 28 "'WakeRsn28'" 29 "'WakeRsn29'" 30 "'WakeRsn30'" 31 "'WakeRsn31'" 32 "'WakeRsn32'" 33 "'WakeRsn33'" 34 "'WakeRsn34'" 35 "'WakeRsn35'" 36 "'WakeRsn36'" 37 "'WakeRsn37'" 38 "'WakeRsn38'" 39 "'WakeRsn39'" 40 "'WakeRsn40'" 41 "'WakeRsn41'" 42 "'WakeRsn42'" 43 "'WakeRsn43'" 44 "'WakeRsn44'" 45 "'WakeRsn45'" 46 "'WakeRsn46'" 47 "'WakeRsn47'" 48 "'WakeRsn48'" 49 "'WakeRsn49'" 50 "'WakeRsn50'" 51 "'WakeRsn51'" 52 "'WakeRsn52'" 53 "'WakeRsn53'" 54 "'WakeRsn54'" 55 "'WakeRsn55'" 56 "'WakeRsn56'" 57 "'WakeRsn57'" 58 "'WakeRsn58'" 59 "'WakeRsn59'" 60 "'WakeRsn60'" 61 "'WakeRsn61'" 62 "'WakeRsn62'" 63 "'WakeRsn63'" 64 "'WakeRsn64'" 65 "'WakeRsn65'" 66 "'WakeRsn66'" 67 "'WakeRsn67'" 68 "'WakeRsn68'" 69 "'WakeRsn69'" 70 "'WakeRsn70'" 71 "'WakeRsn71'" 72 "'WakeRsn72'" 73 "'WakeRsn73'" 74 "'WakeRsn74'" 75 "'WakeRsn75'" 76 "'WakeRsn76'" 77 "'WakeRsn77'" 78 "'WakeRsn78'" 79 "'WakeRsn79'" 80 "'WakeRsn80'" 81 "'WakeRsn81'" 82 "'WakeRsn82'" 83 "'WakeRsn83'" 84 "'WakeRsn84'" 85 "'WakeRsn85'" 86 "'WakeRsn86'" 87 "'WakeRsn87'" 88 "'WakeRsn88'" 89 "'WakeRsn89'" 90 "'WakeRsn90'" 91 "'WakeRsn91'" 92 "'WakeRsn92'" 93 "'WakeRsn93'" 94 "'WakeRsn94'" 95 "'WakeRsn95'" 96 "'WakeRsn96'" 97 "'WakeRsn97'" 98 "'WakeRsn98'" 99 "'WakeRsn99'" 100 "'WakeRsn100'" 101 "'WakeRsn101'" 102 "'WakeRsn102'" 103 "'WakeRsn103'" 104 "'WakeRsn104'" 105 "'WakeRsn105'" 106 "'WakeRsn106'" 107 "'WakeRsn107'" 108 "'WakeRsn108'" 109 "'WakeRsn109'" 110 "'WakeRsn110'" 111 "'WakeRsn111'" 112 "'WakeRsn112'" 113 "'WakeRsn113'" 114 "'WakeRsn114'" 115 "'WakeRsn115'" 116 "'WakeRsn116'" 117 "'WakeRsn117'" 118 "'WakeRsn118'" 119 "'WakeRsn119'" 120 "'WakeRsn120'" 121 "'WakeRsn121'" 122 "'WakeRsn122'" 123 "'WakeRsn123'" 124 "'WakeRsn124'" 125 "'WakeRsn125'" 126 "'WakeRsn126'" 127 "'WakeRsn127'";
VAL_ 2654208037 WakeReq_VCU 0 "'NotActive'" 1 "'Active'";
VAL_ 2654208041 WakeRsn_NDR 0 "'Diag'" 1 "'Network'" 2 "Display_Touch_Pressure" 3 "Button_Pressure" 4 "'WakeRsn4'" 5 "'WakeRsn5'" 6 "'WakeRsn6'" 7 "'WakeRsn7'" 8 "'WakeRsn8'" 9 "'WakeRsn9'" 10 "'WakeRsn10'" 11 "'WakeRsn11'" 12 "'WakeRsn12'" 13 "'WakeRsn13'" 14 "'WakeRsn14'" 15 "'WakeRsn15'" 16 "'WakeRsn16'" 17 "'WakeRsn17'" 18 "'WakeRsn18'" 19 "'WakeRsn19'" 20 "'WakeRsn20'" 21 "'WakeRsn21'" 22 "'WakeRsn22'" 23 "'WakeRsn23'" 24 "'WakeRsn24'" 25 "'WakeRsn25'" 26 "'WakeRsn26'" 27 "'WakeRsn27'" 28 "'WakeRsn28'" 29 "'WakeRsn29'" 30 "'WakeRsn30'" 31 "'WakeRsn31'" 32 "'WakeRsn32'" 33 "'WakeRsn33'" 34 "'WakeRsn34'" 35 "'WakeRsn35'" 36 "'WakeRsn36'" 37 "'WakeRsn37'" 38 "'WakeRsn38'" 39 "'WakeRsn39'" 40 "'WakeRsn40'" 41 "'WakeRsn41'" 42 "'WakeRsn42'" 43 "'WakeRsn43'" 44 "'WakeRsn44'" 45 "'WakeRsn45'" 46 "'WakeRsn46'" 47 "'WakeRsn47'" 48 "'WakeRsn48'" 49 "'WakeRsn49'" 50 "'WakeRsn50'" 51 "'WakeRsn51'" 52 "'WakeRsn52'" 53 "'WakeRsn53'" 54 "'WakeRsn54'" 55 "'WakeRsn55'" 56 "'WakeRsn56'" 57 "'WakeRsn57'" 58 "'WakeRsn58'" 59 "'WakeRsn59'" 60 "'WakeRsn60'" 61 "'WakeRsn61'" 62 "'WakeRsn62'" 63 "'WakeRsn63'" 64 "'WakeRsn64'" 65 "'WakeRsn65'" 66 "'WakeRsn66'" 67 "'WakeRsn67'" 68 "'WakeRsn68'" 69 "'WakeRsn69'" 70 "'WakeRsn70'" 71 "'WakeRsn71'" 72 "'WakeRsn72'" 73 "'WakeRsn73'" 74 "'WakeRsn74'" 75 "'WakeRsn75'" 76 "'WakeRsn76'" 77 "'WakeRsn77'" 78 "'WakeRsn78'" 79 "'WakeRsn79'" 80 "'WakeRsn80'" 81 "'WakeRsn81'" 82 "'WakeRsn82'" 83 "'WakeRsn83'" 84 "'WakeRsn84'" 85 "'WakeRsn85'" 86 "'WakeRsn86'" 87 "'WakeRsn87'" 88 "'WakeRsn88'" 89 "'WakeRsn89'" 90 "'WakeRsn90'" 91 "'WakeRsn91'" 92 "'WakeRsn92'" 93 "'WakeRsn93'" 94 "'WakeRsn94'" 95 "'WakeRsn95'" 96 "'WakeRsn96'" 97 "'WakeRsn97'" 98 "'WakeRsn98'" 99 "'WakeRsn99'" 100 "'WakeRsn100'" 101 "'WakeRsn101'" 102 "'WakeRsn102'" 103 "'WakeRsn103'" 104 "'WakeRsn104'" 105 "'WakeRsn105'" 106 "'WakeRsn106'" 107 "'WakeRsn107'" 108 "'WakeRsn108'" 109 "'WakeRsn109'" 110 "'WakeRsn110'" 111 "'WakeRsn111'" 112 "'WakeRsn112'" 113 "'WakeRsn113'" 114 "'WakeRsn114'" 115 "'WakeRsn115'" 116 "'WakeRsn116'" 117 "'WakeRsn117'" 118 "'WakeRsn118'" 119 "'WakeRsn119'" 120 "'WakeRsn120'" 121 "'WakeRsn121'" 122 "'WakeRsn122'" 123 "'WakeRsn123'" 124 "'WakeRsn124'" 125 "'WakeRsn125'" 126 "'WakeRsn126'" 127 "'WakeRsn127'";
VAL_ 2654208041 WakeReq_NDR 0 "NotActive" 1 "Active";
VAL_ 2654208084 WakeRsn_NDRR 0 "'Diag'" 1 "'Network'" 2 "Display_Touch_Pressure" 3 "Button_Pressure" 4 "'WakeRsn4'" 5 "'WakeRsn5'" 6 "'WakeRsn6'" 7 "'WakeRsn7'" 8 "'WakeRsn8'" 9 "'WakeRsn9'" 10 "'WakeRsn10'" 11 "'WakeRsn11'" 12 "'WakeRsn12'" 13 "'WakeRsn13'" 14 "'WakeRsn14'" 15 "'WakeRsn15'" 16 "'WakeRsn16'" 17 "'WakeRsn17'" 18 "'WakeRsn18'" 19 "'WakeRsn19'" 20 "'WakeRsn20'" 21 "'WakeRsn21'" 22 "'WakeRsn22'" 23 "'WakeRsn23'" 24 "'WakeRsn24'" 25 "'WakeRsn25'" 26 "'WakeRsn26'" 27 "'WakeRsn27'" 28 "'WakeRsn28'" 29 "'WakeRsn29'" 30 "'WakeRsn30'" 31 "'WakeRsn31'" 32 "'WakeRsn32'" 33 "'WakeRsn33'" 34 "'WakeRsn34'" 35 "'WakeRsn35'" 36 "'WakeRsn36'" 37 "'WakeRsn37'" 38 "'WakeRsn38'" 39 "'WakeRsn39'" 40 "'WakeRsn40'" 41 "'WakeRsn41'" 42 "'WakeRsn42'" 43 "'WakeRsn43'" 44 "'WakeRsn44'" 45 "'WakeRsn45'" 46 "'WakeRsn46'" 47 "'WakeRsn47'" 48 "'WakeRsn48'" 49 "'WakeRsn49'" 50 "'WakeRsn50'" 51 "'WakeRsn51'" 52 "'WakeRsn52'" 53 "'WakeRsn53'" 54 "'WakeRsn54'" 55 "'WakeRsn55'" 56 "'WakeRsn56'" 57 "'WakeRsn57'" 58 "'WakeRsn58'" 59 "'WakeRsn59'" 60 "'WakeRsn60'" 61 "'WakeRsn61'" 62 "'WakeRsn62'" 63 "'WakeRsn63'" 64 "'WakeRsn64'" 65 "'WakeRsn65'" 66 "'WakeRsn66'" 67 "'WakeRsn67'" 68 "'WakeRsn68'" 69 "'WakeRsn69'" 70 "'WakeRsn70'" 71 "'WakeRsn71'" 72 "'WakeRsn72'" 73 "'WakeRsn73'" 74 "'WakeRsn74'" 75 "'WakeRsn75'" 76 "'WakeRsn76'" 77 "'WakeRsn77'" 78 "'WakeRsn78'" 79 "'WakeRsn79'" 80 "'WakeRsn80'" 81 "'WakeRsn81'" 82 "'WakeRsn82'" 83 "'WakeRsn83'" 84 "'WakeRsn84'" 85 "'WakeRsn85'" 86 "'WakeRsn86'" 87 "'WakeRsn87'" 88 "'WakeRsn88'" 89 "'WakeRsn89'" 90 "'WakeRsn90'" 91 "'WakeRsn91'" 92 "'WakeRsn92'" 93 "'WakeRsn93'" 94 "'WakeRsn94'" 95 "'WakeRsn95'" 96 "'WakeRsn96'" 97 "'WakeRsn97'" 98 "'WakeRsn98'" 99 "'WakeRsn99'" 100 "'WakeRsn100'" 101 "'WakeRsn101'" 102 "'WakeRsn102'" 103 "'WakeRsn103'" 104 "'WakeRsn104'" 105 "'WakeRsn105'" 106 "'WakeRsn106'" 107 "'WakeRsn107'" 108 "'WakeRsn108'" 109 "'WakeRsn109'" 110 "'WakeRsn110'" 111 "'WakeRsn111'" 112 "'WakeRsn112'" 113 "'WakeRsn113'" 114 "'WakeRsn114'" 115 "'WakeRsn115'" 116 "'WakeRsn116'" 117 "'WakeRsn117'" 118 "'WakeRsn118'" 119 "'WakeRsn119'" 120 "'WakeRsn120'" 121 "'WakeRsn121'" 122 "'WakeRsn122'" 123 "'WakeRsn123'" 124 "'WakeRsn124'" 125 "'WakeRsn125'" 126 "'WakeRsn126'" 127 "'WakeRsn127'";
VAL_ 2654208084 WakeReq_NDRR 0 "NotActive" 1 "Active";
VAL_ 2654208089 WakeRsn_SGW 0 "'Diag'" 1 "'Network'" 2 "Response_From_ECU" 3 "'WakeRsn3'" 4 "'WakeRsn4'" 5 "'WakeRsn5'" 6 "'WakeRsn6'" 7 "'WakeRsn7'" 8 "'WakeRsn8'" 9 "'WakeRsn9'" 10 "'WakeRsn10'" 11 "'WakeRsn11'" 12 "'WakeRsn12'" 13 "'WakeRsn13'" 14 "'WakeRsn14'" 15 "'WakeRsn15'" 16 "'WakeRsn16'" 17 "'WakeRsn17'" 18 "'WakeRsn18'" 19 "'WakeRsn19'" 20 "'WakeRsn20'" 21 "'WakeRsn21'" 22 "'WakeRsn22'" 23 "'WakeRsn23'" 24 "'WakeRsn24'" 25 "'WakeRsn25'" 26 "'WakeRsn26'" 27 "'WakeRsn27'" 28 "'WakeRsn28'" 29 "'WakeRsn29'" 30 "'WakeRsn30'" 31 "'WakeRsn31'" 32 "'WakeRsn32'" 33 "'WakeRsn33'" 34 "'WakeRsn34'" 35 "'WakeRsn35'" 36 "'WakeRsn36'" 37 "'WakeRsn37'" 38 "'WakeRsn38'" 39 "'WakeRsn39'" 40 "'WakeRsn40'" 41 "'WakeRsn41'" 42 "'WakeRsn42'" 43 "'WakeRsn43'" 44 "'WakeRsn44'" 45 "'WakeRsn45'" 46 "'WakeRsn46'" 47 "'WakeRsn47'" 48 "'WakeRsn48'" 49 "'WakeRsn49'" 50 "'WakeRsn50'" 51 "'WakeRsn51'" 52 "'WakeRsn52'" 53 "'WakeRsn53'" 54 "'WakeRsn54'" 55 "'WakeRsn55'" 56 "'WakeRsn56'" 57 "'WakeRsn57'" 58 "'WakeRsn58'" 59 "'WakeRsn59'" 60 "'WakeRsn60'" 61 "'WakeRsn61'" 62 "'WakeRsn62'" 63 "'WakeRsn63'" 64 "'WakeRsn64'" 65 "'WakeRsn65'" 66 "'WakeRsn66'" 67 "'WakeRsn67'" 68 "'WakeRsn68'" 69 "'WakeRsn69'" 70 "'WakeRsn70'" 71 "'WakeRsn71'" 72 "'WakeRsn72'" 73 "'WakeRsn73'" 74 "'WakeRsn74'" 75 "'WakeRsn75'" 76 "'WakeRsn76'" 77 "'WakeRsn77'" 78 "'WakeRsn78'" 79 "'WakeRsn79'" 80 "'WakeRsn80'" 81 "'WakeRsn81'" 82 "'WakeRsn82'" 83 "'WakeRsn83'" 84 "'WakeRsn84'" 85 "'WakeRsn85'" 86 "'WakeRsn86'" 87 "'WakeRsn87'" 88 "'WakeRsn88'" 89 "'WakeRsn89'" 90 "'WakeRsn90'" 91 "'WakeRsn91'" 92 "'WakeRsn92'" 93 "'WakeRsn93'" 94 "'WakeRsn94'" 95 "'WakeRsn95'" 96 "'WakeRsn96'" 97 "'WakeRsn97'" 98 "'WakeRsn98'" 99 "'WakeRsn99'" 100 "'WakeRsn100'" 101 "'WakeRsn101'" 102 "'WakeRsn102'" 103 "'WakeRsn103'" 104 "'WakeRsn104'" 105 "'WakeRsn105'" 106 "'WakeRsn106'" 107 "'WakeRsn107'" 108 "'WakeRsn108'" 109 "'WakeRsn109'" 110 "'WakeRsn110'" 111 "'WakeRsn111'" 112 "'WakeRsn112'" 113 "'WakeRsn113'" 114 "'WakeRsn114'" 115 "'WakeRsn115'" 116 "'WakeRsn116'" 117 "'WakeRsn117'" 118 "'WakeRsn118'" 119 "'WakeRsn119'" 120 "'WakeRsn120'" 121 "'WakeRsn121'" 122 "'WakeRsn122'" 123 "'WakeRsn123'" 124 "'WakeRsn124'" 125 "'WakeRsn125'" 126 "'WakeRsn126'" 127 "'WakeRsn127'";
VAL_ 2654208089 WakeReq_SGW 0 "'NotActive'" 1 "'Active'";
VAL_ 2654339074 GenericFailSts 0 "No_functional_fail_is_present" 1 "At_least_one_funct_fail_pres";
VAL_ 2654339074 CurrentFailSts 0 "No_functional_fail_is_present" 1 "DTCStatus_present";
VAL_ 2654339074 EOL_NGE 0 "No_EOL_prog_At_FIAT" 1 "EOL_prog_At_FIAT";
VAL_ 2654339074 DES_NGE 0 "Error_active_state" 1 "Error_Passive_warning_state" 2 "Bus_off_state" 3 "Not_used";
VAL_ 2654339074 ElectricSteeringFailSts 0 "Fail_not_Present" 1 "Fail_Present";
VAL_ 2654339074 NGE_Display_Info 0 "Normal" 1 "Derating" 2 "not_used" 3 "not_used" 4 "not_used" 5 "not_used" 6 "not_used" 7 "not_used";
VAL_ 2654339075 GenericFailSts_NQS 0 "No_functional_fail_is_present" 1 "At_least_one_funct_fail_pres";
VAL_ 2654339075 CurrentFailSts_NQS 0 "No_functional_fail_is_present" 1 "DTCStatus_present";
VAL_ 2654339075 EOL_NQS 0 "No_EOL_prog_At_FIAT" 1 "EOL_prog_At_FIAT";
VAL_ 2654339075 DES_NQS 0 "Error_active_state" 1 "Error_Passive_warning_state" 2 "Bus_off_state" 3 "Not_used";
VAL_ 2654339077 GenericFailSts_TCU 0 "No_functional_fail_is_present" 1 "At_least_one_funct_fail_pres";
VAL_ 2654339077 CurrentFailSts_TCU 0 "No_functional_fail_is_present" 1 "DTCStatus_present";
VAL_ 2654339077 EOL_TCU 0 "No_EOL_prog_At_FIAT" 1 "EOL_prog_At_FIAT";
VAL_ 2654339077 DES_TCU 0 "Error_active_state" 1 "Error_Passive_warning_state" 2 "Bus_off_state" 3 "Not_used";
VAL_ 2654339079 GenericFailSts_IDC 0 "No_functional_fail_is_present" 1 "At_least_one_funct_fail_pres";
VAL_ 2654339079 CurrentFailSts_IDC 0 "No_functional_fail_is_present" 1 "DTCStatus_present";
VAL_ 2654339079 EOL_IDC 0 "No_EOL_prog_At_FIAT" 1 "EOL_prog_At_FIAT";
VAL_ 2654339079 DES_IDC 0 "Error_active_state" 1 "Error_Passive_warning_state" 2 "Bus_off_state" 3 "Not_used";
VAL_ 2654339092 GenericFailSts_HVB 0 "No_functional_fail_is_present" 1 "At_least_one_funct_failure";
VAL_ 2654339092 CurrentFailSts_HVB 0 "No_functional_fail_is_present" 1 "DTCStatus_present";
VAL_ 2654339092 EOL_HVB 0 "No_EOL_prog_At_FIAT" 1 "EOL_prog_At_FIAT";
VAL_ 2654339092 DES_HVB 0 "Error_active_state" 1 "Error_Passive_warning_state" 2 "Bus_off_state" 3 "Not_used";
VAL_ 2654339092 HVB_Crash_Output 0 "Not_Active" 1 "Active";
VAL_ 2654339098 GenericFailSts 0 "No_functional_fail_is_present" 1 "At_least_one_funct_fail_pres";
VAL_ 2654339098 CurrentFailSts 0 "No_functional_fail_is_present" 1 "DTCStatus_present";
VAL_ 2654339098 EOL_NAB 0 "No_EOL_prog_At_FIAT" 1 "EOL_prog_At_FIAT";
VAL_ 2654339098 DES_NAB 0 "Error_active_state" 1 "Error_Passive_warning_state" 2 "Bus_off_state" 3 "Not_used";
VAL_ 2654339100 GenericFailSts_NTP 0 "No_functional_fail_is_present" 1 "At_least_one_funct_failure";
VAL_ 2654339100 CurrentFailSts_NTP 0 "No_functional_fail_is_present" 1 "DTCStatus_present";
VAL_ 2654339100 EOL_NTP 0 "No_EOL_prog_At_FIAT" 1 "EOL_prog_At_FIAT";
VAL_ 2654339100 DES_NTP 0 "Error_active_state" 1 "Error_Passive_warning_state" 2 "Bus_off_state" 3 "Not_used";
VAL_ 2654339102 GenericFailSts_HALF 0 "No_functional_fail_is_present" 1 "At_least_one_funct_failure";
VAL_ 2654339102 CurrentFailSts_HALF 0 "No_functional_fail_is_present" 1 "DTCStatus_present";
VAL_ 2654339102 EOL_HALF 0 "No_EOL_prog_At_FIAT" 1 "EOL_prog_At_FIAT";
VAL_ 2654339102 DES_HALF 0 "Error_active_state" 1 "Error_Passive_warning_state" 2 "Bus_off_state" 3 "Not_used";
VAL_ 2654339109 GenericFailSts_VCU 0 "No_functional_fail_is_present" 1 "At_least_one_funct_fail_pres";
VAL_ 2654339109 CurrentFailSts_VCU 0 "No_functional_fail_is_present" 1 "DTCStatus_present";
VAL_ 2654339109 EOL_VCU 0 "No_EOL_prog_At_FIAT" 1 "EOL_prog_At_FIAT";
VAL_ 2654339109 DES_VCU 0 "Error_active_state" 1 "Error_Passive_warning_state" 2 "Bus_off_state" 3 "Not_used";
VAL_ 2654339109 VCUActivityInProgress 0 "NotActive" 1 "Active";
VAL_ 2654339110 GenericFailSts_P4RL 0 "No_functional_fail_is_present" 1 "At_least_one_funct_fail_pres";
VAL_ 2654339110 CurrentFailSts_P4RL 0 "No_functional_fail_is_present" 1 "DTCStatus_present";
VAL_ 2654339110 EOL_P4RL 0 "No_EOL_prog_At_FIAT" 1 "EOL_prog_At_FIAT";
VAL_ 2654339110 DES_P4RL 0 "Error_active_state" 1 "Error_Passive_warning_state" 2 "Bus_off_state" 3 "Not_used";
VAL_ 2654339111 GenericFailSts_P4RR 0 "No_functional_fail_is_present" 1 "At_least_one_funct_fail_pres";
VAL_ 2654339111 CurrentFailSts_P4RR 0 "No_functional_fail_is_present" 1 "DTCStatus_present";
VAL_ 2654339111 EOL_P4RR 0 "No_EOL_prog_At_FIAT" 1 "EOL_prog_At_FIAT";
VAL_ 2654339111 DES_P4RR 0 "Error_active_state" 1 "Error_Passive_warning_state" 2 "Bus_off_state" 3 "Not_used";
VAL_ 2654339113 GenericFailSts_NDR 0 "No_functional_fail_is_present" 1 "At_least_one_funct_fail_pres";
VAL_ 2654339113 CurrentFailSts_NDR 0 "No_functional_fail_is_present" 1 "DTCStatus_present";
VAL_ 2654339113 EOL_NDR 0 "No_EOL_prog_At_FIAT" 1 "EOL_prog_At_FIAT";
VAL_ 2654339113 DES_NDR 0 "Error_active_state" 1 "Error_Passive_warning_state" 2 "Bus_off_state" 3 "Not_used";
VAL_ 2654339121 GenericFailSts_OBC 0 "No_functional_fail_is_present" 1 "At_least_one_funct_failure";
VAL_ 2654339121 CurrentFailSts_OBC 0 "No_functional_fail_is_present" 1 "DTCStatus_present";
VAL_ 2654339121 EOL_OBC 0 "No_EOL_prog_At_FIAT" 1 "EOL_prog_At_FIAT";
VAL_ 2654339121 DES_OBC 0 "Error_active_state" 1 "Error_Passive_warning_state" 2 "Bus_off_state" 3 "Not_used";
VAL_ 2654339123 GenericFailSts_P4L 0 "No_functional_fail_is_present" 1 "At_least_one_funct_failure";
VAL_ 2654339123 CurrentFailSts_P4L 0 "No_functional_fail_is_present" 1 "DTCStatus_present";
VAL_ 2654339123 EOL_P4L 0 "No_EOL_prog_At_FIAT" 1 "EOL_prog_At_FIAT";
VAL_ 2654339123 DES_P4L 0 "Error_active_state" 1 "Error_Passive_warning_state" 2 "Bus_off_state" 3 "Not_used";
VAL_ 2654339124 GenericFailSts_P4R 0 "No_functional_fail_is_present" 1 "At_least_one_funct_failure";
VAL_ 2654339124 CurrentFailSts_P4R 0 "No_functional_fail_is_present" 1 "DTCStatus_present";
VAL_ 2654339124 EOL_P4R 0 "No_EOL_prog_At_FIAT" 1 "EOL_prog_At_FIAT";
VAL_ 2654339124 DES_P4R 0 "Error_active_state" 1 "Error_Passive_warning_state" 2 "Bus_off_state" 3 "Not_used";
VAL_ 2654339129 GenericFailSts_DASM 0 "No_functional_fail_is_present" 1 "At_least_one_funct_failure";
VAL_ 2654339129 CurrentFailSts_DASM 0 "No_functional_fail_is_present" 1 "DTCStatus_present";
VAL_ 2654339129 EOL_DASM 0 "No_EOL_prog_At_FIAT" 1 "EOL_prog_At_FIAT";
VAL_ 2654339129 DES_DASM 0 "Error_active_state" 1 "Error_Passive_warning_state" 2 "Bus_off_state" 3 "Not_used";
VAL_ 2654339144 GenericFailSts_SFL 0 "No_functional_fail_is_present" 1 "At_least_one_funct_failure";
VAL_ 2654339144 CurrentFailSts_SFL 0 "No_functional_fail_is_present" 1 "DTCStatus_present";
VAL_ 2654339144 EOL_SFL 0 "No_EOL_prog_At_FIAT" 1 "EOL_prog_At_FIAT";
VAL_ 2654339144 DES_SFL 0 "Error_active_state" 1 "Error_Passive_warning_state" 2 "Bus_off_state" 3 "Not_used";
VAL_ 2654339144 MotorMaxTemp_SFL 255 "Invalid";
VAL_ 2654339144 MotorOverTemp_SFL 0 "no_Fault" 1 "Over_Threshold" 2 "Over_Limit" 3 "Sensor_Fault";
VAL_ 2654339144 DiagnosticFlag_SFL 0 "Not_Active_Diagnostic_Session" 1 "Active_Diagnostic_Session";
VAL_ 2654339144 ECUOverTemp_SFL 0 "no_Fault" 1 "Over_Threshold" 2 "Over_Limit" 3 "Sensor_Fault";
VAL_ 2654339144 MotorAvgTemp_SFL 255 "Invalid";
VAL_ 2654339145 GenericFailSts_SFR 0 "No_functional_fail_is_present" 1 "At_least_one_funct_failure";
VAL_ 2654339145 CurrentFailSts_SFR 0 "No_functional_fail_is_present" 1 "DTCStatus_present";
VAL_ 2654339145 EOL_SFR 0 "No_EOL_prog_At_FIAT" 1 "EOL_prog_At_FIAT";
VAL_ 2654339145 DES_SFR 0 "Error_active_state" 1 "Error_Passive_warning_state" 2 "Bus_off_state" 3 "Not_used";
VAL_ 2654339145 MotorMaxTemp_SFR 255 "Invalid";
VAL_ 2654339145 MotorOverTemp_SFR 0 "no_Fault" 1 "Over_Threshold" 2 "Over_Limit" 3 "Sensor_Fault";
VAL_ 2654339145 DiagnosticFlag_SFR 0 "Not_Active_Diagnostic_Session" 1 "Active_Diagnostic_Session";
VAL_ 2654339145 ECUOverTemp_SFR 0 "no_Fault" 1 "Over_Threshold" 2 "Over_Limit" 3 "Sensor_Fault";
VAL_ 2654339145 MotorAvgTemp_SFR 255 "Invalid";
VAL_ 2654339146 GenericFailSts_SRL 0 "No_functional_fail_is_present" 1 "At_least_one_funct_failure";
VAL_ 2654339146 CurrentFailSts_SRL 0 "No_functional_fail_is_present" 1 "DTCStatus_present";
VAL_ 2654339146 EOL_SRL 0 "No_EOL_prog_At_FIAT" 1 "EOL_prog_At_FIAT";
VAL_ 2654339146 DES_SRL 0 "Error_active_state" 1 "Error_Passive_warning_state" 2 "Bus_off_state" 3 "Not_used";
VAL_ 2654339146 MotorMaxTemp_SRL 255 "Invalid";
VAL_ 2654339146 MotorOverTemp_SRL 0 "no_Fault" 1 "Over_Threshold" 2 "Over_Limit" 3 "Sensor_Fault";
VAL_ 2654339146 DiagnosticFlag_SRL 0 "Not_Active_Diagnostic_Session" 1 "Active_Diagnostic_Session";
VAL_ 2654339146 ECUOverTemp_SRL 0 "no_Fault" 1 "Over_Threshold" 2 "Over_Limit" 3 "Sensor_Fault";
VAL_ 2654339146 MotorAvgTemp_SRL 255 "Invalid";
VAL_ 2654339147 GenericFailSts_SRR 0 "No_functional_fail_is_present" 1 "At_least_one_funct_failure";
VAL_ 2654339147 CurrentFailSts_SRR 0 "No_functional_fail_is_present" 1 "DTCStatus_present";
VAL_ 2654339147 EOL_SRR 0 "No_EOL_prog_At_FIAT" 1 "EOL_prog_At_FIAT";
VAL_ 2654339147 DES_SRR 0 "Error_active_state" 1 "Error_Passive_warning_state" 2 "Bus_off_state" 3 "Not_used";
VAL_ 2654339147 MotorMaxTemp_SRR 255 "Invalid";
VAL_ 2654339147 MotorOverTemp_SRR 0 "no_Fault" 1 "Over_Threshold" 2 "Over_Limit" 3 "Sensor_Fault";
VAL_ 2654339147 DiagnosticFlag_SRR 0 "Not_Active_Diagnostic_Session" 1 "Active_Diagnostic_Session";
VAL_ 2654339147 ECUOverTemp_SRR 0 "no_Fault" 1 "Over_Threshold" 2 "Over_Limit" 3 "Sensor_Fault";
VAL_ 2654339147 MotorAvgTemp_SRR 255 "Invalid";
VAL_ 2654339156 GenericFailSts_NDRR 0 "No_functional_fail_is_present" 1 "At_least_one_funct_fail_pres";
VAL_ 2654339156 CurrentFailSts_NDRR 0 "No_functional_fail_is_present" 1 "DTCStatus_present";
VAL_ 2654339156 EOL_NDRR 0 "No_EOL_prog_At_FIAT" 1 "EOL_prog_At_FIAT";
VAL_ 2654339156 DES_NDRR 0 "Error_active_state" 1 "Error_Passive_warning_state" 2 "Bus_off_state" 3 "Not_used";
VAL_ 2654339161 GenericFailSts_SGW 0 "No_functional_fail_is_present" 1 "At_least_one_funct_fail_pres";
VAL_ 2654339161 CurrentFailSts_SGW 0 "No_functional_fail_is_present" 1 "DTCStatus_present";
VAL_ 2654339161 EOL_SGW 0 "No_EOL_prog_At_FIAT" 1 "EOL_prog_At_FIAT";
VAL_ 2654339161 DES_SGW 0 "Error_active_state" 1 "Error_Passive_warning_state" 2 "Bus_off_state" 3 "Not_used";
VAL_ 2654339182 GenericFailSts_FAUF 0 "No_functional_fail_is_present" 1 "At_least_one_funct_fail_pres";
VAL_ 2654339182 CurrentFailSts_FAUF 0 "No_functional_fail_is_present" 1 "DTCStatus_present";
VAL_ 2654339182 EOL_FAUF 0 "No_EOL_prog_At_FIAT" 1 "EOL_prog_At_FIAT";
VAL_ 2654339182 DES_FAUF 0 "Error_active_state" 1 "Error_Passive_warning_state" 2 "Bus_off_state" 3 "Not_used";
VAL_ 2654339183 GenericFailSts_FAUR 0 "No_functional_fail_is_present" 1 "At_least_one_funct_fail_pres";
VAL_ 2654339183 CurrentFailSts_FAUR 0 "No_functional_fail_is_present" 1 "DTCStatus_present";
VAL_ 2654339183 EOL_FAUR 0 "No_EOL_prog_At_FIAT" 1 "EOL_prog_At_FIAT";
VAL_ 2654339183 DES_FAUR 0 "Error_active_state" 1 "Error_Passive_warning_state" 2 "Bus_off_state" 3 "Not_used";
VAL_ 2654339195 GenericFailSts_PCU_LH 0 "No_functional_fail_is_present" 1 "At_least_one_funct_failure";
VAL_ 2654339195 CurrentFailSts_PCU_LH 0 "No_functional_fail_is_present" 1 "DTCStatus_present";
VAL_ 2654339195 EOL_PCU_LH 0 "No_EOL_prog_At_FIAT" 1 "EOL_prog_At_FIAT";
VAL_ 2654339195 DES_PCU_LH 0 "Error_active_state" 1 "Error_Passive_warning_state" 2 "Bus_off_state" 3 "Not_used";
VAL_ 2654339197 GenericFailSts_BES 0 "No_functional_fail_is_present" 1 "At_least_one_funct_fail_pres";
VAL_ 2654339197 CurrentFailSts_BES 0 "No_functional_fail_is_present" 1 "DTCStatus_present";
VAL_ 2654339197 EOL_BES 0 "No_EOL_prog_At_FIAT" 1 "EOL_prog_At_FIAT";
VAL_ 2654339197 D_ES_BES 0 "Error_Active_State" 1 "Error_Passive_Warning_State" 2 "Bus_Off_State" 3 "Not_used";
SIG_GROUP_  1722 STATUS_TCU_SigGroup 1 : CRC_STATUS_TCU MsgCnt_STATUS_TCU PowerModeSts_TCU SignalStrength TCUFailSts TCUModemSts;
